VERSION ""

NS_ :

BS_:

BU_: AGSM ECM EVCU2 MCPA MCPB SGCP TCM

BO_ 1064 SGCP_DATA2: 64 SGCP
 SG_ SGCP_Temp : 7|8@0+ (1,-40) [-40|215] "°C"  EVCU2
 SG_ SGCP_Rotor_Temperature : 31|8@0+ (1,-40) [-40|215] "°C"  EVCU2
 SG_ SGCP_Inverter_Temp : 15|8@0+ (1,-40) [-40|215] "°C"  EVCU2
 SG_ SGCP_Control_Board_Temperature : 23|8@0+ (1,-40) [-40|215] "°C"  EVCU2
 SG_ MessageCounter_SGCP_DATA2 : 435|4@0+ (1,0) [0|15] ""  EVCU2
 SG_ CRC_SGCP_DATA2 : 447|8@0+ (1,0) [0|255] ""  EVCU2
 SG_ CLrDiagInfo_SGCP : 248|1@0+ (1,0) [0|1] ""  EVCU2
 SG_ SGCP_Service_Lamp_Request : 39|1@0+ (1,0) [0|1] ""  EVCU2
 SG_ Genrtr_PIM_DC_Side_Busbar_Temp : 55|8@0+ (1,-40) [-40|214] "°C"  EVCU2
 SG_ Genrtr_PIM_AC_Side_Busbar_Temp : 47|8@0+ (1,-40) [-40|214] "°C"  EVCU2

BO_ 263 PT_SYSTEM_FD_1: 64 EVCU2
 SG_ OptimdStrtReqdActr : 2|3@0+ (1,0) [0|7] ""  ECM
 SG_ OptimdEngStrtStpType : 7|5@0+ (1,0) [0|31] ""  ECM
 SG_ OptimdEngOnOffCmd : 15|1@0+ (1,0) [0|1] ""  ECM
 SG_ Hyb_ProducingTorque : 13|1@0+ (1,0) [0|1] ""  ECM
 SG_ HCPFuelDisable : 14|1@0+ (1,0) [0|1] ""  ECM
 SG_ PowertrainPrplsnActv_PT : 146|1@0+ (1,0) [0|1] "" Vector__XXX
 SG_ GearEngagedForDisplay_PT : 12|5@0+ (1,0) [0|31] ""  AGSM
 SG_ GearEngaged_PT : 132|4@0+ (1,0) [0|15] ""  MCPB
 SG_ ParkCmd_PT : 151|2@0+ (1,0) [0|3] ""  MCPB
 SG_ TransmissionFailSts_PT : 152|1@0+ (1,0) [0|1] ""  AGSM
 SG_ TerrainModeStat_PT : 119|5@0+ (1,0) [0|31] "" Vector__XXX
 SG_ ShiftLeverPosition_PT : 51|4@0+ (1,0) [0|15] ""  AGSM
 SG_ ShiftLeverLockReq_PT : 155|1@0+ (1,0) [0|1] ""  AGSM
 SG_ MessageCounter_PT_SYSTEM_FD_1 : 435|4@0+ (1,0) [0|15] "-"  MCPB,AGSM,ECM
 SG_ GearIndicationSts_PT : 153|1@0+ (1,0) [0|1] ""  AGSM
 SG_ GasPedalPositionFailSts_PT : 145|1@0+ (1,0) [0|1] ""  ECM
 SG_ GasPedalPosition_PT : 31|8@0+ (0.392,0) [0|99.96] "%"  ECM
 SG_ CRC_PT_SYSTEM_FD_1 : 447|8@0+ (1,0) [0|255] "-"  MCPB,AGSM,ECM
 SG_ APCM_Rq_PT : 137|2@0+ (1,0) [0|3] ""  AGSM

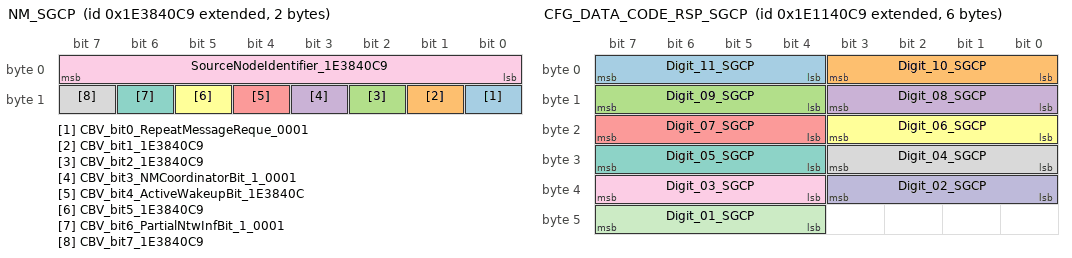
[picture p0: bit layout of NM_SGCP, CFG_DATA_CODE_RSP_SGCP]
BO_ 2654486729 NM_SGCP: 2 SGCP
 SG_ CBV_bit0_RepeatMessageReque_0001 : 8|1@0+ (1,0) [0|1] ""  EVCU2,MCPB,MCPA
 SG_ CBV_bit1_1E3840C9 : 9|1@0+ (1,0) [0|1] ""  EVCU2,MCPB,MCPA
 SG_ CBV_bit2_1E3840C9 : 10|1@0+ (1,0) [0|1] ""  EVCU2,MCPB,MCPA
 SG_ CBV_bit3_NMCoordinatorBit_1_0001 : 11|1@0+ (1,0) [0|1] ""  EVCU2,MCPB,MCPA
 SG_ CBV_bit4_ActiveWakeupBit_1E3840C : 12|1@0+ (1,0) [0|1] ""  EVCU2,MCPB,MCPA
 SG_ CBV_bit5_1E3840C9 : 13|1@0+ (1,0) [0|1] ""  EVCU2,MCPB,MCPA
 SG_ CBV_bit6_PartialNtwInfBit_1_0001 : 14|1@0+ (1,0) [0|1] ""  EVCU2,MCPB,MCPA
 SG_ CBV_bit7_1E3840C9 : 15|1@0+ (1,0) [0|1] ""  EVCU2,MCPB,MCPA
 SG_ SourceNodeIdentifier_1E3840C9 : 7|8@0+ (1,0) [0|255] "-"  EVCU2,MCPB,MCPA

BO_ 237 INVTARGET2: 32 EVCU2
 SG_ UDCMin_Unlim_SGCP : 7|16@0+ (0.01,0) [0|655.34] "V"  SGCP
 SG_ UDCMax_Unlim_SGCP : 23|16@0+ (0.01,0) [0|655.34] "V"  SGCP
 SG_ TqGrdtLim_SGCP : 55|16@0+ (0.1,0) [0|6553.4] "Nm/s"  SGCP
 SG_ TorqueCommand_SGCP : 100|13@0+ (0.125,-512) [-512|511.75] "Nm"  SGCP
 SG_ TargetMotorRPM_SGCP : 71|16@0+ (0.5,-16384) [-16384|16383.5] "rpm"  SGCP
 SG_ SpdGrdtLim_SGCP : 114|11@0+ (20,0) [0|40920] "rpm/s"  SGCP
 SG_ Mtr_6SO_Request_SGCP : 38|1@0+ (1,0) [0|1] ""  SGCP
 SG_ ModeCommand_SGCP : 119|4@0+ (1,0) [0|15] ""  SGCP
 SG_ MessageCounter_INVTARGET2 : 179|4@0+ (1,0) [0|15] ""  SGCP
 SG_ CRC_INVTARGET2 : 191|8@0+ (1,0) [0|255] ""  SGCP
 SG_ AEMD_Sclr_Gn_SGCP : 87|4@0+ (1.683,0) [0|25.245] ""  SGCP
 SG_ AEMD_MinOffset_SGCP : 83|12@0+ (0.125,-511.875) [-511.875|0] "Nm"  SGCP
 SG_ AEMD_MaxOffset_SGCP : 35|12@0+ (0.125,0) [0|511.875] "Nm"  SGCP
 SG_ Pwr_Electronic_Loop_FlwRate_SGCP : 135|8@0+ (0.1,0) [0|25.4] "LPM"  SGCP
 SG_ AEMD_Cutoff_FreqLow_SGCP : 151|8@0+ (0.1,4.5) [4.5|30] "Hz"  SGCP
 SG_ AEMD_Cutoff_FreqHigh_SGCP : 143|8@0+ (0.1,0) [0|25.5] "Hz"  SGCP

BO_ 2651930825 CFG_DATA_CODE_RSP_SGCP: 6 SGCP
 SG_ Digit_11_SGCP : 7|4@0+ (1,0) [0|15] "-"  EVCU2
 SG_ Digit_10_SGCP : 3|4@0+ (1,0) [0|15] "-"  EVCU2
 SG_ Digit_09_SGCP : 15|4@0+ (1,0) [0|15] "-"  EVCU2
 SG_ Digit_08_SGCP : 11|4@0+ (1,0) [0|15] "-"  EVCU2
 SG_ Digit_07_SGCP : 23|4@0+ (1,0) [0|15] "-"  EVCU2
 SG_ Digit_06_SGCP : 19|4@0+ (1,0) [0|15] "-"  EVCU2
 SG_ Digit_05_SGCP : 31|4@0+ (1,0) [0|15] "-"  EVCU2
 SG_ Digit_04_SGCP : 27|4@0+ (1,0) [0|15] "-"  EVCU2
 SG_ Digit_03_SGCP : 39|4@0+ (1,0) [0|15] "-"  EVCU2
 SG_ Digit_02_SGCP : 35|4@0+ (1,0) [0|15] "-"  EVCU2
 SG_ Digit_01_SGCP : 47|4@0+ (1,0) [0|15] "-"  EVCU2

BO_ 216 PT_ENERGY_FD_1: 64 EVCU2
 SG_ BatteryVoltage_Raw_PT : 97|10@0+ (0.2,0) [0|204.6] "V"  MCPB,MCPA

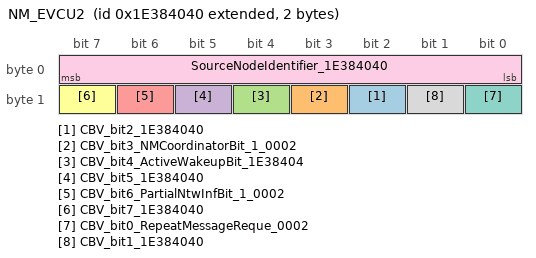
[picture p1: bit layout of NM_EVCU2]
BO_ 2654486592 NM_EVCU2: 2 EVCU2
 SG_ CBV_bit2_1E384040 : 10|1@0+ (1,0) [0|1] ""  SGCP,MCPB,MCPA,AGSM
 SG_ CBV_bit3_NMCoordinatorBit_1_0002 : 11|1@0+ (1,0) [0|1] ""  SGCP,MCPB,MCPA,AGSM
 SG_ CBV_bit4_ActiveWakeupBit_1E38404 : 12|1@0+ (1,0) [0|1] ""  SGCP,MCPB,MCPA,AGSM
 SG_ CBV_bit5_1E384040 : 13|1@0+ (1,0) [0|1] ""  SGCP,MCPB,MCPA,AGSM
 SG_ CBV_bit6_PartialNtwInfBit_1_0002 : 14|1@0+ (1,0) [0|1] ""  SGCP,MCPB,MCPA,AGSM
 SG_ CBV_bit7_1E384040 : 15|1@0+ (1,0) [0|1] ""  SGCP,MCPB,MCPA,AGSM
 SG_ CBV_bit0_RepeatMessageReque_0002 : 8|1@0+ (1,0) [0|1] ""  SGCP,MCPB,MCPA,AGSM
 SG_ CBV_bit1_1E384040 : 9|1@0+ (1,0) [0|1] ""  SGCP,MCPB,MCPA,AGSM
 SG_ SourceNodeIdentifier_1E384040 : 7|8@0+ (1,0) [0|255] "-"  SGCP,MCPB,MCPA,AGSM

BO_ 1811 REAL_TIME_CLOCK: 64 EVCU2
 SG_ Real_Time_Validity : 39|1@0+ (1,0) [0|1] ""  SGCP,MCPB,MCPA
 SG_ Real_Time_Clock : 7|32@0+ (1,0) [0|4294967295] ""  SGCP,MCPB,MCPA

BO_ 1070 SGCP_OBD_DTC: 32 SGCP
 SG_ SGCP_DTC_Stat2 : 26|3@0+ (1,0) [0|7] ""  EVCU2
 SG_ SGCP_DTC_Stat1 : 18|3@0+ (1,0) [0|7] ""  EVCU2
 SG_ SGCP_DTC_Idx2 : 31|5@0+ (1,0) [0|31] ""  EVCU2
 SG_ SGCP_DTC_Idx1 : 23|5@0+ (1,0) [0|31] ""  EVCU2
 SG_ SGCP_CalChar : 15|8@0+ (1,0) [0|255] ""  EVCU2
 SG_ SGCP_Cal_ID_Idx : 7|6@0+ (1,0) [0|63] ""  EVCU2
 SG_ MessageCounter_SGCP_OBD_DTC : 179|4@0+ (1,0) [0|15] "0"  EVCU2
 SG_ CRC_SGCP_OBD_DTC : 191|8@0+ (1,0) [0|255] "0"  EVCU2

BO_ 1065 MCPB_OBD_DTC: 32 MCPB
 SG_ MessageCounter_MCPB_OBD_DTC : 179|4@0+ (1,0) [0|15] "0"  EVCU2
 SG_ MCPB_DTC_Stat2 : 26|3@0+ (1,0) [0|7] ""  EVCU2
 SG_ MCPB_DTC_Stat1 : 18|3@0+ (1,0) [0|7] ""  EVCU2
 SG_ MCPB_DTC_Idx2 : 31|5@0+ (1,0) [0|31] ""  EVCU2
 SG_ MCPB_DTC_Idx1 : 23|5@0+ (1,0) [0|31] ""  EVCU2
 SG_ MCPB_CalChar : 15|8@0+ (1,0) [0|255] ""  EVCU2
 SG_ MCPB_Cal_ID_Idx : 7|6@0+ (1,0) [0|63] ""  EVCU2
 SG_ CRC_MCPB_OBD_DTC : 191|8@0+ (1,0) [0|255] "0"  EVCU2

BO_ 1057 MCPA_OBD_DTC: 32 MCPA
 SG_ MessageCounter_MCPA_OBD_DTC : 179|4@0+ (1,0) [0|15] "0"  EVCU2
 SG_ MCPA_DTC_Stat2 : 26|3@0+ (1,0) [0|7] ""  EVCU2
 SG_ MCPA_DTC_Stat1 : 18|3@0+ (1,0) [0|7] ""  EVCU2
 SG_ MCPA_DTC_Idx2 : 31|5@0+ (1,0) [0|31] ""  EVCU2
 SG_ MCPA_DTC_Idx1 : 23|5@0+ (1,0) [0|31] ""  EVCU2
 SG_ MCPA_CalChar : 15|8@0+ (1,0) [0|255] ""  EVCU2
 SG_ MCPA_Cal_ID_Idx : 7|6@0+ (1,0) [0|63] ""  EVCU2
 SG_ CRC_MCPA_OBD_DTC : 191|8@0+ (1,0) [0|255] "0"  EVCU2

BO_ 505 SGCP_STATUS: 32 SGCP
 SG_ SGCP_DerateReason_P : 7|4@0+ (1,0) [0|15] ""  EVCU2
 SG_ SGCP_DC_Voltage_P : 1|10@0+ (1,0) [0|1023] "V"  EVCU2
 SG_ SGCP_DC_Volt_V_P : 3|1@0+ (1,0) [0|1] ""  EVCU2
 SG_ SGCP_DC_Current_V_P : 2|1@0+ (1,0) [0|1] ""  EVCU2
 SG_ SGCP_DC_Current_P : 38|15@0+ (0.1,-1638.4) [-1638.4|1638.3] "A"  EVCU2
 SG_ SGCP_CoolantTemp_P : 18|11@0+ (0.1,-40) [-40|164.7] "°C"  EVCU2
 SG_ MC_SGCP_STATUS : 179|4@0+ (1,0) [0|15] "-"  EVCU2
 SG_ CRC_SGCP_STATUS : 191|8@0+ (1,0) [0|255] "-"  EVCU2

BO_ 295 SGCP_PROPULSION: 32 SGCP
 SG_ SGCP_Torque_Achieved_V_P : 54|1@0+ (1,0) [0|1] ""  EVCU2
 SG_ SGCP_Torque_Achieved_P : 21|14@0+ (0.125,-1023) [-1023|1024.875] "Nm"  EVCU2
 SG_ SGCP_TorqAchieved_AEMD_V_P : 71|1@0+ (1,0) [0|1] ""  EVCU2
 SG_ SGCP_TorqAchieved_AEMD_P : 85|14@0+ (0.125,-1023) [-1023|1024.875] "Nm"  EVCU2
 SG_ SGCP_SPT_Stat_P : 39|2@0+ (1,0) [0|3] ""  EVCU2
 SG_ SGCP_Spd_Lim_P : 135|16@0+ (1,-32767) [-32767|32768] "rpm"  EVCU2
 SG_ SGCP_RPM_V_P : 70|1@0+ (1,0) [0|1] ""  EVCU2
 SG_ SGCP_RPM_P : 7|16@0+ (1,-32768) [-32768|32767] "rpm"  EVCU2
 SG_ SGCP_MtrMinCpbltyTrq_P : 117|14@0+ (0.125,-1023) [-1023|1024.875] "Nm"  EVCU2
 SG_ SGCP_MtrMaxCpbltyTrq_P : 101|14@0+ (0.125,-1023) [-1023|1024.875] "Nm"  EVCU2
 SG_ SGCP_MtrIndex_P : 44|5@0+ (1,0) [0|31] "-"  EVCU2
 SG_ SGCP_MinTorq_P : 69|14@0+ (0.125,-1023) [-1023|1024.875] "Nm"  EVCU2
 SG_ SGCP_MaxTorq_P : 53|14@0+ (0.125,-1023) [-1023|1024.875] "Nm"  EVCU2
 SG_ SGCP_Invrtr_State_P : 183|4@0+ (1,0) [0|15] ""  EVCU2
 SG_ SGCP_InterlockSts_P : 103|2@0+ (1,0) [0|3] "-"  EVCU2
 SG_ SGCP_HV_CnctrOpn_Req_P : 119|1@0+ (1,0) [0|1] ""  EVCU2
 SG_ SGCP_Dschrge_Status_P : 87|2@0+ (1,0) [0|3] "-"  EVCU2
 SG_ SGCP_DeratingFactor_P : 37|6@0+ (0.02,0) [0|1.26] "-"  EVCU2
 SG_ SGCP_CpbltySpdDivVolt_P : 167|16@0+ (1,0) [0|65535] "rpm"  EVCU2
 SG_ SGCP_AccelRawV_P : 55|1@0+ (1,0) [0|1] ""  EVCU2
 SG_ SGCP_AccelRaw_P : 151|16@0+ (1,0) [0|65535] "rpm"  EVCU2
 SG_ SGCP_6SO_Status_P : 23|2@0+ (1,0) [0|3] ""  EVCU2
 SG_ SGCP_3PS_Pos_P : 118|1@0+ (1,0) [0|1] ""  EVCU2
 SG_ MC_SGCP_PROPULSION : 179|4@0+ (1,0) [0|15] "-"  EVCU2
 SG_ CRC_SGCP_PROPULSION : 191|8@0+ (1,0) [0|255] "-"  EVCU2

BO_ 504 MCPB_STATUS: 32 MCPB
 SG_ MCPB_DerateReason_P : 7|4@0+ (1,0) [0|15] "-"  EVCU2
 SG_ MCPB_DC_Voltage_P : 1|10@0+ (1,0) [0|1022] "V"  EVCU2
 SG_ MCPB_DC_Volt_V_P : 3|1@0+ (1,0) [0|1] ""  EVCU2
 SG_ MCPB_DC_Current_V_P : 2|1@0+ (1,0) [0|1] ""  EVCU2
 SG_ MCPB_DC_Current_P : 38|15@0+ (0.1,-1638.4) [-1638.4|1638.3] "A"  EVCU2
 SG_ MCPB_CoolantTemp_P : 18|11@0+ (0.1,-40) [-40|164.7] "°C"  EVCU2
 SG_ MC_MCPB_STATUS : 179|4@0+ (1,0) [0|15] "-"  EVCU2
 SG_ CRC_MCPB_STATUS : 191|8@0+ (1,0) [0|255] "-"  EVCU2

BO_ 294 MCPB_PROPULSION: 48 MCPB
 SG_ PlockFailSts_P : 179|3@0+ (1,0) [0|6] ""  EVCU2
 SG_ Plock_PosSensor_P : 196|3@0+ (1,0) [0|6] ""  EVCU2
 SG_ Plock_MotorPosSts_P : 188|3@0+ (1,0) [0|6] ""  EVCU2
 SG_ Plock_fdbk_sts_P : 191|3@0+ (1,0) [0|7] ""  EVCU2
 SG_ MPR_PosSensor_P : 199|3@0+ (1,0) [0|6] ""  EVCU2
 SG_ MCPB_Torque_Achieved_V_P : 54|1@0+ (1,0) [0|1] ""  EVCU2
 SG_ MCPB_Torque_Achieved_P : 21|14@0+ (0.125,-1023) [-1023|1024.875] "Nm"  EVCU2
 SG_ MCPB_TorqAchieved_AEMD_V_P : 71|1@0+ (1,0) [0|1] ""  EVCU2
 SG_ MCPB_TorqAchieved_AEMD_P : 85|14@0+ (0.125,-1023) [-1023|1024.875] "Nm"  EVCU2
 SG_ MCPB_SPT_Stat_P : 39|2@0+ (1,0) [0|3] ""  EVCU2
 SG_ MCPB_Spd_Lim_P : 135|16@0+ (1,-32767) [-32767|32678] "rpm"  EVCU2
 SG_ MCPB_RPM_V_P : 70|1@0+ (1,0) [0|1] ""  EVCU2
 SG_ MCPB_RPM_P : 7|16@0+ (1,-32768) [-32768|32767] "rpm"  EVCU2
 SG_ MCPB_MtrMinCpbltyTrq_P : 117|14@0+ (0.125,-1023) [-1023|1024.875] "Nm"  EVCU2
 SG_ MCPB_MtrMaxCpbltyTrq_P : 101|14@0+ (0.125,-1023) [-1023|1024.875] "Nm"  EVCU2
 SG_ MCPB_MtrIndex_P : 44|5@0+ (1,0) [0|31] ""  EVCU2
 SG_ MCPB_MinTorq_P : 69|14@0+ (0.125,-1023) [-1023|1024.875] "Nm"  EVCU2
 SG_ MCPB_MaxTorq_P : 53|14@0+ (0.125,-1023) [-1023|1024.875] "Nm"  EVCU2
 SG_ MCPB_Invrtr_State_P : 183|4@0+ (1,0) [0|15] ""  EVCU2
 SG_ MCPB_InterlockSts_P : 103|2@0+ (1,0) [0|3] ""  EVCU2
 SG_ MCPB_HV_CnctrOpn_Req_P : 119|1@0+ (1,0) [0|1] ""  EVCU2
 SG_ MCPB_Dschrge_Status_P : 87|2@0+ (1,0) [0|3] ""  EVCU2
 SG_ MCPB_DeratingFactor_P : 37|6@0+ (0.02,0) [0|1.26] ""  EVCU2
 SG_ MCPB_CpbltySpdDivVolt_P : 167|16@0+ (1,0) [0|65535] "V"  EVCU2
 SG_ MCPB_AccelRawV_P : 55|1@0+ (1,0) [0|1] ""  EVCU2
 SG_ MCPB_AccelRaw_P : 151|16@0+ (1,0) [0|65535] ""  EVCU2
 SG_ MCPB_6SO_Status_P : 23|2@0+ (1,0) [0|3] ""  EVCU2
 SG_ MCPB_3PS_Pos_P : 118|1@0+ (1,0) [0|1] ""  EVCU2
 SG_ MC_MCPB_PROPULSION : 307|4@0+ (1,0) [0|15] "-"  EVCU2
 SG_ CRC_MCPB_PROPULSION : 319|8@0+ (1,0) [0|255] "-"  EVCU2

BO_ 503 MCPA_STATUS: 32 MCPA
 SG_ MCPA_DerateReason_P : 7|4@0+ (1,0) [0|15] ""  EVCU2
 SG_ MCPA_DC_Voltage_P : 1|10@0+ (1,0) [0|1023] "V"  EVCU2
 SG_ MCPA_DC_Volt_V_P : 3|1@0+ (1,0) [0|1] ""  EVCU2
 SG_ MCPA_DC_Current_V_P : 2|1@0+ (1,0) [0|1] ""  EVCU2
 SG_ MCPA_DC_Current_P : 38|15@0+ (0.1,-1638.4) [-1638.4|1638.3] "A"  EVCU2
 SG_ MCPA_CoolantTemp_P : 18|11@0+ (0.1,-40) [-40|164.7] "C"  EVCU2
 SG_ MC_MCPA_STATUS : 179|4@0+ (1,0) [0|15] "-"  EVCU2
 SG_ CRC_MCPA_STATUS : 191|8@0+ (1,0) [0|255] "-"  EVCU2

BO_ 293 MCPA_PROPULSION: 32 MCPA
 SG_ MCPA_Torque_Achieved_V_P : 54|1@0+ (1,0) [0|1] ""  EVCU2
 SG_ MCPA_Torque_Achieved_P : 21|14@0+ (0.125,-1023) [-1023|1024.875] "Nm"  EVCU2
 SG_ MCPA_TorqAchieved_AEMD_V_P : 71|1@0+ (1,0) [0|1] ""  EVCU2
 SG_ MCPA_TorqAchieved_AEMD_P : 85|14@0+ (0.125,-1023) [-1023|1024.875] "Nm"  EVCU2
 SG_ MCPA_SPT_Stat_P : 39|2@0+ (1,0) [0|3] ""  EVCU2
 SG_ MCPA_Spd_Lim_P : 135|16@0+ (1,-32767) [-32767|32768] "rpm"  EVCU2
 SG_ MCPA_RPM_V_P : 70|1@0+ (1,0) [0|1] ""  EVCU2
 SG_ MCPA_RPM_P : 7|16@0+ (1,-32768) [-32768|32767] "rpm"  EVCU2
 SG_ MCPA_MtrMinCpbltyTrq_P : 117|14@0+ (0.125,-1023) [-1023|1024.875] "Nm"  EVCU2
 SG_ MCPA_MtrMaxCpbltyTrq_P : 101|14@0+ (0.125,-1023) [-1023|1024.875] "Nm"  EVCU2
 SG_ MCPA_MtrIndex_P : 44|5@0+ (1,0) [0|31] ""  EVCU2
 SG_ MCPA_MinTorq_P : 69|14@0+ (0.125,-1023) [-1023|1024.875] "Nm"  EVCU2
 SG_ MCPA_MaxTorq_P : 53|14@0+ (0.125,-1023) [-1023|1024.875] "Nm"  EVCU2
 SG_ MCPA_Invrtr_State_P : 183|4@0+ (1,0) [0|15] ""  EVCU2
 SG_ MCPA_InterlockSts_P : 103|2@0+ (1,0) [0|3] ""  EVCU2
 SG_ MCPA_HV_CnctrOpn_Req_P : 119|1@0+ (1,0) [0|1] ""  EVCU2
 SG_ MCPA_Dschrge_Status_P : 87|2@0+ (1,0) [0|3] ""  EVCU2
 SG_ MCPA_DeratingFactor_P : 37|6@0+ (0.02,0) [0|1.26] ""  EVCU2
 SG_ MCPA_CpbltySpdDivVolt_P : 167|16@0+ (1,0) [0|65535] "rpm"  EVCU2
 SG_ MCPA_AccelRawV_P : 55|1@0+ (1,0) [0|1] ""  EVCU2
 SG_ MCPA_AccelRaw_P : 151|16@0+ (1,0) [0|65535] ""  EVCU2
 SG_ MCPA_6SO_Status_P : 23|2@0+ (1,0) [0|3] ""  EVCU2
 SG_ MCPA_3PS_Pos_P : 118|1@0+ (1,0) [0|1] ""  EVCU2
 SG_ MC_MCPA_PROPULSION : 179|4@0+ (1,0) [0|15] "-"  EVCU2
 SG_ CRC_MCPA_PROPULSION : 191|8@0+ (1,0) [0|255] "-"  EVCU2

BO_ 297 INVTARGET_PROPULSION2: 48 EVCU2
 SG_ UDCMin_Unlim_SGCP_P : 127|16@0+ (0.01,0) [0|655.35] "V"  SGCP
 SG_ UDCMin_Unlim_MCPB_P : 111|16@0+ (0.01,0) [0|655.35] "V"  MCPB
 SG_ UDCMin_Unlim_MCPA_P : 23|16@0+ (0.01,0) [0|655.35] "V"  MCPA
 SG_ UDCMax_Unlim_SGCP_P : 159|16@0+ (0.01,0) [0|655.35] "V"  SGCP
 SG_ UDCMax_Unlim_MCPB_P : 143|16@0+ (0.01,0) [0|655.35] "V"  MCPB
 SG_ UDCMax_Unlim_MCPA_P : 39|16@0+ (0.01,0) [0|655.35] "V"  MCPA
 SG_ TqGrdtLim_SGCP_P : 95|16@0+ (0.1,0) [0|6553.5] "Nm/s"  SGCP
 SG_ TqGrdtLim_MCPB_P : 79|16@0+ (0.1,0) [0|6553.5] "Nm/s"  MCPB
 SG_ TqGrdtLim_MCPA_P : 7|16@0+ (0.1,0) [0|6553.5] "Nm/s"  MCPA
 SG_ SpdGrdtLim_SGCP_P : 258|11@0+ (20,0) [0|40940] "rpm/s"  SGCP
 SG_ SpdGrdtLim_MCPB_P : 277|11@0+ (20,0) [0|40940] "rpm/s"  MCPB
 SG_ SpdGrdtLim_MCPA_P : 282|11@0+ (20,0) [0|40940] "rpm/s"  MCPA
 SG_ Pwr_Electr_Loop_FlwRate_SGCP_P : 71|8@0+ (0.1,0) [0|25.5] "LPM"  SGCP
 SG_ Pwr_Electr_Loop_FlwRate_MCPB_P : 63|8@0+ (0.1,0) [0|25.5] "LPM"  MCPB
 SG_ Pwr_Electr_Loop_FlwRate_MCPA_P : 55|8@0+ (0.1,0) [0|25.5] "LPM"  MCPA
 SG_ MC_INVTARGET_PROPULSION2 : 307|4@0+ (1,0) [0|15] "-"  SGCP,MCPB,MCPA
 SG_ EVCU_MotorC_Speed : 207|16@0+ (1,-32768) [-32768|32767] "rpm"  SGCP
 SG_ EVCU_MotorB_Speed : 191|16@0+ (1,-32768) [-32768|32767] "rpm"  MCPB
 SG_ EVCU_MotorA_Speed : 175|16@0+ (1,-32768) [-32768|32767] "rpm"  MCPA
 SG_ CRC_INVTARGET_PROPULSION2 : 319|8@0+ (1,0) [0|255] "-"  SGCP,MCPB,MCPA

BO_ 296 INVTARGET_PROPULSION1: 48 EVCU2
 SG_ VehicleSpeedVSOSig_P : 55|13@0+ (0.0625,0) [0|511.875] "Km/h"  SGCP,MCPB,MCPA
 SG_ TorqueCommand_SGCP_P : 175|14@0+ (0.125,-1023) [-1023|1024.875] "Nm"  SGCP
 SG_ TorqueCommand_MCPB_P : 157|14@0+ (0.125,-1023) [-1023|1024.875] "Nm"  MCPB
 SG_ TorqueCommand_MCPA_P : 139|14@0+ (0.125,-1023) [-1023|1024.875] "Nm"  MCPA
 SG_ TargetMotorRPM_SGCP_P : 39|16@0+ (0.5,-16384) [-16384|16383.5] "rpm"  SGCP
 SG_ TargetMotorRPM_MCPB_P : 23|16@0+ (0.5,-16384) [-16384|16383.5] "rpm"  MCPB
 SG_ TargetMotorRPM_MCPA_P : 7|16@0+ (0.5,-16384) [-16384|16383.5] "rpm"  MCPA
 SG_ ShiftLeverPosition_P : 273|4@0+ (1,0) [0|15] ""  MCPB
 SG_ ParkCmd_PT_P : 259|2@0+ (1,0) [0|3] ""  MCPB
 SG_ Mtr_6SO_Request_SGCP_P : 257|1@0+ (1,0) [0|1] ""  SGCP
 SG_ Mtr_6SO_Request_MCPB_P : 248|1@0+ (1,0) [0|1] ""  MCPB
 SG_ Mtr_6SO_Request_MCPA_P : 249|1@0+ (1,0) [0|1] ""  MCPA
 SG_ ModeCommand_SGCP_P : 239|4@0+ (1,0) [0|15] ""  SGCP
 SG_ ModeCommand_MCPB_P : 227|4@0+ (1,0) [0|15] ""  MCPB
 SG_ ModeCommand_MCPA_P : 231|4@0+ (1,0) [0|15] ""  MCPA
 SG_ MC_INVTARGET_PROPULSION1 : 307|4@0+ (1,0) [0|15] ""  SGCP,MCPB,MCPA
 SG_ CRC_INVTARGET_PROPULSION1 : 319|8@0+ (1,0) [0|255] "-"  SGCP,MCPB,MCPA
 SG_ CmdIgnSts_P : 58|3@0+ (1,0) [0|7] ""  SGCP,MCPB,MCPA
 SG_ BPCM_HV_TractionBusVoltage_P : 271|11@0+ (1,0) [0|2047] "V"  SGCP,MCPB,MCPA
 SG_ BPCM_HV_Trac_Main_Contac_Sts_P : 276|3@0+ (1,0) [0|7] ""  SGCP,MCPB,MCPA
 SG_ AEMD_Sclr_Gn_SGCP_P : 263|4@0+ (1.683,0) [0|25.245] ""  SGCP
 SG_ AEMD_Sclr_Gn_MCPB_P : 242|9@0+ (0.01,0) [0|5.11] "rad/s"  MCPB
 SG_ AEMD_Sclr_Gn_MCPA_P : 235|9@0+ (0.01,0) [0|5.11] "rad/s"  MCPA
 SG_ AEMD_MinOffset_SGCP_P : 285|14@0+ (0.125,-1023) [-1023|1024.875] "Nm"  SGCP
 SG_ AEMD_MinOffset_MCPB_P : 195|14@0+ (0.125,-1023) [-1023|1024.875] "Nm"  MCPB
 SG_ AEMD_MinOffset_MCPA_P : 119|14@0+ (0.125,-1023) [-1023|1024.875] "Nm"  MCPA
 SG_ AEMD_MaxOffset_SGCP_P : 177|14@0+ (0.125,-1023) [-1023|1024.875] "Nm"  SGCP
 SG_ AEMD_MaxOffset_MCPB_P : 213|14@0+ (0.125,-1023) [-1023|1024.875] "Nm"  MCPB
 SG_ AEMD_MaxOffset_MCPA_P : 121|14@0+ (0.125,-1023) [-1023|1024.875] "Nm"  MCPA
 SG_ AEMD_Cutoff_FreqLow_SGCP_P : 103|8@0+ (0.1,4.5) [4.5|30] "Hz"  SGCP
 SG_ AEMD_Cutoff_FreqLow_MCPB_P : 87|8@0+ (0.1,4.5) [4.5|30] "Hz"  MCPB
 SG_ AEMD_Cutoff_FreqLow_MCPA_P : 71|8@0+ (0.1,4.5) [4.5|30] "Hz"  MCPA
 SG_ AEMD_Cutoff_FreqHigh_SGCP_P : 111|8@0+ (0.1,0) [0|25.5] "Hz"  SGCP
 SG_ AEMD_Cutoff_FreqHigh_MCPB_P : 95|8@0+ (0.1,0) [0|25.5] "Hz"  MCPB
 SG_ AEMD_Cutoff_FreqHigh_MCPA_P : 79|8@0+ (0.1,0) [0|25.5] "Hz"  MCPA

CM_ SG_ 1064 SGCP_Temp "SGCP temperature";
CM_ SG_ 1064 SGCP_Rotor_Temperature "Rotor Temperature from Motor";
CM_ SG_ 1064 SGCP_Inverter_Temp "SGCP Inverter Temperature";
CM_ SG_ 1064 SGCP_Control_Board_Temperature "Control Board temperature from Motor";
CM_ SG_ 1064 MessageCounter_SGCP_DATA2 "This signal is a counter used for safety checks strategies. This counter is incremented of 1 (one) unit at each frame transmission.";
CM_ SG_ 1064 CRC_SGCP_DATA2 "CRC according to SAE J1850 standard at each frame transmission.";
CM_ SG_ 1064 CLrDiagInfo_SGCP "Legislative Diagnostic Clear information for SGCP";
CM_ SG_ 1064 SGCP_Service_Lamp_Request "The Service Light Request from the SGCP";
CM_ SG_ 1064 Genrtr_PIM_DC_Side_Busbar_Temp "Generator busbar temperature in DC Side";
CM_ SG_ 1064 Genrtr_PIM_AC_Side_Busbar_Temp "Generator busbar temperature in AC Side";
CM_ SG_ 263 OptimdStrtReqdActr "Signal to determine which actuator will be used to spin/crank the engine";
CM_ SG_ 263 OptimdEngStrtStpType "This signal indicates the type of engine start";
CM_ SG_ 263 OptimdEngOnOffCmd "Signal to give the final command on if the engine should be On or Off";
CM_ SG_ 263 Hyb_ProducingTorque "This signal indicates that hybrid control unit is declaring enging producing torque";
CM_ SG_ 263 HCPFuelDisable "Signal to disable fueling for engine ramp or ramp down purposes";
CM_ SG_ 263 PowertrainPrplsnActv_PT "Powertrain Propulsion System Status";
CM_ SG_ 263 GearEngagedForDisplay_PT "Transmission Gear Engaged signal for the instrument cluster display";
CM_ SG_ 263 GearEngaged_PT "Current engaged gear";
CM_ SG_ 263 ParkCmd_PT "Park Command for MCP.";
CM_ SG_ 263 TransmissionFailSts_PT "Transmission Failure Status";
CM_ SG_ 263 TerrainModeStat_PT "Terrain Mode";
CM_ SG_ 263 ShiftLeverPosition_PT "Shift Lever Position";
CM_ SG_ 263 ShiftLeverLockReq_PT "Shift Lever Lock Request";
CM_ SG_ 263 MessageCounter_PT_SYSTEM_FD_1 "This signal is a counter used for safety checks strategies. This counter is incremented of 1 (one) unit at each frame transmission.";
CM_ SG_ 263 GearIndicationSts_PT "Gear Indication Status";
CM_ SG_ 263 GasPedalPositionFailSts_PT "Gas Pedal Position Failure Status";
CM_ SG_ 263 GasPedalPosition_PT "Gas Pedal Position in percentage";
CM_ SG_ 263 CRC_PT_SYSTEM_FD_1 "CRC according to SAE J1850 standard at each frame transmission.";
CM_ SG_ 263 APCM_Rq_PT "Auto position correction mode request";
CM_ SG_ 2654486729 CBV_bit0_RepeatMessageReque_0001 "Repeat Message Request Bit";
CM_ SG_ 2654486729 CBV_bit3_NMCoordinatorBit_1_0001 "NM Coordinator Sleep Bit";
CM_ SG_ 2654486729 CBV_bit4_ActiveWakeupBit_1E3840C "Active Wakeup Bit";
CM_ SG_ 2654486729 CBV_bit6_PartialNtwInfBit_1_0001 "Partial Network Information Bit (PNI)";
CM_ SG_ 2654486729 SourceNodeIdentifier_1E3840C9 "Source Node Identifier";
CM_ SG_ 237 UDCMin_Unlim_SGCP "Minimum DC voltage limit before linear generator derating Consider Max or Min torque. Default 36V";
CM_ SG_ 237 UDCMax_Unlim_SGCP "Maximum DC voltage limit before linear generator derating Consider Max or Min torque. Default 52V";
CM_ SG_ 237 TqGrdtLim_SGCP "Positive or Negative Torque Gradient applied for Torque Control Mode and Speed Control Mode. Default 1000Nm/s";
CM_ SG_ 237 TorqueCommand_SGCP "Torque command for SGCP";
CM_ SG_ 237 TargetMotorRPM_SGCP "Target Motor RPM for SGCP";
CM_ SG_ 237 SpdGrdtLim_SGCP "Positive or negative (symetric) Speed Request Gradient applicable on both sign only for Speed Control Mode. Default 25,000 rpm/s";
CM_ SG_ 237 Mtr_6SO_Request_SGCP "Six Switch Open Request  for SGCP (1=RequestActive; 0=RequestNotActive)";
CM_ SG_ 237 ModeCommand_SGCP "Mode command for SGCP";
CM_ SG_ 237 MessageCounter_INVTARGET2 "This signal is a counter used for safety checks strategies. This counter is incremented of 1 (one) unit at each frame transmission.";
CM_ SG_ 237 CRC_INVTARGET2 "CRC according to SAE J1850 standard at each frame transmission.";
CM_ SG_ 237 AEMD_Sclr_Gn_SGCP "SGCP AEMD Scalar Gain";
CM_ SG_ 237 AEMD_MinOffset_SGCP "MCPC AEMD Min Offset";
CM_ SG_ 237 AEMD_MaxOffset_SGCP "SGCP AEMD Max Offset";
CM_ SG_ 237 Pwr_Electronic_Loop_FlwRate_SGCP "Power electronics coolant flow rate";
CM_ SG_ 237 AEMD_Cutoff_FreqLow_SGCP "AEMD cut-off Frequency Low for SGCP";
CM_ SG_ 237 AEMD_Cutoff_FreqHigh_SGCP "AEMD cut-off Frequency High for SGCP";
CM_ SG_ 216 BatteryVoltage_Raw_PT "Battery Voltage value measured from the electrified powertrain control module pin";
CM_ SG_ 1811 Real_Time_Validity "EVCU Real Time Clock Validity";
CM_ SG_ 1811 Real_Time_Clock "EVCU Real Time Clock";
CM_ SG_ 1070 SGCP_DTC_Stat2 "SGCP diagnostic trouble code status 1";
CM_ SG_ 1070 SGCP_DTC_Stat1 "SGCP diagnostic trouble code status 1";
CM_ SG_ 1070 SGCP_DTC_Idx2 "SGCP diagnostic trouble code index 2";
CM_ SG_ 1070 SGCP_DTC_Idx1 "SGCP diagnostic trouble code index 1";
CM_ SG_ 1070 SGCP_CalChar "SGCP Calibration CVN";
CM_ SG_ 1070 SGCP_Cal_ID_Idx "SGCP Calibration ID Index";
CM_ SG_ 1070 MessageCounter_SGCP_OBD_DTC "This signal is a counter used for safety checks strategies. This counter is incremented of 1 (one) unit at each frame transmission.";
CM_ SG_ 1070 CRC_SGCP_OBD_DTC "CRC according to SAE J1850 standard at each frame transmission.";
CM_ SG_ 1065 MessageCounter_MCPB_OBD_DTC "This signal is a counter used for safety checks strategies. This counter is incremented of 1 (one) unit at each frame transmission.";
CM_ SG_ 1065 MCPB_DTC_Stat2 "MCPB diagnostic trouble code status 1";
CM_ SG_ 1065 MCPB_DTC_Stat1 "MCPB diagnostic trouble code status 1";
CM_ SG_ 1065 MCPB_DTC_Idx2 "MCPB diagnostic trouble code index 2";
CM_ SG_ 1065 MCPB_DTC_Idx1 "MCPB diagnostic trouble code index 1";
CM_ SG_ 1065 MCPB_CalChar "MCPB Calibration CVN";
CM_ SG_ 1065 MCPB_Cal_ID_Idx "MCPB Calibration ID Index";
CM_ SG_ 1065 CRC_MCPB_OBD_DTC "CRC according to SAE J1850 standard at each frame transmission.";
CM_ SG_ 1057 MessageCounter_MCPA_OBD_DTC "This signal is a counter used for safety checks strategies. This counter is incremented of 1 (one) unit at each frame transmission.";
CM_ SG_ 1057 MCPA_DTC_Stat2 "MCPA diagnostic trouble code status 1";
CM_ SG_ 1057 MCPA_DTC_Stat1 "MCPA diagnostic trouble code status 1";
CM_ SG_ 1057 MCPA_DTC_Idx2 "MCPA diagnostic trouble code index 2";
CM_ SG_ 1057 MCPA_DTC_Idx1 "MCPA diagnostic trouble code index 1";
CM_ SG_ 1057 MCPA_CalChar "MCPA Calibration CVN";
CM_ SG_ 1057 MCPA_Cal_ID_Idx "MCPA Calibration ID Index";
CM_ SG_ 1057 CRC_MCPA_OBD_DTC "CRC according to SAE J1850 standard at each frame transmission.";
CM_ SG_ 505 SGCP_DerateReason_P "Inverter Derating Reason";
CM_ SG_ 505 SGCP_DC_Voltage_P "Inverter Generator DC Voltage.";
CM_ SG_ 505 SGCP_DC_Volt_V_P "SGCP DC current  validity, [1] = True";
CM_ SG_ 505 SGCP_DC_Current_V_P "SGCP DC current  validity, [1] = True";
CM_ SG_ 505 SGCP_DC_Current_P "SGCP DC Current";
CM_ SG_ 505 SGCP_CoolantTemp_P "PIM Coolant Temperature";
CM_ SG_ 505 MC_SGCP_STATUS "Message counter according to SAE J1850 standard that has to be calculated from bit 63 to bit 8 at each frame transmission.";
CM_ SG_ 505 CRC_SGCP_STATUS "CRC according to SAE J1850 standard that has to be calculated from bit 63 to bit 8 at each frame transmission.";
CM_ SG_ 295 SGCP_Torque_Achieved_V_P "Achieved Torque value Validity, [1] = True";
CM_ SG_ 295 SGCP_Torque_Achieved_P "SGCP Torque Achieved";
CM_ SG_ 295 SGCP_TorqAchieved_AEMD_V_P "Motor Torque Achieved Validity";
CM_ SG_ 295 SGCP_TorqAchieved_AEMD_P "Motor Torque Achieved without AEMD";
CM_ SG_ 295 SGCP_SPT_Stat_P "Inverter Isolation Status";
CM_ SG_ 295 SGCP_Spd_Lim_P "Limited motor speed during reduced performance from SGCP";
CM_ SG_ 295 SGCP_RPM_V_P "SGCP Speed Validity, [1] = True";
CM_ SG_ 295 SGCP_RPM_P "Motor A Speed Raw";
CM_ SG_ 295 SGCP_MtrMinCpbltyTrq_P "Generator Min Capability Torque";
CM_ SG_ 295 SGCP_MtrMaxCpbltyTrq_P "Generator Max Capability Torque";
CM_ SG_ 295 SGCP_MtrIndex_P "Generator Capability Curve Array Index";
CM_ SG_ 295 SGCP_MinTorq_P "Generator Minimum Torque";
CM_ SG_ 295 SGCP_MaxTorq_P "Generator Maximum Torque";
CM_ SG_ 295 SGCP_Invrtr_State_P "Inverter State of Operation of SGCP";
CM_ SG_ 295 SGCP_InterlockSts_P "SGCP interlock state";
CM_ SG_ 295 SGCP_HV_CnctrOpn_Req_P "HV Battery pack contactor request";
CM_ SG_ 295 SGCP_Dschrge_Status_P "The active discharge status of SGCP";
CM_ SG_ 295 SGCP_DeratingFactor_P "Generator Derating Factor";
CM_ SG_ 295 SGCP_CpbltySpdDivVolt_P "Generator Speed at Capability Curve";
CM_ SG_ 295 SGCP_AccelRawV_P "Generator Acceleration Validity";
CM_ SG_ 295 SGCP_AccelRaw_P "Generator Acceleration";
CM_ SG_ 295 SGCP_6SO_Status_P "SGCP 6SO Status";
CM_ SG_ 295 SGCP_3PS_Pos_P "3 phase motor short possible from SGCP; True = [1]";
CM_ SG_ 295 MC_SGCP_PROPULSION "Message counter according to SAE J1850 standard that has to be calculated from bit 63 to bit 8 at each frame transmission.";
CM_ SG_ 295 CRC_SGCP_PROPULSION "CRC according to SAE J1850 standard that has to be calculated from bit 63 to bit 8 at each frame transmission.";
CM_ SG_ 504 MCPB_DerateReason_P "Inverter Derating Reason.";
CM_ SG_ 504 MCPB_DC_Voltage_P "This signal indicates the Inverter Rear Right DC Voltage.";
CM_ SG_ 504 MCPB_DC_Volt_V_P "Achieved Torque value Validity, [1] = True";
CM_ SG_ 504 MCPB_DC_Current_V_P "Achieved Torque value Validity, [1] = True";
CM_ SG_ 504 MCPB_DC_Current_P "Motor B DC Current";
CM_ SG_ 504 MCPB_CoolantTemp_P "PIM Coolant Temperature";
CM_ SG_ 504 MC_MCPB_STATUS "Message counter according to SAE J1850 standard that has to be calculated from bit 63 to bit 8 at each frame transmission.";
CM_ SG_ 504 CRC_MCPB_STATUS "CRC according to SAE J1850 standard that has to be calculated from bit 63 to bit 8 at each frame transmission.";
CM_ SG_ 294 PlockFailSts_P "Park Lock Fail Sts";
CM_ SG_ 294 Plock_PosSensor_P "Par lock physical position sensor feedback";
CM_ SG_ 294 Plock_MotorPosSts_P "Park lock motor position status";
CM_ SG_ 294 Plock_fdbk_sts_P "Park lock status";
CM_ SG_ 294 MPR_PosSensor_P "Manual Park Release sensor feedback";
CM_ SG_ 294 MCPB_Torque_Achieved_V_P "Achieved Torque value Validity, [1] = True";
CM_ SG_ 294 MCPB_Torque_Achieved_P "Motr B Torque Achieved";
CM_ SG_ 294 MCPB_TorqAchieved_AEMD_V_P "Motor Torque Achieved Validity";
CM_ SG_ 294 MCPB_TorqAchieved_AEMD_P "Motor Torque Achieved";
CM_ SG_ 294 MCPB_SPT_Stat_P "Inverter Isolation Status";
CM_ SG_ 294 MCPB_Spd_Lim_P "Limited motor speed during reduced performance from MCP B";
CM_ SG_ 294 MCPB_RPM_V_P "Motor B Speed Validity, [1] = True";
CM_ SG_ 294 MCPB_RPM_P "Motor B Speed Raw";
CM_ SG_ 294 MCPB_MtrMinCpbltyTrq_P "Motor B Min Capability Torque";
CM_ SG_ 294 MCPB_MtrMaxCpbltyTrq_P "Motor B Max Capability Torque";
CM_ SG_ 294 MCPB_MtrIndex_P "Motor B Capability Curve Array Index";
CM_ SG_ 294 MCPB_MinTorq_P "Motor B Minimum Torque";
CM_ SG_ 294 MCPB_MaxTorq_P "Motor B Maximum Torque";
CM_ SG_ 294 MCPB_Invrtr_State_P "Inverter State of Operation of Motor B";
CM_ SG_ 294 MCPB_InterlockSts_P "Rear right inverter interlock state";
CM_ SG_ 294 MCPB_HV_CnctrOpn_Req_P "HV Battery pack contactor request";
CM_ SG_ 294 MCPB_Dschrge_Status_P "The active discharge status of MCPB";
CM_ SG_ 294 MCPB_DeratingFactor_P "Motor B Derating Factor";
CM_ SG_ 294 MCPB_CpbltySpdDivVolt_P "Motor B Speed at Capability Curve";
CM_ SG_ 294 MCPB_AccelRawV_P "Motor B Acceleration Validity";
CM_ SG_ 294 MCPB_AccelRaw_P "Motor B Acceleration";
CM_ SG_ 294 MCPB_6SO_Status_P "Motor B 6SO Status";
CM_ SG_ 294 MCPB_3PS_Pos_P "3 phase motor short possible from MCP B; True = [1]";
CM_ SG_ 294 MC_MCPB_PROPULSION "Message counter according to SAE J1850 standard that has to be calculated from bit 63 to bit 8 at each frame transmission.";
CM_ SG_ 294 CRC_MCPB_PROPULSION "CRC according to SAE J1850 standard that has to be calculated from bit 63 to bit 8 at each frame transmission.";
CM_ SG_ 503 MCPA_DerateReason_P "Inverter Derating Reason";
CM_ SG_ 503 MCPA_DC_Voltage_P "Inverter Front DC Voltage.";
CM_ SG_ 503 MCPA_DC_Volt_V_P "Motor A DC current validity, [1] = True";
CM_ SG_ 503 MCPA_DC_Current_V_P "Motor A DC current validity, [1] = True";
CM_ SG_ 503 MCPA_DC_Current_P "Motor A DC Current";
CM_ SG_ 503 MCPA_CoolantTemp_P "PIM Coolant Temperature";
CM_ SG_ 503 MC_MCPA_STATUS "Message counter according to SAE J1850 standard that has to be calculated from bit 63 to bit 8 at each frame transmission.";
CM_ SG_ 503 CRC_MCPA_STATUS "CRC according to SAE J1850 standard that has to be calculated from bit 63 to bit 8 at each frame transmission.";
CM_ SG_ 293 MCPA_Torque_Achieved_V_P "Achieved Torque value Validity, [1] = True";
CM_ SG_ 293 MCPA_Torque_Achieved_P "Motor A Torque Achieved";
CM_ SG_ 293 MCPA_TorqAchieved_AEMD_V_P "Motor Torque Achieved Validity";
CM_ SG_ 293 MCPA_TorqAchieved_AEMD_P "Motor Torque Achieved without AEMD";
CM_ SG_ 293 MCPA_SPT_Stat_P "Inverter Isolation Status";
CM_ SG_ 293 MCPA_Spd_Lim_P "Limited motor speed during reduced performance from MCPA";
CM_ SG_ 293 MCPA_RPM_V_P "Motor A Speed Validity, [1] = True";
CM_ SG_ 293 MCPA_RPM_P "Motor A Speed Raw";
CM_ SG_ 293 MCPA_MtrMinCpbltyTrq_P "Motor A Min Capability Torque";
CM_ SG_ 293 MCPA_MtrMaxCpbltyTrq_P "Motor A Max Capability Torque";
CM_ SG_ 293 MCPA_MtrIndex_P "Motor A Capability Curve Array Index";
CM_ SG_ 293 MCPA_MinTorq_P "Motor A Minimum Torque";
CM_ SG_ 293 MCPA_MaxTorq_P "Motor A Maximum Torque";
CM_ SG_ 293 MCPA_Invrtr_State_P "Inverter State of Operation of Motor A";
CM_ SG_ 293 MCPA_InterlockSts_P "Front inverter interlock state";
CM_ SG_ 293 MCPA_HV_CnctrOpn_Req_P "HV Battery pack contactor request";
CM_ SG_ 293 MCPA_Dschrge_Status_P "The active discharge status of MCPA";
CM_ SG_ 293 MCPA_DeratingFactor_P "Motor A Derating Factor";
CM_ SG_ 293 MCPA_CpbltySpdDivVolt_P "Motor A Speed at Capability Curve";
CM_ SG_ 293 MCPA_AccelRawV_P "Motor A Acceleration Validity";
CM_ SG_ 293 MCPA_AccelRaw_P "Motor A Acceleration";
CM_ SG_ 293 MCPA_6SO_Status_P "Motor A 6SO Status";
CM_ SG_ 293 MCPA_3PS_Pos_P "3 phase motor short possible from MCP B; True = [1]";
CM_ SG_ 293 MC_MCPA_PROPULSION "Message counter according to SAE J1850 standard that has to be calculated from bit 63 to bit 8 at each frame transmission.";
CM_ SG_ 293 CRC_MCPA_PROPULSION "CRC according to SAE J1850 standard that has to be calculated from bit 63 to bit 8 at each frame transmission.";
CM_ SG_ 297 UDCMin_Unlim_SGCP_P "Minimum DC voltage limit before linear generator derating Consider Max or Min torque. Default 36V";
CM_ SG_ 297 UDCMin_Unlim_MCPB_P "Minimum DC voltage limit before linear generator derating Consider Max or Min torque. Default 36V";
CM_ SG_ 297 UDCMin_Unlim_MCPA_P "Minimum DC voltage limit before linear generator derating Consider Max or Min torque. Default 36V";
CM_ SG_ 297 UDCMax_Unlim_SGCP_P "Maximum DC voltage limit before linear generator derating Consider Max or Min torque. Default 52V";
CM_ SG_ 297 UDCMax_Unlim_MCPB_P "Maximum DC voltage limit before linear generator derating Consider Max or Min torque. Default 52V";
CM_ SG_ 297 UDCMax_Unlim_MCPA_P "Maximum DC voltage limit before linear generator derating Consider Max or Min torque. Default 52V";
CM_ SG_ 297 TqGrdtLim_SGCP_P "Positive or Negative Torque Gradient applied for Torque Control Mode and Speed Control Mode. Default 1000Nm/s";
CM_ SG_ 297 TqGrdtLim_MCPB_P "Positive or Negative Torque Gradient applied for Torque Control Mode and Speed Control Mode. Default 1000Nm/s";
CM_ SG_ 297 TqGrdtLim_MCPA_P "Positive or Negative Torque Gradient applied for Torque Control Mode and Speed Control Mode. Default 1000Nm/s";
CM_ SG_ 297 SpdGrdtLim_SGCP_P "Positive or negative (symetric) Speed Request Gradient applicable on both sign only for Speed Control Mode. Default 25,000 rpm/s";
CM_ SG_ 297 SpdGrdtLim_MCPB_P "Positive or negative (symetric) Speed Request Gradient applicable on both sign only for Speed Control Mode. Default 25,000 rpm/s";
CM_ SG_ 297 SpdGrdtLim_MCPA_P "Positive or negative (symetric) Speed Request Gradient applicable on both sign only for Speed Control Mode. Default 25,000 rpm/s";
CM_ SG_ 297 Pwr_Electr_Loop_FlwRate_SGCP_P "Inverter cooling liquid flow rate information";
CM_ SG_ 297 Pwr_Electr_Loop_FlwRate_MCPB_P "Inverter cooling liquid flow rate information";
CM_ SG_ 297 Pwr_Electr_Loop_FlwRate_MCPA_P "Inverter cooling liquid flow rate information";
CM_ SG_ 297 MC_INVTARGET_PROPULSION2 "Message counter according to SAE J1850 standard that has to be calculated from bit 63 to bit 8 at each frame transmission.";
CM_ SG_ 297 EVCU_MotorC_Speed "Motor C Speed Calculted by Supervisory Controller";
CM_ SG_ 297 EVCU_MotorB_Speed "Motor B Speed Calculted by Supervisory Controller";
CM_ SG_ 297 EVCU_MotorA_Speed "Motor A Speed Calculted by Supervisory Controller";
CM_ SG_ 297 CRC_INVTARGET_PROPULSION2 "CRC according to SAE J1850 standard that has to be calculated from bit 63 to bit 8 at each frame transmission.";
CM_ SG_ 296 VehicleSpeedVSOSig_P "It is the average vehicle speed calculated.";
CM_ SG_ 296 TorqueCommand_SGCP_P "Torque command for SGCP";
CM_ SG_ 296 TorqueCommand_MCPB_P "Torque command for MCPB";
CM_ SG_ 296 TorqueCommand_MCPA_P "Torque command for MCPA";
CM_ SG_ 296 TargetMotorRPM_SGCP_P "Target Motor RPM for SGCP";
CM_ SG_ 296 TargetMotorRPM_MCPB_P "Target Motor RPM for MCPB";
CM_ SG_ 296 TargetMotorRPM_MCPA_P "Target Motor RPM for MCPA";
CM_ SG_ 296 ShiftLeverPosition_P "Shift Lever Position";
CM_ SG_ 296 ParkCmd_PT_P "Park Command for MCP.";
CM_ SG_ 296 Mtr_6SO_Request_SGCP_P "Six Switch Open Request  for SGCP (1=RequestActive; 0=RequestNotActive)";
CM_ SG_ 296 Mtr_6SO_Request_MCPB_P "Six Switch Open Request  for MCPB (1=RequestActive; 0=RequestNotActive)";
CM_ SG_ 296 Mtr_6SO_Request_MCPA_P "Six Switch Open Request  for MCPA (1=RequestActive; 0=RequestNotActive)";
CM_ SG_ 296 ModeCommand_SGCP_P "Mode command for SGCP";
CM_ SG_ 296 ModeCommand_MCPB_P "Mode command for MCPB";
CM_ SG_ 296 ModeCommand_MCPA_P "Mode command for MCPA";
CM_ SG_ 296 CRC_INVTARGET_PROPULSION1 "CRC according to SAE J1850 standard that has to be calculated from bit 63 to bit 8 at each frame transmission.";
CM_ SG_ 296 CmdIgnSts_P "Used to give information about the key selector position";
CM_ SG_ 296 BPCM_HV_TractionBusVoltage_P "Battery link traction bus voltage.";
CM_ SG_ 296 BPCM_HV_Trac_Main_Contac_Sts_P "Traction main contactor physical relay status";
CM_ SG_ 296 AEMD_Sclr_Gn_SGCP_P "SGCP AEMD Scalar Gain";
CM_ SG_ 296 AEMD_Sclr_Gn_MCPB_P "MCPB AEMD Scalar Gain";
CM_ SG_ 296 AEMD_Sclr_Gn_MCPA_P "MCPA AEMD Scalar Gain";
CM_ SG_ 296 AEMD_MinOffset_SGCP_P "MCPC AEMD Min Offset";
CM_ SG_ 296 AEMD_MinOffset_MCPB_P "MCPB AEMD Min Offset";
CM_ SG_ 296 AEMD_MinOffset_MCPA_P "MCPA AEMD Min Offset";
CM_ SG_ 296 AEMD_MaxOffset_SGCP_P "SGCP AEMD Max Offset";
CM_ SG_ 296 AEMD_MaxOffset_MCPB_P "MCPB AEMD Max Offset";
CM_ SG_ 296 AEMD_MaxOffset_MCPA_P "MCPA AEMD Max Offset";
CM_ SG_ 296 AEMD_Cutoff_FreqLow_SGCP_P "AEMD cut-off Frequency Low for SGCP";
CM_ SG_ 296 AEMD_Cutoff_FreqLow_MCPB_P "AEMD cut-off Frequency Low for MCPB";
CM_ SG_ 296 AEMD_Cutoff_FreqLow_MCPA_P "AEMD cut-off Frequency Low for MCPA";
CM_ SG_ 296 AEMD_Cutoff_FreqHigh_SGCP_P "AEMD cut-off Frequency High for SGCP";
CM_ SG_ 296 AEMD_Cutoff_FreqHigh_MCPB_P "AEMD cut-off Frequency High for MCPB";
CM_ SG_ 296 AEMD_Cutoff_FreqHigh_MCPA_P "AEMD cut-off Frequency High for MCPA";
BA_DEF_ BO_  "CANFD_BRS" ENUM  "0","1";
BA_DEF_ BO_  "VFrameFormat" ENUM  "StandardCAN","ExtendedCAN","reserved","reserved","reserved","reserved","reserved","reserved","reserved","reserved","reserved","reserved","reserved","reserved","StandardCAN_FD","ExtendedCAN_FD";
BA_DEF_ BO_  "DiagConnection" HEX 0 65535;
BA_DEF_ BO_  "DiagState" ENUM  "No","Yes";
BA_DEF_ BO_  "NmAsrMessage" ENUM  "No","Yes";
BA_DEF_ BO_  "GenMsgDelayTime" INT 0 65535;
BA_DEF_ BO_  "GenMsgCycleTime" INT 0 65535;
BA_DEF_ BO_  "GenMsgCycleTimeFast" INT 0 65535;
BA_DEF_ BO_  "GenMsgStartDelayTime" INT 0 65535;
BA_DEF_ BO_  "GenMsgILSupport" ENUM  "No","Yes";
BA_DEF_ BO_  "GenMsgNrOfRepetition" INT 0 255;
BA_DEF_ BO_  "GenMsgSendType" ENUM  "Cyclic","NotUsed","NotUsed","NotUsed","NotUsed","NotUsed","NotUsed","NotUsed","NoMsgSendType";
BA_DEF_ BO_  "NmMessage" ENUM  "No","Yes";
BA_DEF_ BO_  "DiagResponse" ENUM  "No","Yes";
BA_DEF_ BO_  "Type" ENUM  "P","C","PE","COC","PE_Cntrl","E","E_Cntrl","OC","S","BAF","DC","EM","MM","ISO-TP","-";
BA_DEF_ BO_  "DiagRequest" ENUM  "No","Yes";
BA_DEF_ SG_  "GenSigTimeoutTime_TCM" INT 0 65535;
BA_DEF_ SG_  "GenSigTimeoutTime_SGCP" INT 0 65535;
BA_DEF_ SG_  "GenSigTimeoutTime_MCPB" INT 0 65535;
BA_DEF_ SG_  "GenSigTimeoutTime_MCPA" INT 0 65535;
BA_DEF_ SG_  "GenSigTimeoutTime_EVCU2" INT 0 65535;
BA_DEF_ SG_  "GenSigTimeoutTime_ECM" INT 0 65535;
BA_DEF_ SG_  "GenSigTimeoutTime_AGSM" INT 0 65535;
BA_DEF_ SG_  "GenSigSendType" ENUM  "NotUsed","OnWrite","OnWriteWithRepetition","OnChange","OnChangeWithRepetition","IfActive","IfActiveWithRepetition","NoSigSendType";
BA_DEF_ SG_  "GenSigInactiveValue" INT 0 2147483647;
BA_DEF_ SG_  "GenSigStartValue" INT 0 2147483647;
BA_DEF_ SG_  "SystemSignalLongSymbol" STRING ;
BA_DEF_DEF_  "CANFD_BRS" "0";
BA_DEF_DEF_  "VFrameFormat" "StandardCAN_FD";
BA_DEF_DEF_  "DiagConnection" 0;
BA_DEF_DEF_  "DiagState" "No";
BA_DEF_DEF_  "NmAsrMessage" "No";
BA_DEF_DEF_  "GenMsgDelayTime" 0;
BA_DEF_DEF_  "GenMsgCycleTime" 0;
BA_DEF_DEF_  "GenMsgCycleTimeFast" 0;
BA_DEF_DEF_  "GenMsgStartDelayTime" 0;
BA_DEF_DEF_  "GenMsgILSupport" "No";
BA_DEF_DEF_  "GenMsgNrOfRepetition" 0;
BA_DEF_DEF_  "GenMsgSendType" "NoMsgSendType";
BA_DEF_DEF_  "NmMessage" "No";
BA_DEF_DEF_  "DiagResponse" "No";
BA_DEF_DEF_  "Type" "-";
BA_DEF_DEF_  "DiagRequest" "No";
BA_DEF_DEF_  "GenSigTimeoutTime_TCM" 2500;
BA_DEF_DEF_  "GenSigTimeoutTime_SGCP" 2500;
BA_DEF_DEF_  "GenSigTimeoutTime_MCPB" 2500;
BA_DEF_DEF_  "GenSigTimeoutTime_MCPA" 2500;
BA_DEF_DEF_  "GenSigTimeoutTime_EVCU2" 2500;
BA_DEF_DEF_  "GenSigTimeoutTime_ECM" 2500;
BA_DEF_DEF_  "GenSigTimeoutTime_AGSM" 2500;
BA_DEF_DEF_  "GenSigSendType" "NoSigSendType";
BA_DEF_DEF_  "GenSigInactiveValue" 0;
BA_DEF_DEF_  "GenSigStartValue" 0;
BA_DEF_DEF_  "SystemSignalLongSymbol" "";
BA_ "Type" BO_ 1064 1;
BA_ "GenMsgSendType" BO_ 1064 0;
BA_ "GenMsgILSupport" BO_ 1064 1;
BA_ "GenMsgCycleTime" BO_ 1064 100;
BA_ "CANFD_BRS" BO_ 1064 1;
BA_ "Type" BO_ 263 1;
BA_ "GenMsgSendType" BO_ 263 0;
BA_ "GenMsgILSupport" BO_ 263 1;
BA_ "GenMsgCycleTime" BO_ 263 10;
BA_ "CANFD_BRS" BO_ 263 1;
BA_ "Type" BO_ 2654486729 8;
BA_ "NmMessage" BO_ 2654486729 1;
BA_ "NmAsrMessage" BO_ 2654486729 1;
BA_ "CANFD_BRS" BO_ 2654486729 1;
BA_ "VFrameFormat" BO_ 2654486729 15;
BA_ "Type" BO_ 237 1;
BA_ "GenMsgSendType" BO_ 237 0;
BA_ "GenMsgILSupport" BO_ 237 1;
BA_ "GenMsgCycleTime" BO_ 237 10;
BA_ "CANFD_BRS" BO_ 237 1;
BA_ "Type" BO_ 2651930825 11;
BA_ "GenMsgILSupport" BO_ 2651930825 1;
BA_ "CANFD_BRS" BO_ 2651930825 1;
BA_ "VFrameFormat" BO_ 2651930825 15;
BA_ "Type" BO_ 216 1;
BA_ "GenMsgSendType" BO_ 216 0;
BA_ "GenMsgILSupport" BO_ 216 1;
BA_ "GenMsgCycleTime" BO_ 216 10;
BA_ "CANFD_BRS" BO_ 216 1;
BA_ "Type" BO_ 2654486592 8;
BA_ "NmMessage" BO_ 2654486592 1;
BA_ "NmAsrMessage" BO_ 2654486592 1;
BA_ "CANFD_BRS" BO_ 2654486592 1;
BA_ "VFrameFormat" BO_ 2654486592 15;
BA_ "GenMsgILSupport" BO_ 1811 1;
BA_ "GenMsgCycleTime" BO_ 1811 1000;
BA_ "GenMsgDelayTime" BO_ 1811 20;
BA_ "CANFD_BRS" BO_ 1811 1;
BA_ "Type" BO_ 1811 1;
BA_ "GenMsgSendType" BO_ 1811 0;
BA_ "Type" BO_ 1070 1;
BA_ "GenMsgSendType" BO_ 1070 0;
BA_ "GenMsgILSupport" BO_ 1070 1;
BA_ "GenMsgCycleTime" BO_ 1070 100;
BA_ "CANFD_BRS" BO_ 1070 1;
BA_ "Type" BO_ 1065 1;
BA_ "GenMsgSendType" BO_ 1065 0;
BA_ "GenMsgILSupport" BO_ 1065 1;
BA_ "GenMsgCycleTime" BO_ 1065 100;
BA_ "CANFD_BRS" BO_ 1065 1;
BA_ "Type" BO_ 1057 1;
BA_ "GenMsgSendType" BO_ 1057 0;
BA_ "GenMsgILSupport" BO_ 1057 1;
BA_ "GenMsgCycleTime" BO_ 1057 100;
BA_ "CANFD_BRS" BO_ 1057 1;
BA_ "Type" BO_ 505 1;
BA_ "GenMsgSendType" BO_ 505 0;
BA_ "GenMsgILSupport" BO_ 505 1;
BA_ "GenMsgCycleTime" BO_ 505 20;
BA_ "CANFD_BRS" BO_ 505 1;
BA_ "Type" BO_ 295 1;
BA_ "GenMsgSendType" BO_ 295 0;
BA_ "GenMsgILSupport" BO_ 295 1;
BA_ "GenMsgCycleTime" BO_ 295 10;
BA_ "CANFD_BRS" BO_ 295 1;
BA_ "Type" BO_ 504 1;
BA_ "GenMsgSendType" BO_ 504 0;
BA_ "GenMsgILSupport" BO_ 504 1;
BA_ "GenMsgCycleTime" BO_ 504 20;
BA_ "CANFD_BRS" BO_ 504 1;
BA_ "Type" BO_ 294 1;
BA_ "GenMsgSendType" BO_ 294 0;
BA_ "GenMsgILSupport" BO_ 294 1;
BA_ "GenMsgCycleTime" BO_ 294 10;
BA_ "CANFD_BRS" BO_ 294 1;
BA_ "Type" BO_ 503 1;
BA_ "GenMsgSendType" BO_ 503 0;
BA_ "GenMsgILSupport" BO_ 503 1;
BA_ "GenMsgCycleTime" BO_ 503 20;
BA_ "CANFD_BRS" BO_ 503 1;
BA_ "Type" BO_ 293 1;
BA_ "GenMsgSendType" BO_ 293 0;
BA_ "GenMsgILSupport" BO_ 293 1;
BA_ "GenMsgCycleTime" BO_ 293 10;
BA_ "CANFD_BRS" BO_ 293 1;
BA_ "Type" BO_ 297 1;
BA_ "GenMsgSendType" BO_ 297 0;
BA_ "GenMsgILSupport" BO_ 297 1;
BA_ "GenMsgCycleTime" BO_ 297 10;
BA_ "CANFD_BRS" BO_ 297 1;
BA_ "Type" BO_ 296 1;
BA_ "GenMsgSendType" BO_ 296 0;
BA_ "GenMsgILSupport" BO_ 296 1;
BA_ "GenMsgCycleTime" BO_ 296 10;
BA_ "CANFD_BRS" BO_ 296 1;
BA_ "GenSigTimeoutTime_AGSM" SG_ 1064 SGCP_Temp 0;
BA_ "GenSigTimeoutTime_ECM" SG_ 1064 SGCP_Temp 0;
BA_ "GenSigTimeoutTime_MCPA" SG_ 1064 SGCP_Temp 0;
BA_ "GenSigTimeoutTime_MCPB" SG_ 1064 SGCP_Temp 0;
BA_ "GenSigTimeoutTime_SGCP" SG_ 1064 SGCP_Temp 0;
BA_ "GenSigTimeoutTime_TCM" SG_ 1064 SGCP_Temp 0;
BA_ "GenSigTimeoutTime_AGSM" SG_ 1064 SGCP_Rotor_Temperature 0;
BA_ "GenSigTimeoutTime_ECM" SG_ 1064 SGCP_Rotor_Temperature 0;
BA_ "GenSigTimeoutTime_MCPA" SG_ 1064 SGCP_Rotor_Temperature 0;
BA_ "GenSigTimeoutTime_MCPB" SG_ 1064 SGCP_Rotor_Temperature 0;
BA_ "GenSigTimeoutTime_SGCP" SG_ 1064 SGCP_Rotor_Temperature 0;
BA_ "GenSigTimeoutTime_TCM" SG_ 1064 SGCP_Rotor_Temperature 0;
BA_ "GenSigTimeoutTime_AGSM" SG_ 1064 SGCP_Inverter_Temp 0;
BA_ "GenSigTimeoutTime_ECM" SG_ 1064 SGCP_Inverter_Temp 0;
BA_ "GenSigTimeoutTime_MCPA" SG_ 1064 SGCP_Inverter_Temp 0;
BA_ "GenSigTimeoutTime_MCPB" SG_ 1064 SGCP_Inverter_Temp 0;
BA_ "GenSigTimeoutTime_SGCP" SG_ 1064 SGCP_Inverter_Temp 0;
BA_ "GenSigTimeoutTime_TCM" SG_ 1064 SGCP_Inverter_Temp 0;
BA_ "GenSigTimeoutTime_AGSM" SG_ 1064 SGCP_Control_Board_Temperature 0;
BA_ "GenSigTimeoutTime_ECM" SG_ 1064 SGCP_Control_Board_Temperature 0;
BA_ "GenSigTimeoutTime_MCPA" SG_ 1064 SGCP_Control_Board_Temperature 0;
BA_ "GenSigTimeoutTime_MCPB" SG_ 1064 SGCP_Control_Board_Temperature 0;
BA_ "GenSigTimeoutTime_SGCP" SG_ 1064 SGCP_Control_Board_Temperature 0;
BA_ "GenSigTimeoutTime_TCM" SG_ 1064 SGCP_Control_Board_Temperature 0;
BA_ "GenSigTimeoutTime_AGSM" SG_ 1064 MessageCounter_SGCP_DATA2 0;
BA_ "GenSigTimeoutTime_ECM" SG_ 1064 MessageCounter_SGCP_DATA2 0;
BA_ "GenSigTimeoutTime_MCPA" SG_ 1064 MessageCounter_SGCP_DATA2 0;
BA_ "GenSigTimeoutTime_MCPB" SG_ 1064 MessageCounter_SGCP_DATA2 0;
BA_ "GenSigTimeoutTime_SGCP" SG_ 1064 MessageCounter_SGCP_DATA2 0;
BA_ "GenSigTimeoutTime_TCM" SG_ 1064 MessageCounter_SGCP_DATA2 0;
BA_ "GenSigTimeoutTime_AGSM" SG_ 1064 CRC_SGCP_DATA2 0;
BA_ "GenSigTimeoutTime_ECM" SG_ 1064 CRC_SGCP_DATA2 0;
BA_ "GenSigTimeoutTime_MCPA" SG_ 1064 CRC_SGCP_DATA2 0;
BA_ "GenSigTimeoutTime_MCPB" SG_ 1064 CRC_SGCP_DATA2 0;
BA_ "GenSigTimeoutTime_SGCP" SG_ 1064 CRC_SGCP_DATA2 0;
BA_ "GenSigTimeoutTime_TCM" SG_ 1064 CRC_SGCP_DATA2 0;
BA_ "GenSigTimeoutTime_AGSM" SG_ 1064 CLrDiagInfo_SGCP 0;
BA_ "GenSigTimeoutTime_ECM" SG_ 1064 CLrDiagInfo_SGCP 0;
BA_ "GenSigTimeoutTime_MCPA" SG_ 1064 CLrDiagInfo_SGCP 0;
BA_ "GenSigTimeoutTime_MCPB" SG_ 1064 CLrDiagInfo_SGCP 0;
BA_ "GenSigTimeoutTime_SGCP" SG_ 1064 CLrDiagInfo_SGCP 0;
BA_ "GenSigTimeoutTime_TCM" SG_ 1064 CLrDiagInfo_SGCP 0;
BA_ "GenSigTimeoutTime_AGSM" SG_ 1064 SGCP_Service_Lamp_Request 0;
BA_ "GenSigTimeoutTime_ECM" SG_ 1064 SGCP_Service_Lamp_Request 0;
BA_ "GenSigTimeoutTime_MCPA" SG_ 1064 SGCP_Service_Lamp_Request 0;
BA_ "GenSigTimeoutTime_MCPB" SG_ 1064 SGCP_Service_Lamp_Request 0;
BA_ "GenSigTimeoutTime_SGCP" SG_ 1064 SGCP_Service_Lamp_Request 0;
BA_ "GenSigTimeoutTime_TCM" SG_ 1064 SGCP_Service_Lamp_Request 0;
BA_ "GenSigStartValue" SG_ 1064 Genrtr_PIM_DC_Side_Busbar_Temp 255;
BA_ "GenSigTimeoutTime_AGSM" SG_ 1064 Genrtr_PIM_DC_Side_Busbar_Temp 0;
BA_ "GenSigTimeoutTime_ECM" SG_ 1064 Genrtr_PIM_DC_Side_Busbar_Temp 0;
BA_ "GenSigTimeoutTime_MCPA" SG_ 1064 Genrtr_PIM_DC_Side_Busbar_Temp 0;
BA_ "GenSigTimeoutTime_MCPB" SG_ 1064 Genrtr_PIM_DC_Side_Busbar_Temp 0;
BA_ "GenSigTimeoutTime_SGCP" SG_ 1064 Genrtr_PIM_DC_Side_Busbar_Temp 0;
BA_ "GenSigTimeoutTime_TCM" SG_ 1064 Genrtr_PIM_DC_Side_Busbar_Temp 0;
BA_ "GenSigStartValue" SG_ 1064 Genrtr_PIM_AC_Side_Busbar_Temp 255;
BA_ "GenSigTimeoutTime_AGSM" SG_ 1064 Genrtr_PIM_AC_Side_Busbar_Temp 0;
BA_ "GenSigTimeoutTime_ECM" SG_ 1064 Genrtr_PIM_AC_Side_Busbar_Temp 0;
BA_ "GenSigTimeoutTime_MCPA" SG_ 1064 Genrtr_PIM_AC_Side_Busbar_Temp 0;
BA_ "GenSigTimeoutTime_MCPB" SG_ 1064 Genrtr_PIM_AC_Side_Busbar_Temp 0;
BA_ "GenSigTimeoutTime_SGCP" SG_ 1064 Genrtr_PIM_AC_Side_Busbar_Temp 0;
BA_ "GenSigTimeoutTime_TCM" SG_ 1064 Genrtr_PIM_AC_Side_Busbar_Temp 0;
BA_ "GenSigTimeoutTime_AGSM" SG_ 263 OptimdStrtReqdActr 0;
BA_ "GenSigTimeoutTime_EVCU2" SG_ 263 OptimdStrtReqdActr 0;
BA_ "GenSigTimeoutTime_MCPA" SG_ 263 OptimdStrtReqdActr 0;
BA_ "GenSigTimeoutTime_MCPB" SG_ 263 OptimdStrtReqdActr 0;
BA_ "GenSigTimeoutTime_SGCP" SG_ 263 OptimdStrtReqdActr 0;
BA_ "GenSigTimeoutTime_TCM" SG_ 263 OptimdStrtReqdActr 0;
BA_ "GenSigTimeoutTime_AGSM" SG_ 263 OptimdEngStrtStpType 0;
BA_ "GenSigTimeoutTime_EVCU2" SG_ 263 OptimdEngStrtStpType 0;
BA_ "GenSigTimeoutTime_MCPA" SG_ 263 OptimdEngStrtStpType 0;
BA_ "GenSigTimeoutTime_MCPB" SG_ 263 OptimdEngStrtStpType 0;
BA_ "GenSigTimeoutTime_SGCP" SG_ 263 OptimdEngStrtStpType 0;
BA_ "GenSigTimeoutTime_TCM" SG_ 263 OptimdEngStrtStpType 0;
BA_ "GenSigTimeoutTime_AGSM" SG_ 263 OptimdEngOnOffCmd 0;
BA_ "GenSigTimeoutTime_EVCU2" SG_ 263 OptimdEngOnOffCmd 0;
BA_ "GenSigTimeoutTime_MCPA" SG_ 263 OptimdEngOnOffCmd 0;
BA_ "GenSigTimeoutTime_MCPB" SG_ 263 OptimdEngOnOffCmd 0;
BA_ "GenSigTimeoutTime_SGCP" SG_ 263 OptimdEngOnOffCmd 0;
BA_ "GenSigTimeoutTime_TCM" SG_ 263 OptimdEngOnOffCmd 0;
BA_ "GenSigTimeoutTime_AGSM" SG_ 263 Hyb_ProducingTorque 0;
BA_ "GenSigTimeoutTime_EVCU2" SG_ 263 Hyb_ProducingTorque 0;
BA_ "GenSigTimeoutTime_MCPA" SG_ 263 Hyb_ProducingTorque 0;
BA_ "GenSigTimeoutTime_MCPB" SG_ 263 Hyb_ProducingTorque 0;
BA_ "GenSigTimeoutTime_SGCP" SG_ 263 Hyb_ProducingTorque 0;
BA_ "GenSigTimeoutTime_TCM" SG_ 263 Hyb_ProducingTorque 0;
BA_ "GenSigStartValue" SG_ 263 HCPFuelDisable 1;
BA_ "GenSigTimeoutTime_AGSM" SG_ 263 HCPFuelDisable 0;
BA_ "GenSigTimeoutTime_EVCU2" SG_ 263 HCPFuelDisable 0;
BA_ "GenSigTimeoutTime_MCPA" SG_ 263 HCPFuelDisable 0;
BA_ "GenSigTimeoutTime_MCPB" SG_ 263 HCPFuelDisable 0;
BA_ "GenSigTimeoutTime_SGCP" SG_ 263 HCPFuelDisable 0;
BA_ "GenSigTimeoutTime_TCM" SG_ 263 HCPFuelDisable 0;
BA_ "GenSigTimeoutTime_AGSM" SG_ 263 PowertrainPrplsnActv_PT 0;
BA_ "GenSigTimeoutTime_ECM" SG_ 263 PowertrainPrplsnActv_PT 0;
BA_ "GenSigTimeoutTime_EVCU2" SG_ 263 PowertrainPrplsnActv_PT 0;
BA_ "GenSigTimeoutTime_MCPA" SG_ 263 PowertrainPrplsnActv_PT 0;
BA_ "GenSigTimeoutTime_MCPB" SG_ 263 PowertrainPrplsnActv_PT 0;
BA_ "GenSigTimeoutTime_SGCP" SG_ 263 PowertrainPrplsnActv_PT 0;
BA_ "GenSigTimeoutTime_TCM" SG_ 263 PowertrainPrplsnActv_PT 0;
BA_ "GenSigTimeoutTime_ECM" SG_ 263 GearEngagedForDisplay_PT 0;
BA_ "GenSigTimeoutTime_EVCU2" SG_ 263 GearEngagedForDisplay_PT 0;
BA_ "GenSigTimeoutTime_MCPA" SG_ 263 GearEngagedForDisplay_PT 0;
BA_ "GenSigTimeoutTime_MCPB" SG_ 263 GearEngagedForDisplay_PT 0;
BA_ "GenSigTimeoutTime_SGCP" SG_ 263 GearEngagedForDisplay_PT 0;
BA_ "GenSigTimeoutTime_TCM" SG_ 263 GearEngagedForDisplay_PT 0;
BA_ "GenSigTimeoutTime_AGSM" SG_ 263 GearEngaged_PT 0;
BA_ "GenSigTimeoutTime_ECM" SG_ 263 GearEngaged_PT 0;
BA_ "GenSigTimeoutTime_EVCU2" SG_ 263 GearEngaged_PT 0;
BA_ "GenSigTimeoutTime_MCPA" SG_ 263 GearEngaged_PT 0;
BA_ "GenSigTimeoutTime_SGCP" SG_ 263 GearEngaged_PT 0;
BA_ "GenSigTimeoutTime_TCM" SG_ 263 GearEngaged_PT 0;
BA_ "GenSigTimeoutTime_AGSM" SG_ 263 ParkCmd_PT 0;
BA_ "GenSigTimeoutTime_ECM" SG_ 263 ParkCmd_PT 0;
BA_ "GenSigTimeoutTime_EVCU2" SG_ 263 ParkCmd_PT 0;
BA_ "GenSigTimeoutTime_MCPA" SG_ 263 ParkCmd_PT 0;
BA_ "GenSigTimeoutTime_SGCP" SG_ 263 ParkCmd_PT 0;
BA_ "GenSigTimeoutTime_TCM" SG_ 263 ParkCmd_PT 0;
BA_ "GenSigTimeoutTime_ECM" SG_ 263 TransmissionFailSts_PT 0;
BA_ "GenSigTimeoutTime_EVCU2" SG_ 263 TransmissionFailSts_PT 0;
BA_ "GenSigTimeoutTime_MCPA" SG_ 263 TransmissionFailSts_PT 0;
BA_ "GenSigTimeoutTime_MCPB" SG_ 263 TransmissionFailSts_PT 0;
BA_ "GenSigTimeoutTime_SGCP" SG_ 263 TransmissionFailSts_PT 0;
BA_ "GenSigTimeoutTime_TCM" SG_ 263 TransmissionFailSts_PT 0;
BA_ "GenSigTimeoutTime_AGSM" SG_ 263 TerrainModeStat_PT 0;
BA_ "GenSigTimeoutTime_ECM" SG_ 263 TerrainModeStat_PT 0;
BA_ "GenSigTimeoutTime_EVCU2" SG_ 263 TerrainModeStat_PT 0;
BA_ "GenSigTimeoutTime_MCPA" SG_ 263 TerrainModeStat_PT 0;
BA_ "GenSigTimeoutTime_MCPB" SG_ 263 TerrainModeStat_PT 0;
BA_ "GenSigTimeoutTime_TCM" SG_ 263 TerrainModeStat_PT 0;
BA_ "GenSigTimeoutTime_ECM" SG_ 263 ShiftLeverPosition_PT 0;
BA_ "GenSigTimeoutTime_EVCU2" SG_ 263 ShiftLeverPosition_PT 0;
BA_ "GenSigTimeoutTime_MCPA" SG_ 263 ShiftLeverPosition_PT 0;
BA_ "GenSigTimeoutTime_MCPB" SG_ 263 ShiftLeverPosition_PT 0;
BA_ "GenSigTimeoutTime_SGCP" SG_ 263 ShiftLeverPosition_PT 0;
BA_ "GenSigTimeoutTime_TCM" SG_ 263 ShiftLeverPosition_PT 0;
BA_ "GenSigTimeoutTime_ECM" SG_ 263 ShiftLeverLockReq_PT 0;
BA_ "GenSigTimeoutTime_EVCU2" SG_ 263 ShiftLeverLockReq_PT 0;
BA_ "GenSigTimeoutTime_MCPA" SG_ 263 ShiftLeverLockReq_PT 0;
BA_ "GenSigTimeoutTime_MCPB" SG_ 263 ShiftLeverLockReq_PT 0;
BA_ "GenSigTimeoutTime_TCM" SG_ 263 ShiftLeverLockReq_PT 0;
BA_ "GenSigTimeoutTime_AGSM" SG_ 263 MessageCounter_PT_SYSTEM_FD_1 0;
BA_ "GenSigTimeoutTime_EVCU2" SG_ 263 MessageCounter_PT_SYSTEM_FD_1 0;
BA_ "GenSigTimeoutTime_MCPA" SG_ 263 MessageCounter_PT_SYSTEM_FD_1 0;
BA_ "GenSigTimeoutTime_MCPB" SG_ 263 MessageCounter_PT_SYSTEM_FD_1 0;
BA_ "GenSigTimeoutTime_SGCP" SG_ 263 MessageCounter_PT_SYSTEM_FD_1 0;
BA_ "GenSigTimeoutTime_TCM" SG_ 263 MessageCounter_PT_SYSTEM_FD_1 0;
BA_ "GenSigTimeoutTime_ECM" SG_ 263 GearIndicationSts_PT 0;
BA_ "GenSigTimeoutTime_EVCU2" SG_ 263 GearIndicationSts_PT 0;
BA_ "GenSigTimeoutTime_MCPA" SG_ 263 GearIndicationSts_PT 0;
BA_ "GenSigTimeoutTime_MCPB" SG_ 263 GearIndicationSts_PT 0;
BA_ "GenSigTimeoutTime_SGCP" SG_ 263 GearIndicationSts_PT 0;
BA_ "GenSigTimeoutTime_TCM" SG_ 263 GearIndicationSts_PT 0;
BA_ "GenSigTimeoutTime_AGSM" SG_ 263 GasPedalPositionFailSts_PT 0;
BA_ "GenSigTimeoutTime_EVCU2" SG_ 263 GasPedalPositionFailSts_PT 0;
BA_ "GenSigTimeoutTime_MCPA" SG_ 263 GasPedalPositionFailSts_PT 0;
BA_ "GenSigTimeoutTime_MCPB" SG_ 263 GasPedalPositionFailSts_PT 0;
BA_ "GenSigTimeoutTime_SGCP" SG_ 263 GasPedalPositionFailSts_PT 0;
BA_ "GenSigTimeoutTime_TCM" SG_ 263 GasPedalPositionFailSts_PT 0;
BA_ "GenSigTimeoutTime_AGSM" SG_ 263 GasPedalPosition_PT 0;
BA_ "GenSigTimeoutTime_EVCU2" SG_ 263 GasPedalPosition_PT 0;
BA_ "GenSigTimeoutTime_MCPA" SG_ 263 GasPedalPosition_PT 0;
BA_ "GenSigTimeoutTime_MCPB" SG_ 263 GasPedalPosition_PT 0;
BA_ "GenSigTimeoutTime_SGCP" SG_ 263 GasPedalPosition_PT 0;
BA_ "GenSigTimeoutTime_TCM" SG_ 263 GasPedalPosition_PT 0;
BA_ "GenSigTimeoutTime_AGSM" SG_ 263 CRC_PT_SYSTEM_FD_1 0;
BA_ "GenSigTimeoutTime_EVCU2" SG_ 263 CRC_PT_SYSTEM_FD_1 0;
BA_ "GenSigTimeoutTime_MCPA" SG_ 263 CRC_PT_SYSTEM_FD_1 0;
BA_ "GenSigTimeoutTime_MCPB" SG_ 263 CRC_PT_SYSTEM_FD_1 0;
BA_ "GenSigTimeoutTime_SGCP" SG_ 263 CRC_PT_SYSTEM_FD_1 0;
BA_ "GenSigTimeoutTime_TCM" SG_ 263 CRC_PT_SYSTEM_FD_1 0;
BA_ "GenSigTimeoutTime_ECM" SG_ 263 APCM_Rq_PT 0;
BA_ "GenSigTimeoutTime_EVCU2" SG_ 263 APCM_Rq_PT 0;
BA_ "GenSigTimeoutTime_MCPA" SG_ 263 APCM_Rq_PT 0;
BA_ "GenSigTimeoutTime_MCPB" SG_ 263 APCM_Rq_PT 0;
BA_ "GenSigTimeoutTime_SGCP" SG_ 263 APCM_Rq_PT 0;
BA_ "GenSigTimeoutTime_TCM" SG_ 263 APCM_Rq_PT 0;
BA_ "GenSigTimeoutTime_AGSM" SG_ 2654486729 CBV_bit0_RepeatMessageReque_0001 0;
BA_ "GenSigTimeoutTime_ECM" SG_ 2654486729 CBV_bit0_RepeatMessageReque_0001 0;
BA_ "GenSigTimeoutTime_EVCU2" SG_ 2654486729 CBV_bit0_RepeatMessageReque_0001 0;
BA_ "GenSigTimeoutTime_MCPA" SG_ 2654486729 CBV_bit0_RepeatMessageReque_0001 0;
BA_ "GenSigTimeoutTime_MCPB" SG_ 2654486729 CBV_bit0_RepeatMessageReque_0001 0;
BA_ "GenSigTimeoutTime_SGCP" SG_ 2654486729 CBV_bit0_RepeatMessageReque_0001 0;
BA_ "GenSigTimeoutTime_TCM" SG_ 2654486729 CBV_bit0_RepeatMessageReque_0001 0;
BA_ "SystemSignalLongSymbol" SG_ 2654486729 CBV_bit0_RepeatMessageReque_0001 "CBV_bit0_RepeatMessageRequestBit_1E3840C9";
BA_ "GenSigTimeoutTime_AGSM" SG_ 2654486729 CBV_bit1_1E3840C9 0;
BA_ "GenSigTimeoutTime_ECM" SG_ 2654486729 CBV_bit1_1E3840C9 0;
BA_ "GenSigTimeoutTime_EVCU2" SG_ 2654486729 CBV_bit1_1E3840C9 0;
BA_ "GenSigTimeoutTime_MCPA" SG_ 2654486729 CBV_bit1_1E3840C9 0;
BA_ "GenSigTimeoutTime_MCPB" SG_ 2654486729 CBV_bit1_1E3840C9 0;
BA_ "GenSigTimeoutTime_SGCP" SG_ 2654486729 CBV_bit1_1E3840C9 0;
BA_ "GenSigTimeoutTime_TCM" SG_ 2654486729 CBV_bit1_1E3840C9 0;
BA_ "GenSigTimeoutTime_AGSM" SG_ 2654486729 CBV_bit2_1E3840C9 0;
BA_ "GenSigTimeoutTime_ECM" SG_ 2654486729 CBV_bit2_1E3840C9 0;
BA_ "GenSigTimeoutTime_EVCU2" SG_ 2654486729 CBV_bit2_1E3840C9 0;
BA_ "GenSigTimeoutTime_MCPA" SG_ 2654486729 CBV_bit2_1E3840C9 0;
BA_ "GenSigTimeoutTime_MCPB" SG_ 2654486729 CBV_bit2_1E3840C9 0;
BA_ "GenSigTimeoutTime_SGCP" SG_ 2654486729 CBV_bit2_1E3840C9 0;
BA_ "GenSigTimeoutTime_TCM" SG_ 2654486729 CBV_bit2_1E3840C9 0;
BA_ "GenSigTimeoutTime_AGSM" SG_ 2654486729 CBV_bit3_NMCoordinatorBit_1_0001 0;
BA_ "GenSigTimeoutTime_ECM" SG_ 2654486729 CBV_bit3_NMCoordinatorBit_1_0001 0;
BA_ "GenSigTimeoutTime_EVCU2" SG_ 2654486729 CBV_bit3_NMCoordinatorBit_1_0001 0;
BA_ "GenSigTimeoutTime_MCPA" SG_ 2654486729 CBV_bit3_NMCoordinatorBit_1_0001 0;
BA_ "GenSigTimeoutTime_MCPB" SG_ 2654486729 CBV_bit3_NMCoordinatorBit_1_0001 0;
BA_ "GenSigTimeoutTime_SGCP" SG_ 2654486729 CBV_bit3_NMCoordinatorBit_1_0001 0;
BA_ "GenSigTimeoutTime_TCM" SG_ 2654486729 CBV_bit3_NMCoordinatorBit_1_0001 0;
BA_ "SystemSignalLongSymbol" SG_ 2654486729 CBV_bit3_NMCoordinatorBit_1_0001 "CBV_bit3_NMCoordinatorBit_1E3840C9";
BA_ "GenSigTimeoutTime_AGSM" SG_ 2654486729 CBV_bit4_ActiveWakeupBit_1E3840C 0;
BA_ "GenSigTimeoutTime_ECM" SG_ 2654486729 CBV_bit4_ActiveWakeupBit_1E3840C 0;
BA_ "GenSigTimeoutTime_EVCU2" SG_ 2654486729 CBV_bit4_ActiveWakeupBit_1E3840C 0;
BA_ "GenSigTimeoutTime_MCPA" SG_ 2654486729 CBV_bit4_ActiveWakeupBit_1E3840C 0;
BA_ "GenSigTimeoutTime_MCPB" SG_ 2654486729 CBV_bit4_ActiveWakeupBit_1E3840C 0;
BA_ "GenSigTimeoutTime_SGCP" SG_ 2654486729 CBV_bit4_ActiveWakeupBit_1E3840C 0;
BA_ "GenSigTimeoutTime_TCM" SG_ 2654486729 CBV_bit4_ActiveWakeupBit_1E3840C 0;
BA_ "SystemSignalLongSymbol" SG_ 2654486729 CBV_bit4_ActiveWakeupBit_1E3840C "CBV_bit4_ActiveWakeupBit_1E3840C9";
BA_ "GenSigTimeoutTime_AGSM" SG_ 2654486729 CBV_bit5_1E3840C9 0;
BA_ "GenSigTimeoutTime_ECM" SG_ 2654486729 CBV_bit5_1E3840C9 0;
BA_ "GenSigTimeoutTime_EVCU2" SG_ 2654486729 CBV_bit5_1E3840C9 0;
BA_ "GenSigTimeoutTime_MCPA" SG_ 2654486729 CBV_bit5_1E3840C9 0;
BA_ "GenSigTimeoutTime_MCPB" SG_ 2654486729 CBV_bit5_1E3840C9 0;
BA_ "GenSigTimeoutTime_SGCP" SG_ 2654486729 CBV_bit5_1E3840C9 0;
BA_ "GenSigTimeoutTime_TCM" SG_ 2654486729 CBV_bit5_1E3840C9 0;
BA_ "GenSigTimeoutTime_MCPB" SG_ 2654486729 CBV_bit6_PartialNtwInfBit_1_0001 0;
BA_ "GenSigTimeoutTime_SGCP" SG_ 2654486729 CBV_bit6_PartialNtwInfBit_1_0001 0;
BA_ "GenSigTimeoutTime_TCM" SG_ 2654486729 CBV_bit6_PartialNtwInfBit_1_0001 0;
BA_ "GenSigTimeoutTime_AGSM" SG_ 2654486729 CBV_bit6_PartialNtwInfBit_1_0001 0;
BA_ "GenSigTimeoutTime_ECM" SG_ 2654486729 CBV_bit6_PartialNtwInfBit_1_0001 0;
BA_ "GenSigTimeoutTime_EVCU2" SG_ 2654486729 CBV_bit6_PartialNtwInfBit_1_0001 0;
BA_ "GenSigTimeoutTime_MCPA" SG_ 2654486729 CBV_bit6_PartialNtwInfBit_1_0001 0;
BA_ "SystemSignalLongSymbol" SG_ 2654486729 CBV_bit6_PartialNtwInfBit_1_0001 "CBV_bit6_PartialNtwInfBit_1E3840C9";
BA_ "GenSigTimeoutTime_AGSM" SG_ 2654486729 CBV_bit7_1E3840C9 0;
BA_ "GenSigTimeoutTime_ECM" SG_ 2654486729 CBV_bit7_1E3840C9 0;
BA_ "GenSigTimeoutTime_EVCU2" SG_ 2654486729 CBV_bit7_1E3840C9 0;
BA_ "GenSigTimeoutTime_MCPA" SG_ 2654486729 CBV_bit7_1E3840C9 0;
BA_ "GenSigTimeoutTime_MCPB" SG_ 2654486729 CBV_bit7_1E3840C9 0;
BA_ "GenSigTimeoutTime_SGCP" SG_ 2654486729 CBV_bit7_1E3840C9 0;
BA_ "GenSigTimeoutTime_TCM" SG_ 2654486729 CBV_bit7_1E3840C9 0;
BA_ "GenSigTimeoutTime_AGSM" SG_ 2654486729 SourceNodeIdentifier_1E3840C9 0;
BA_ "GenSigTimeoutTime_ECM" SG_ 2654486729 SourceNodeIdentifier_1E3840C9 0;
BA_ "GenSigTimeoutTime_EVCU2" SG_ 2654486729 SourceNodeIdentifier_1E3840C9 0;
BA_ "GenSigTimeoutTime_MCPA" SG_ 2654486729 SourceNodeIdentifier_1E3840C9 0;
BA_ "GenSigTimeoutTime_MCPB" SG_ 2654486729 SourceNodeIdentifier_1E3840C9 0;
BA_ "GenSigTimeoutTime_SGCP" SG_ 2654486729 SourceNodeIdentifier_1E3840C9 0;
BA_ "GenSigTimeoutTime_TCM" SG_ 2654486729 SourceNodeIdentifier_1E3840C9 0;
BA_ "GenSigTimeoutTime_AGSM" SG_ 237 UDCMin_Unlim_SGCP 0;
BA_ "GenSigTimeoutTime_ECM" SG_ 237 UDCMin_Unlim_SGCP 0;
BA_ "GenSigTimeoutTime_EVCU2" SG_ 237 UDCMin_Unlim_SGCP 0;
BA_ "GenSigTimeoutTime_MCPA" SG_ 237 UDCMin_Unlim_SGCP 0;
BA_ "GenSigTimeoutTime_MCPB" SG_ 237 UDCMin_Unlim_SGCP 0;
BA_ "GenSigTimeoutTime_TCM" SG_ 237 UDCMin_Unlim_SGCP 0;
BA_ "GenSigStartValue" SG_ 237 UDCMin_Unlim_SGCP 32767;
BA_ "GenSigStartValue" SG_ 237 UDCMax_Unlim_SGCP 32767;
BA_ "GenSigTimeoutTime_AGSM" SG_ 237 UDCMax_Unlim_SGCP 0;
BA_ "GenSigTimeoutTime_ECM" SG_ 237 UDCMax_Unlim_SGCP 0;
BA_ "GenSigTimeoutTime_EVCU2" SG_ 237 UDCMax_Unlim_SGCP 0;
BA_ "GenSigTimeoutTime_MCPA" SG_ 237 UDCMax_Unlim_SGCP 0;
BA_ "GenSigTimeoutTime_MCPB" SG_ 237 UDCMax_Unlim_SGCP 0;
BA_ "GenSigTimeoutTime_TCM" SG_ 237 UDCMax_Unlim_SGCP 0;
BA_ "GenSigStartValue" SG_ 237 TqGrdtLim_SGCP 32767;
BA_ "GenSigTimeoutTime_AGSM" SG_ 237 TqGrdtLim_SGCP 0;
BA_ "GenSigTimeoutTime_ECM" SG_ 237 TqGrdtLim_SGCP 0;
BA_ "GenSigTimeoutTime_EVCU2" SG_ 237 TqGrdtLim_SGCP 0;
BA_ "GenSigTimeoutTime_MCPA" SG_ 237 TqGrdtLim_SGCP 0;
BA_ "GenSigTimeoutTime_MCPB" SG_ 237 TqGrdtLim_SGCP 0;
BA_ "GenSigTimeoutTime_TCM" SG_ 237 TqGrdtLim_SGCP 0;
BA_ "GenSigStartValue" SG_ 237 TorqueCommand_SGCP 4095;
BA_ "GenSigTimeoutTime_AGSM" SG_ 237 TorqueCommand_SGCP 0;
BA_ "GenSigTimeoutTime_ECM" SG_ 237 TorqueCommand_SGCP 0;
BA_ "GenSigTimeoutTime_EVCU2" SG_ 237 TorqueCommand_SGCP 0;
BA_ "GenSigTimeoutTime_MCPA" SG_ 237 TorqueCommand_SGCP 0;
BA_ "GenSigTimeoutTime_MCPB" SG_ 237 TorqueCommand_SGCP 0;
BA_ "GenSigTimeoutTime_TCM" SG_ 237 TorqueCommand_SGCP 0;
BA_ "GenSigStartValue" SG_ 237 TargetMotorRPM_SGCP 32768;
BA_ "GenSigTimeoutTime_AGSM" SG_ 237 TargetMotorRPM_SGCP 0;
BA_ "GenSigTimeoutTime_ECM" SG_ 237 TargetMotorRPM_SGCP 0;
BA_ "GenSigTimeoutTime_EVCU2" SG_ 237 TargetMotorRPM_SGCP 0;
BA_ "GenSigTimeoutTime_MCPA" SG_ 237 TargetMotorRPM_SGCP 0;
BA_ "GenSigTimeoutTime_MCPB" SG_ 237 TargetMotorRPM_SGCP 0;
BA_ "GenSigTimeoutTime_TCM" SG_ 237 TargetMotorRPM_SGCP 0;
BA_ "GenSigStartValue" SG_ 237 SpdGrdtLim_SGCP 1023;
BA_ "GenSigTimeoutTime_AGSM" SG_ 237 SpdGrdtLim_SGCP 0;
BA_ "GenSigTimeoutTime_ECM" SG_ 237 SpdGrdtLim_SGCP 0;
BA_ "GenSigTimeoutTime_EVCU2" SG_ 237 SpdGrdtLim_SGCP 0;
BA_ "GenSigTimeoutTime_MCPA" SG_ 237 SpdGrdtLim_SGCP 0;
BA_ "GenSigTimeoutTime_MCPB" SG_ 237 SpdGrdtLim_SGCP 0;
BA_ "GenSigTimeoutTime_TCM" SG_ 237 SpdGrdtLim_SGCP 0;
BA_ "GenSigTimeoutTime_AGSM" SG_ 237 Mtr_6SO_Request_SGCP 0;
BA_ "GenSigTimeoutTime_ECM" SG_ 237 Mtr_6SO_Request_SGCP 0;
BA_ "GenSigTimeoutTime_EVCU2" SG_ 237 Mtr_6SO_Request_SGCP 0;
BA_ "GenSigTimeoutTime_MCPA" SG_ 237 Mtr_6SO_Request_SGCP 0;
BA_ "GenSigTimeoutTime_MCPB" SG_ 237 Mtr_6SO_Request_SGCP 0;
BA_ "GenSigTimeoutTime_TCM" SG_ 237 Mtr_6SO_Request_SGCP 0;
BA_ "GenSigTimeoutTime_AGSM" SG_ 237 ModeCommand_SGCP 0;
BA_ "GenSigTimeoutTime_ECM" SG_ 237 ModeCommand_SGCP 0;
BA_ "GenSigTimeoutTime_EVCU2" SG_ 237 ModeCommand_SGCP 0;
BA_ "GenSigTimeoutTime_MCPA" SG_ 237 ModeCommand_SGCP 0;
BA_ "GenSigTimeoutTime_MCPB" SG_ 237 ModeCommand_SGCP 0;
BA_ "GenSigTimeoutTime_TCM" SG_ 237 ModeCommand_SGCP 0;
BA_ "GenSigTimeoutTime_AGSM" SG_ 237 MessageCounter_INVTARGET2 0;
BA_ "GenSigTimeoutTime_ECM" SG_ 237 MessageCounter_INVTARGET2 0;
BA_ "GenSigTimeoutTime_EVCU2" SG_ 237 MessageCounter_INVTARGET2 0;
BA_ "GenSigTimeoutTime_MCPA" SG_ 237 MessageCounter_INVTARGET2 0;
BA_ "GenSigTimeoutTime_MCPB" SG_ 237 MessageCounter_INVTARGET2 0;
BA_ "GenSigTimeoutTime_TCM" SG_ 237 MessageCounter_INVTARGET2 0;
BA_ "GenSigTimeoutTime_AGSM" SG_ 237 CRC_INVTARGET2 0;
BA_ "GenSigTimeoutTime_ECM" SG_ 237 CRC_INVTARGET2 0;
BA_ "GenSigTimeoutTime_EVCU2" SG_ 237 CRC_INVTARGET2 0;
BA_ "GenSigTimeoutTime_MCPA" SG_ 237 CRC_INVTARGET2 0;
BA_ "GenSigTimeoutTime_MCPB" SG_ 237 CRC_INVTARGET2 0;
BA_ "GenSigTimeoutTime_TCM" SG_ 237 CRC_INVTARGET2 0;
BA_ "GenSigTimeoutTime_AGSM" SG_ 237 AEMD_Sclr_Gn_SGCP 0;
BA_ "GenSigTimeoutTime_ECM" SG_ 237 AEMD_Sclr_Gn_SGCP 0;
BA_ "GenSigTimeoutTime_EVCU2" SG_ 237 AEMD_Sclr_Gn_SGCP 0;
BA_ "GenSigTimeoutTime_MCPA" SG_ 237 AEMD_Sclr_Gn_SGCP 0;
BA_ "GenSigTimeoutTime_MCPB" SG_ 237 AEMD_Sclr_Gn_SGCP 0;
BA_ "GenSigTimeoutTime_TCM" SG_ 237 AEMD_Sclr_Gn_SGCP 0;
BA_ "GenSigStartValue" SG_ 237 AEMD_MinOffset_SGCP 4095;
BA_ "GenSigTimeoutTime_AGSM" SG_ 237 AEMD_MinOffset_SGCP 0;
BA_ "GenSigTimeoutTime_ECM" SG_ 237 AEMD_MinOffset_SGCP 0;
BA_ "GenSigTimeoutTime_EVCU2" SG_ 237 AEMD_MinOffset_SGCP 0;
BA_ "GenSigTimeoutTime_MCPA" SG_ 237 AEMD_MinOffset_SGCP 0;
BA_ "GenSigTimeoutTime_MCPB" SG_ 237 AEMD_MinOffset_SGCP 0;
BA_ "GenSigTimeoutTime_TCM" SG_ 237 AEMD_MinOffset_SGCP 0;
BA_ "GenSigTimeoutTime_AGSM" SG_ 237 AEMD_MaxOffset_SGCP 0;
BA_ "GenSigTimeoutTime_ECM" SG_ 237 AEMD_MaxOffset_SGCP 0;
BA_ "GenSigTimeoutTime_EVCU2" SG_ 237 AEMD_MaxOffset_SGCP 0;
BA_ "GenSigTimeoutTime_MCPA" SG_ 237 AEMD_MaxOffset_SGCP 0;
BA_ "GenSigTimeoutTime_MCPB" SG_ 237 AEMD_MaxOffset_SGCP 0;
BA_ "GenSigTimeoutTime_TCM" SG_ 237 AEMD_MaxOffset_SGCP 0;
BA_ "GenSigTimeoutTime_AGSM" SG_ 237 Pwr_Electronic_Loop_FlwRate_SGCP 0;
BA_ "GenSigTimeoutTime_ECM" SG_ 237 Pwr_Electronic_Loop_FlwRate_SGCP 0;
BA_ "GenSigTimeoutTime_EVCU2" SG_ 237 Pwr_Electronic_Loop_FlwRate_SGCP 0;
BA_ "GenSigTimeoutTime_MCPA" SG_ 237 Pwr_Electronic_Loop_FlwRate_SGCP 0;
BA_ "GenSigTimeoutTime_MCPB" SG_ 237 Pwr_Electronic_Loop_FlwRate_SGCP 0;
BA_ "GenSigTimeoutTime_TCM" SG_ 237 Pwr_Electronic_Loop_FlwRate_SGCP 0;
BA_ "GenSigTimeoutTime_AGSM" SG_ 237 AEMD_Cutoff_FreqLow_SGCP 0;
BA_ "GenSigTimeoutTime_ECM" SG_ 237 AEMD_Cutoff_FreqLow_SGCP 0;
BA_ "GenSigTimeoutTime_EVCU2" SG_ 237 AEMD_Cutoff_FreqLow_SGCP 0;
BA_ "GenSigTimeoutTime_MCPA" SG_ 237 AEMD_Cutoff_FreqLow_SGCP 0;
BA_ "GenSigTimeoutTime_MCPB" SG_ 237 AEMD_Cutoff_FreqLow_SGCP 0;
BA_ "GenSigTimeoutTime_TCM" SG_ 237 AEMD_Cutoff_FreqLow_SGCP 0;
BA_ "GenSigTimeoutTime_AGSM" SG_ 237 AEMD_Cutoff_FreqHigh_SGCP 0;
BA_ "GenSigTimeoutTime_ECM" SG_ 237 AEMD_Cutoff_FreqHigh_SGCP 0;
BA_ "GenSigTimeoutTime_EVCU2" SG_ 237 AEMD_Cutoff_FreqHigh_SGCP 0;
BA_ "GenSigTimeoutTime_MCPA" SG_ 237 AEMD_Cutoff_FreqHigh_SGCP 0;
BA_ "GenSigTimeoutTime_MCPB" SG_ 237 AEMD_Cutoff_FreqHigh_SGCP 0;
BA_ "GenSigTimeoutTime_TCM" SG_ 237 AEMD_Cutoff_FreqHigh_SGCP 0;
BA_ "GenSigTimeoutTime_AGSM" SG_ 2651930825 Digit_11_SGCP 0;
BA_ "GenSigTimeoutTime_ECM" SG_ 2651930825 Digit_11_SGCP 0;
BA_ "GenSigTimeoutTime_MCPA" SG_ 2651930825 Digit_11_SGCP 0;
BA_ "GenSigTimeoutTime_MCPB" SG_ 2651930825 Digit_11_SGCP 0;
BA_ "GenSigTimeoutTime_SGCP" SG_ 2651930825 Digit_11_SGCP 0;
BA_ "GenSigTimeoutTime_TCM" SG_ 2651930825 Digit_11_SGCP 0;
BA_ "GenSigTimeoutTime_AGSM" SG_ 2651930825 Digit_10_SGCP 0;
BA_ "GenSigTimeoutTime_ECM" SG_ 2651930825 Digit_10_SGCP 0;
BA_ "GenSigTimeoutTime_MCPA" SG_ 2651930825 Digit_10_SGCP 0;
BA_ "GenSigTimeoutTime_MCPB" SG_ 2651930825 Digit_10_SGCP 0;
BA_ "GenSigTimeoutTime_SGCP" SG_ 2651930825 Digit_10_SGCP 0;
BA_ "GenSigTimeoutTime_TCM" SG_ 2651930825 Digit_10_SGCP 0;
BA_ "GenSigTimeoutTime_AGSM" SG_ 2651930825 Digit_09_SGCP 0;
BA_ "GenSigTimeoutTime_ECM" SG_ 2651930825 Digit_09_SGCP 0;
BA_ "GenSigTimeoutTime_MCPA" SG_ 2651930825 Digit_09_SGCP 0;
BA_ "GenSigTimeoutTime_MCPB" SG_ 2651930825 Digit_09_SGCP 0;
BA_ "GenSigTimeoutTime_SGCP" SG_ 2651930825 Digit_09_SGCP 0;
BA_ "GenSigTimeoutTime_TCM" SG_ 2651930825 Digit_09_SGCP 0;
BA_ "GenSigTimeoutTime_AGSM" SG_ 2651930825 Digit_08_SGCP 0;
BA_ "GenSigTimeoutTime_ECM" SG_ 2651930825 Digit_08_SGCP 0;
BA_ "GenSigTimeoutTime_MCPA" SG_ 2651930825 Digit_08_SGCP 0;
BA_ "GenSigTimeoutTime_MCPB" SG_ 2651930825 Digit_08_SGCP 0;
BA_ "GenSigTimeoutTime_SGCP" SG_ 2651930825 Digit_08_SGCP 0;
BA_ "GenSigTimeoutTime_TCM" SG_ 2651930825 Digit_08_SGCP 0;
BA_ "GenSigTimeoutTime_AGSM" SG_ 2651930825 Digit_07_SGCP 0;
BA_ "GenSigTimeoutTime_ECM" SG_ 2651930825 Digit_07_SGCP 0;
BA_ "GenSigTimeoutTime_MCPA" SG_ 2651930825 Digit_07_SGCP 0;
BA_ "GenSigTimeoutTime_MCPB" SG_ 2651930825 Digit_07_SGCP 0;
BA_ "GenSigTimeoutTime_SGCP" SG_ 2651930825 Digit_07_SGCP 0;
BA_ "GenSigTimeoutTime_TCM" SG_ 2651930825 Digit_07_SGCP 0;
BA_ "GenSigTimeoutTime_AGSM" SG_ 2651930825 Digit_06_SGCP 0;
BA_ "GenSigTimeoutTime_ECM" SG_ 2651930825 Digit_06_SGCP 0;
BA_ "GenSigTimeoutTime_MCPA" SG_ 2651930825 Digit_06_SGCP 0;
BA_ "GenSigTimeoutTime_MCPB" SG_ 2651930825 Digit_06_SGCP 0;
BA_ "GenSigTimeoutTime_SGCP" SG_ 2651930825 Digit_06_SGCP 0;
BA_ "GenSigTimeoutTime_TCM" SG_ 2651930825 Digit_06_SGCP 0;
BA_ "GenSigTimeoutTime_AGSM" SG_ 2651930825 Digit_05_SGCP 0;
BA_ "GenSigTimeoutTime_ECM" SG_ 2651930825 Digit_05_SGCP 0;
BA_ "GenSigTimeoutTime_MCPA" SG_ 2651930825 Digit_05_SGCP 0;
BA_ "GenSigTimeoutTime_MCPB" SG_ 2651930825 Digit_05_SGCP 0;
BA_ "GenSigTimeoutTime_SGCP" SG_ 2651930825 Digit_05_SGCP 0;
BA_ "GenSigTimeoutTime_TCM" SG_ 2651930825 Digit_05_SGCP 0;
BA_ "GenSigTimeoutTime_AGSM" SG_ 2651930825 Digit_04_SGCP 0;
BA_ "GenSigTimeoutTime_ECM" SG_ 2651930825 Digit_04_SGCP 0;
BA_ "GenSigTimeoutTime_MCPA" SG_ 2651930825 Digit_04_SGCP 0;
BA_ "GenSigTimeoutTime_MCPB" SG_ 2651930825 Digit_04_SGCP 0;
BA_ "GenSigTimeoutTime_SGCP" SG_ 2651930825 Digit_04_SGCP 0;
BA_ "GenSigTimeoutTime_TCM" SG_ 2651930825 Digit_04_SGCP 0;
BA_ "GenSigTimeoutTime_AGSM" SG_ 2651930825 Digit_03_SGCP 0;
BA_ "GenSigTimeoutTime_ECM" SG_ 2651930825 Digit_03_SGCP 0;
BA_ "GenSigTimeoutTime_MCPA" SG_ 2651930825 Digit_03_SGCP 0;
BA_ "GenSigTimeoutTime_MCPB" SG_ 2651930825 Digit_03_SGCP 0;
BA_ "GenSigTimeoutTime_SGCP" SG_ 2651930825 Digit_03_SGCP 0;
BA_ "GenSigTimeoutTime_TCM" SG_ 2651930825 Digit_03_SGCP 0;
BA_ "GenSigTimeoutTime_AGSM" SG_ 2651930825 Digit_02_SGCP 0;
BA_ "GenSigTimeoutTime_ECM" SG_ 2651930825 Digit_02_SGCP 0;
BA_ "GenSigTimeoutTime_MCPA" SG_ 2651930825 Digit_02_SGCP 0;
BA_ "GenSigTimeoutTime_MCPB" SG_ 2651930825 Digit_02_SGCP 0;
BA_ "GenSigTimeoutTime_SGCP" SG_ 2651930825 Digit_02_SGCP 0;
BA_ "GenSigTimeoutTime_TCM" SG_ 2651930825 Digit_02_SGCP 0;
BA_ "GenSigSendType" SG_ 2651930825 Digit_01_SGCP 1;
BA_ "GenSigTimeoutTime_AGSM" SG_ 2651930825 Digit_01_SGCP 0;
BA_ "GenSigTimeoutTime_ECM" SG_ 2651930825 Digit_01_SGCP 0;
BA_ "GenSigTimeoutTime_MCPA" SG_ 2651930825 Digit_01_SGCP 0;
BA_ "GenSigTimeoutTime_MCPB" SG_ 2651930825 Digit_01_SGCP 0;
BA_ "GenSigTimeoutTime_SGCP" SG_ 2651930825 Digit_01_SGCP 0;
BA_ "GenSigTimeoutTime_TCM" SG_ 2651930825 Digit_01_SGCP 0;
BA_ "GenSigTimeoutTime_AGSM" SG_ 216 BatteryVoltage_Raw_PT 0;
BA_ "GenSigTimeoutTime_ECM" SG_ 216 BatteryVoltage_Raw_PT 0;
BA_ "GenSigTimeoutTime_EVCU2" SG_ 216 BatteryVoltage_Raw_PT 0;
BA_ "GenSigTimeoutTime_SGCP" SG_ 216 BatteryVoltage_Raw_PT 0;
BA_ "GenSigTimeoutTime_TCM" SG_ 216 BatteryVoltage_Raw_PT 0;
BA_ "GenSigTimeoutTime_AGSM" SG_ 2654486592 CBV_bit2_1E384040 0;
BA_ "GenSigTimeoutTime_ECM" SG_ 2654486592 CBV_bit2_1E384040 0;
BA_ "GenSigTimeoutTime_EVCU2" SG_ 2654486592 CBV_bit2_1E384040 0;
BA_ "GenSigTimeoutTime_MCPA" SG_ 2654486592 CBV_bit2_1E384040 0;
BA_ "GenSigTimeoutTime_MCPB" SG_ 2654486592 CBV_bit2_1E384040 0;
BA_ "GenSigTimeoutTime_SGCP" SG_ 2654486592 CBV_bit2_1E384040 0;
BA_ "GenSigTimeoutTime_TCM" SG_ 2654486592 CBV_bit2_1E384040 0;
BA_ "GenSigTimeoutTime_AGSM" SG_ 2654486592 CBV_bit3_NMCoordinatorBit_1_0002 0;
BA_ "GenSigTimeoutTime_ECM" SG_ 2654486592 CBV_bit3_NMCoordinatorBit_1_0002 0;
BA_ "GenSigTimeoutTime_EVCU2" SG_ 2654486592 CBV_bit3_NMCoordinatorBit_1_0002 0;
BA_ "GenSigTimeoutTime_MCPA" SG_ 2654486592 CBV_bit3_NMCoordinatorBit_1_0002 0;
BA_ "GenSigTimeoutTime_MCPB" SG_ 2654486592 CBV_bit3_NMCoordinatorBit_1_0002 0;
BA_ "GenSigTimeoutTime_SGCP" SG_ 2654486592 CBV_bit3_NMCoordinatorBit_1_0002 0;
BA_ "GenSigTimeoutTime_TCM" SG_ 2654486592 CBV_bit3_NMCoordinatorBit_1_0002 0;
BA_ "SystemSignalLongSymbol" SG_ 2654486592 CBV_bit3_NMCoordinatorBit_1_0002 "CBV_bit3_NMCoordinatorBit_1E384040";
BA_ "GenSigTimeoutTime_AGSM" SG_ 2654486592 CBV_bit4_ActiveWakeupBit_1E38404 0;
BA_ "GenSigTimeoutTime_ECM" SG_ 2654486592 CBV_bit4_ActiveWakeupBit_1E38404 0;
BA_ "GenSigTimeoutTime_EVCU2" SG_ 2654486592 CBV_bit4_ActiveWakeupBit_1E38404 0;
BA_ "GenSigTimeoutTime_MCPA" SG_ 2654486592 CBV_bit4_ActiveWakeupBit_1E38404 0;
BA_ "GenSigTimeoutTime_MCPB" SG_ 2654486592 CBV_bit4_ActiveWakeupBit_1E38404 0;
BA_ "GenSigTimeoutTime_SGCP" SG_ 2654486592 CBV_bit4_ActiveWakeupBit_1E38404 0;
BA_ "GenSigTimeoutTime_TCM" SG_ 2654486592 CBV_bit4_ActiveWakeupBit_1E38404 0;
BA_ "SystemSignalLongSymbol" SG_ 2654486592 CBV_bit4_ActiveWakeupBit_1E38404 "CBV_bit4_ActiveWakeupBit_1E384040";
BA_ "GenSigTimeoutTime_AGSM" SG_ 2654486592 CBV_bit5_1E384040 0;
BA_ "GenSigTimeoutTime_ECM" SG_ 2654486592 CBV_bit5_1E384040 0;
BA_ "GenSigTimeoutTime_EVCU2" SG_ 2654486592 CBV_bit5_1E384040 0;
BA_ "GenSigTimeoutTime_MCPA" SG_ 2654486592 CBV_bit5_1E384040 0;
BA_ "GenSigTimeoutTime_MCPB" SG_ 2654486592 CBV_bit5_1E384040 0;
BA_ "GenSigTimeoutTime_SGCP" SG_ 2654486592 CBV_bit5_1E384040 0;
BA_ "GenSigTimeoutTime_TCM" SG_ 2654486592 CBV_bit5_1E384040 0;
BA_ "GenSigTimeoutTime_AGSM" SG_ 2654486592 CBV_bit6_PartialNtwInfBit_1_0002 0;
BA_ "GenSigTimeoutTime_ECM" SG_ 2654486592 CBV_bit6_PartialNtwInfBit_1_0002 0;
BA_ "GenSigTimeoutTime_EVCU2" SG_ 2654486592 CBV_bit6_PartialNtwInfBit_1_0002 0;
BA_ "GenSigTimeoutTime_MCPA" SG_ 2654486592 CBV_bit6_PartialNtwInfBit_1_0002 0;
BA_ "GenSigTimeoutTime_MCPB" SG_ 2654486592 CBV_bit6_PartialNtwInfBit_1_0002 0;
BA_ "GenSigTimeoutTime_SGCP" SG_ 2654486592 CBV_bit6_PartialNtwInfBit_1_0002 0;
BA_ "GenSigTimeoutTime_TCM" SG_ 2654486592 CBV_bit6_PartialNtwInfBit_1_0002 0;
BA_ "SystemSignalLongSymbol" SG_ 2654486592 CBV_bit6_PartialNtwInfBit_1_0002 "CBV_bit6_PartialNtwInfBit_1E384040";
BA_ "GenSigTimeoutTime_AGSM" SG_ 2654486592 CBV_bit7_1E384040 0;
BA_ "GenSigTimeoutTime_ECM" SG_ 2654486592 CBV_bit7_1E384040 0;
BA_ "GenSigTimeoutTime_EVCU2" SG_ 2654486592 CBV_bit7_1E384040 0;
BA_ "GenSigTimeoutTime_MCPA" SG_ 2654486592 CBV_bit7_1E384040 0;
BA_ "GenSigTimeoutTime_MCPB" SG_ 2654486592 CBV_bit7_1E384040 0;
BA_ "GenSigTimeoutTime_SGCP" SG_ 2654486592 CBV_bit7_1E384040 0;
BA_ "GenSigTimeoutTime_TCM" SG_ 2654486592 CBV_bit7_1E384040 0;
BA_ "GenSigTimeoutTime_AGSM" SG_ 2654486592 CBV_bit0_RepeatMessageReque_0002 0;
BA_ "GenSigTimeoutTime_ECM" SG_ 2654486592 CBV_bit0_RepeatMessageReque_0002 0;
BA_ "GenSigTimeoutTime_EVCU2" SG_ 2654486592 CBV_bit0_RepeatMessageReque_0002 0;
BA_ "GenSigTimeoutTime_MCPA" SG_ 2654486592 CBV_bit0_RepeatMessageReque_0002 0;
BA_ "GenSigTimeoutTime_MCPB" SG_ 2654486592 CBV_bit0_RepeatMessageReque_0002 0;
BA_ "GenSigTimeoutTime_SGCP" SG_ 2654486592 CBV_bit0_RepeatMessageReque_0002 0;
BA_ "GenSigTimeoutTime_TCM" SG_ 2654486592 CBV_bit0_RepeatMessageReque_0002 0;
BA_ "SystemSignalLongSymbol" SG_ 2654486592 CBV_bit0_RepeatMessageReque_0002 "CBV_bit0_RepeatMessageRequestBit_1E384040";
BA_ "GenSigTimeoutTime_AGSM" SG_ 2654486592 CBV_bit1_1E384040 0;
BA_ "GenSigTimeoutTime_ECM" SG_ 2654486592 CBV_bit1_1E384040 0;
BA_ "GenSigTimeoutTime_EVCU2" SG_ 2654486592 CBV_bit1_1E384040 0;
BA_ "GenSigTimeoutTime_MCPA" SG_ 2654486592 CBV_bit1_1E384040 0;
BA_ "GenSigTimeoutTime_MCPB" SG_ 2654486592 CBV_bit1_1E384040 0;
BA_ "GenSigTimeoutTime_SGCP" SG_ 2654486592 CBV_bit1_1E384040 0;
BA_ "GenSigTimeoutTime_TCM" SG_ 2654486592 CBV_bit1_1E384040 0;
BA_ "GenSigTimeoutTime_AGSM" SG_ 2654486592 SourceNodeIdentifier_1E384040 0;
BA_ "GenSigTimeoutTime_ECM" SG_ 2654486592 SourceNodeIdentifier_1E384040 0;
BA_ "GenSigTimeoutTime_EVCU2" SG_ 2654486592 SourceNodeIdentifier_1E384040 0;
BA_ "GenSigTimeoutTime_MCPA" SG_ 2654486592 SourceNodeIdentifier_1E384040 0;
BA_ "GenSigTimeoutTime_MCPB" SG_ 2654486592 SourceNodeIdentifier_1E384040 0;
BA_ "GenSigTimeoutTime_SGCP" SG_ 2654486592 SourceNodeIdentifier_1E384040 0;
BA_ "GenSigTimeoutTime_TCM" SG_ 2654486592 SourceNodeIdentifier_1E384040 0;
BA_ "GenSigTimeoutTime_TCM" SG_ 1811 Real_Time_Validity 0;
BA_ "GenSigTimeoutTime_AGSM" SG_ 1811 Real_Time_Validity 0;
BA_ "GenSigTimeoutTime_ECM" SG_ 1811 Real_Time_Validity 0;
BA_ "GenSigTimeoutTime_EVCU2" SG_ 1811 Real_Time_Validity 0;
BA_ "GenSigTimeoutTime_TCM" SG_ 1811 Real_Time_Clock 0;
BA_ "GenSigTimeoutTime_AGSM" SG_ 1811 Real_Time_Clock 0;
BA_ "GenSigTimeoutTime_ECM" SG_ 1811 Real_Time_Clock 0;
BA_ "GenSigTimeoutTime_EVCU2" SG_ 1811 Real_Time_Clock 0;
BA_ "GenSigTimeoutTime_AGSM" SG_ 1070 SGCP_DTC_Stat2 0;
BA_ "GenSigTimeoutTime_ECM" SG_ 1070 SGCP_DTC_Stat2 0;
BA_ "GenSigTimeoutTime_MCPA" SG_ 1070 SGCP_DTC_Stat2 0;
BA_ "GenSigTimeoutTime_MCPB" SG_ 1070 SGCP_DTC_Stat2 0;
BA_ "GenSigTimeoutTime_SGCP" SG_ 1070 SGCP_DTC_Stat2 0;
BA_ "GenSigTimeoutTime_TCM" SG_ 1070 SGCP_DTC_Stat2 0;
BA_ "GenSigTimeoutTime_AGSM" SG_ 1070 SGCP_DTC_Stat1 0;
BA_ "GenSigTimeoutTime_ECM" SG_ 1070 SGCP_DTC_Stat1 0;
BA_ "GenSigTimeoutTime_MCPA" SG_ 1070 SGCP_DTC_Stat1 0;
BA_ "GenSigTimeoutTime_MCPB" SG_ 1070 SGCP_DTC_Stat1 0;
BA_ "GenSigTimeoutTime_SGCP" SG_ 1070 SGCP_DTC_Stat1 0;
BA_ "GenSigTimeoutTime_TCM" SG_ 1070 SGCP_DTC_Stat1 0;
BA_ "GenSigTimeoutTime_AGSM" SG_ 1070 SGCP_DTC_Idx2 0;
BA_ "GenSigTimeoutTime_ECM" SG_ 1070 SGCP_DTC_Idx2 0;
BA_ "GenSigTimeoutTime_MCPA" SG_ 1070 SGCP_DTC_Idx2 0;
BA_ "GenSigTimeoutTime_MCPB" SG_ 1070 SGCP_DTC_Idx2 0;
BA_ "GenSigTimeoutTime_SGCP" SG_ 1070 SGCP_DTC_Idx2 0;
BA_ "GenSigTimeoutTime_TCM" SG_ 1070 SGCP_DTC_Idx2 0;
BA_ "GenSigTimeoutTime_AGSM" SG_ 1070 SGCP_DTC_Idx1 0;
BA_ "GenSigTimeoutTime_ECM" SG_ 1070 SGCP_DTC_Idx1 0;
BA_ "GenSigTimeoutTime_MCPA" SG_ 1070 SGCP_DTC_Idx1 0;
BA_ "GenSigTimeoutTime_MCPB" SG_ 1070 SGCP_DTC_Idx1 0;
BA_ "GenSigTimeoutTime_SGCP" SG_ 1070 SGCP_DTC_Idx1 0;
BA_ "GenSigTimeoutTime_TCM" SG_ 1070 SGCP_DTC_Idx1 0;
BA_ "GenSigTimeoutTime_AGSM" SG_ 1070 SGCP_CalChar 0;
BA_ "GenSigTimeoutTime_ECM" SG_ 1070 SGCP_CalChar 0;
BA_ "GenSigTimeoutTime_MCPA" SG_ 1070 SGCP_CalChar 0;
BA_ "GenSigTimeoutTime_MCPB" SG_ 1070 SGCP_CalChar 0;
BA_ "GenSigTimeoutTime_SGCP" SG_ 1070 SGCP_CalChar 0;
BA_ "GenSigTimeoutTime_TCM" SG_ 1070 SGCP_CalChar 0;
BA_ "GenSigTimeoutTime_AGSM" SG_ 1070 SGCP_Cal_ID_Idx 0;
BA_ "GenSigTimeoutTime_ECM" SG_ 1070 SGCP_Cal_ID_Idx 0;
BA_ "GenSigTimeoutTime_MCPA" SG_ 1070 SGCP_Cal_ID_Idx 0;
BA_ "GenSigTimeoutTime_MCPB" SG_ 1070 SGCP_Cal_ID_Idx 0;
BA_ "GenSigTimeoutTime_SGCP" SG_ 1070 SGCP_Cal_ID_Idx 0;
BA_ "GenSigTimeoutTime_TCM" SG_ 1070 SGCP_Cal_ID_Idx 0;
BA_ "GenSigTimeoutTime_AGSM" SG_ 1070 MessageCounter_SGCP_OBD_DTC 0;
BA_ "GenSigTimeoutTime_ECM" SG_ 1070 MessageCounter_SGCP_OBD_DTC 0;
BA_ "GenSigTimeoutTime_MCPA" SG_ 1070 MessageCounter_SGCP_OBD_DTC 0;
BA_ "GenSigTimeoutTime_MCPB" SG_ 1070 MessageCounter_SGCP_OBD_DTC 0;
BA_ "GenSigTimeoutTime_SGCP" SG_ 1070 MessageCounter_SGCP_OBD_DTC 0;
BA_ "GenSigTimeoutTime_TCM" SG_ 1070 MessageCounter_SGCP_OBD_DTC 0;
BA_ "GenSigTimeoutTime_AGSM" SG_ 1070 CRC_SGCP_OBD_DTC 0;
BA_ "GenSigTimeoutTime_ECM" SG_ 1070 CRC_SGCP_OBD_DTC 0;
BA_ "GenSigTimeoutTime_MCPA" SG_ 1070 CRC_SGCP_OBD_DTC 0;
BA_ "GenSigTimeoutTime_MCPB" SG_ 1070 CRC_SGCP_OBD_DTC 0;
BA_ "GenSigTimeoutTime_SGCP" SG_ 1070 CRC_SGCP_OBD_DTC 0;
BA_ "GenSigTimeoutTime_TCM" SG_ 1070 CRC_SGCP_OBD_DTC 0;
BA_ "GenSigTimeoutTime_AGSM" SG_ 1065 MessageCounter_MCPB_OBD_DTC 0;
BA_ "GenSigTimeoutTime_ECM" SG_ 1065 MessageCounter_MCPB_OBD_DTC 0;
BA_ "GenSigTimeoutTime_MCPA" SG_ 1065 MessageCounter_MCPB_OBD_DTC 0;
BA_ "GenSigTimeoutTime_MCPB" SG_ 1065 MessageCounter_MCPB_OBD_DTC 0;
BA_ "GenSigTimeoutTime_SGCP" SG_ 1065 MessageCounter_MCPB_OBD_DTC 0;
BA_ "GenSigTimeoutTime_TCM" SG_ 1065 MessageCounter_MCPB_OBD_DTC 0;
BA_ "GenSigTimeoutTime_AGSM" SG_ 1065 MCPB_DTC_Stat2 0;
BA_ "GenSigTimeoutTime_ECM" SG_ 1065 MCPB_DTC_Stat2 0;
BA_ "GenSigTimeoutTime_MCPA" SG_ 1065 MCPB_DTC_Stat2 0;
BA_ "GenSigTimeoutTime_MCPB" SG_ 1065 MCPB_DTC_Stat2 0;
BA_ "GenSigTimeoutTime_SGCP" SG_ 1065 MCPB_DTC_Stat2 0;
BA_ "GenSigTimeoutTime_TCM" SG_ 1065 MCPB_DTC_Stat2 0;
BA_ "GenSigTimeoutTime_AGSM" SG_ 1065 MCPB_DTC_Stat1 0;
BA_ "GenSigTimeoutTime_ECM" SG_ 1065 MCPB_DTC_Stat1 0;
BA_ "GenSigTimeoutTime_MCPA" SG_ 1065 MCPB_DTC_Stat1 0;
BA_ "GenSigTimeoutTime_MCPB" SG_ 1065 MCPB_DTC_Stat1 0;
BA_ "GenSigTimeoutTime_SGCP" SG_ 1065 MCPB_DTC_Stat1 0;
BA_ "GenSigTimeoutTime_TCM" SG_ 1065 MCPB_DTC_Stat1 0;
BA_ "GenSigTimeoutTime_AGSM" SG_ 1065 MCPB_DTC_Idx2 0;
BA_ "GenSigTimeoutTime_ECM" SG_ 1065 MCPB_DTC_Idx2 0;
BA_ "GenSigTimeoutTime_MCPA" SG_ 1065 MCPB_DTC_Idx2 0;
BA_ "GenSigTimeoutTime_MCPB" SG_ 1065 MCPB_DTC_Idx2 0;
BA_ "GenSigTimeoutTime_SGCP" SG_ 1065 MCPB_DTC_Idx2 0;
BA_ "GenSigTimeoutTime_TCM" SG_ 1065 MCPB_DTC_Idx2 0;
BA_ "GenSigTimeoutTime_AGSM" SG_ 1065 MCPB_DTC_Idx1 0;
BA_ "GenSigTimeoutTime_ECM" SG_ 1065 MCPB_DTC_Idx1 0;
BA_ "GenSigTimeoutTime_MCPA" SG_ 1065 MCPB_DTC_Idx1 0;
BA_ "GenSigTimeoutTime_MCPB" SG_ 1065 MCPB_DTC_Idx1 0;
BA_ "GenSigTimeoutTime_SGCP" SG_ 1065 MCPB_DTC_Idx1 0;
BA_ "GenSigTimeoutTime_TCM" SG_ 1065 MCPB_DTC_Idx1 0;
BA_ "GenSigTimeoutTime_AGSM" SG_ 1065 MCPB_CalChar 0;
BA_ "GenSigTimeoutTime_ECM" SG_ 1065 MCPB_CalChar 0;
BA_ "GenSigTimeoutTime_MCPA" SG_ 1065 MCPB_CalChar 0;
BA_ "GenSigTimeoutTime_MCPB" SG_ 1065 MCPB_CalChar 0;
BA_ "GenSigTimeoutTime_SGCP" SG_ 1065 MCPB_CalChar 0;
BA_ "GenSigTimeoutTime_TCM" SG_ 1065 MCPB_CalChar 0;
BA_ "GenSigTimeoutTime_AGSM" SG_ 1065 MCPB_Cal_ID_Idx 0;
BA_ "GenSigTimeoutTime_ECM" SG_ 1065 MCPB_Cal_ID_Idx 0;
BA_ "GenSigTimeoutTime_MCPA" SG_ 1065 MCPB_Cal_ID_Idx 0;
BA_ "GenSigTimeoutTime_MCPB" SG_ 1065 MCPB_Cal_ID_Idx 0;
BA_ "GenSigTimeoutTime_SGCP" SG_ 1065 MCPB_Cal_ID_Idx 0;
BA_ "GenSigTimeoutTime_TCM" SG_ 1065 MCPB_Cal_ID_Idx 0;
BA_ "GenSigTimeoutTime_AGSM" SG_ 1065 CRC_MCPB_OBD_DTC 0;
BA_ "GenSigTimeoutTime_ECM" SG_ 1065 CRC_MCPB_OBD_DTC 0;
BA_ "GenSigTimeoutTime_MCPA" SG_ 1065 CRC_MCPB_OBD_DTC 0;
BA_ "GenSigTimeoutTime_MCPB" SG_ 1065 CRC_MCPB_OBD_DTC 0;
BA_ "GenSigTimeoutTime_SGCP" SG_ 1065 CRC_MCPB_OBD_DTC 0;
BA_ "GenSigTimeoutTime_TCM" SG_ 1065 CRC_MCPB_OBD_DTC 0;
BA_ "GenSigTimeoutTime_AGSM" SG_ 1057 MessageCounter_MCPA_OBD_DTC 0;
BA_ "GenSigTimeoutTime_ECM" SG_ 1057 MessageCounter_MCPA_OBD_DTC 0;
BA_ "GenSigTimeoutTime_MCPA" SG_ 1057 MessageCounter_MCPA_OBD_DTC 0;
BA_ "GenSigTimeoutTime_MCPB" SG_ 1057 MessageCounter_MCPA_OBD_DTC 0;
BA_ "GenSigTimeoutTime_SGCP" SG_ 1057 MessageCounter_MCPA_OBD_DTC 0;
BA_ "GenSigTimeoutTime_TCM" SG_ 1057 MessageCounter_MCPA_OBD_DTC 0;
BA_ "GenSigTimeoutTime_AGSM" SG_ 1057 MCPA_DTC_Stat2 0;
BA_ "GenSigTimeoutTime_ECM" SG_ 1057 MCPA_DTC_Stat2 0;
BA_ "GenSigTimeoutTime_MCPA" SG_ 1057 MCPA_DTC_Stat2 0;
BA_ "GenSigTimeoutTime_MCPB" SG_ 1057 MCPA_DTC_Stat2 0;
BA_ "GenSigTimeoutTime_SGCP" SG_ 1057 MCPA_DTC_Stat2 0;
BA_ "GenSigTimeoutTime_TCM" SG_ 1057 MCPA_DTC_Stat2 0;
BA_ "GenSigTimeoutTime_AGSM" SG_ 1057 MCPA_DTC_Stat1 0;
BA_ "GenSigTimeoutTime_ECM" SG_ 1057 MCPA_DTC_Stat1 0;
BA_ "GenSigTimeoutTime_MCPA" SG_ 1057 MCPA_DTC_Stat1 0;
BA_ "GenSigTimeoutTime_MCPB" SG_ 1057 MCPA_DTC_Stat1 0;
BA_ "GenSigTimeoutTime_SGCP" SG_ 1057 MCPA_DTC_Stat1 0;
BA_ "GenSigTimeoutTime_TCM" SG_ 1057 MCPA_DTC_Stat1 0;
BA_ "GenSigTimeoutTime_AGSM" SG_ 1057 MCPA_DTC_Idx2 0;
BA_ "GenSigTimeoutTime_ECM" SG_ 1057 MCPA_DTC_Idx2 0;
BA_ "GenSigTimeoutTime_MCPA" SG_ 1057 MCPA_DTC_Idx2 0;
BA_ "GenSigTimeoutTime_MCPB" SG_ 1057 MCPA_DTC_Idx2 0;
BA_ "GenSigTimeoutTime_SGCP" SG_ 1057 MCPA_DTC_Idx2 0;
BA_ "GenSigTimeoutTime_TCM" SG_ 1057 MCPA_DTC_Idx2 0;
BA_ "GenSigTimeoutTime_AGSM" SG_ 1057 MCPA_DTC_Idx1 0;
BA_ "GenSigTimeoutTime_ECM" SG_ 1057 MCPA_DTC_Idx1 0;
BA_ "GenSigTimeoutTime_MCPA" SG_ 1057 MCPA_DTC_Idx1 0;
BA_ "GenSigTimeoutTime_MCPB" SG_ 1057 MCPA_DTC_Idx1 0;
BA_ "GenSigTimeoutTime_SGCP" SG_ 1057 MCPA_DTC_Idx1 0;
BA_ "GenSigTimeoutTime_TCM" SG_ 1057 MCPA_DTC_Idx1 0;
BA_ "GenSigTimeoutTime_AGSM" SG_ 1057 MCPA_CalChar 0;
BA_ "GenSigTimeoutTime_ECM" SG_ 1057 MCPA_CalChar 0;
BA_ "GenSigTimeoutTime_MCPA" SG_ 1057 MCPA_CalChar 0;
BA_ "GenSigTimeoutTime_MCPB" SG_ 1057 MCPA_CalChar 0;
BA_ "GenSigTimeoutTime_SGCP" SG_ 1057 MCPA_CalChar 0;
BA_ "GenSigTimeoutTime_TCM" SG_ 1057 MCPA_CalChar 0;
BA_ "GenSigTimeoutTime_AGSM" SG_ 1057 MCPA_Cal_ID_Idx 0;
BA_ "GenSigTimeoutTime_ECM" SG_ 1057 MCPA_Cal_ID_Idx 0;
BA_ "GenSigTimeoutTime_MCPA" SG_ 1057 MCPA_Cal_ID_Idx 0;
BA_ "GenSigTimeoutTime_MCPB" SG_ 1057 MCPA_Cal_ID_Idx 0;
BA_ "GenSigTimeoutTime_SGCP" SG_ 1057 MCPA_Cal_ID_Idx 0;
BA_ "GenSigTimeoutTime_TCM" SG_ 1057 MCPA_Cal_ID_Idx 0;
BA_ "GenSigTimeoutTime_AGSM" SG_ 1057 CRC_MCPA_OBD_DTC 0;
BA_ "GenSigTimeoutTime_ECM" SG_ 1057 CRC_MCPA_OBD_DTC 0;
BA_ "GenSigTimeoutTime_MCPA" SG_ 1057 CRC_MCPA_OBD_DTC 0;
BA_ "GenSigTimeoutTime_MCPB" SG_ 1057 CRC_MCPA_OBD_DTC 0;
BA_ "GenSigTimeoutTime_SGCP" SG_ 1057 CRC_MCPA_OBD_DTC 0;
BA_ "GenSigTimeoutTime_TCM" SG_ 1057 CRC_MCPA_OBD_DTC 0;
BA_ "GenSigTimeoutTime_AGSM" SG_ 505 SGCP_DerateReason_P 0;
BA_ "GenSigTimeoutTime_ECM" SG_ 505 SGCP_DerateReason_P 0;
BA_ "GenSigTimeoutTime_MCPA" SG_ 505 SGCP_DerateReason_P 0;
BA_ "GenSigTimeoutTime_MCPB" SG_ 505 SGCP_DerateReason_P 0;
BA_ "GenSigTimeoutTime_SGCP" SG_ 505 SGCP_DerateReason_P 0;
BA_ "GenSigTimeoutTime_AGSM" SG_ 505 SGCP_DC_Voltage_P 0;
BA_ "GenSigTimeoutTime_ECM" SG_ 505 SGCP_DC_Voltage_P 0;
BA_ "GenSigTimeoutTime_MCPA" SG_ 505 SGCP_DC_Voltage_P 0;
BA_ "GenSigTimeoutTime_MCPB" SG_ 505 SGCP_DC_Voltage_P 0;
BA_ "GenSigTimeoutTime_SGCP" SG_ 505 SGCP_DC_Voltage_P 0;
BA_ "GenSigTimeoutTime_AGSM" SG_ 505 SGCP_DC_Volt_V_P 0;
BA_ "GenSigTimeoutTime_ECM" SG_ 505 SGCP_DC_Volt_V_P 0;
BA_ "GenSigTimeoutTime_MCPA" SG_ 505 SGCP_DC_Volt_V_P 0;
BA_ "GenSigTimeoutTime_MCPB" SG_ 505 SGCP_DC_Volt_V_P 0;
BA_ "GenSigTimeoutTime_SGCP" SG_ 505 SGCP_DC_Volt_V_P 0;
BA_ "GenSigTimeoutTime_AGSM" SG_ 505 SGCP_DC_Current_V_P 0;
BA_ "GenSigTimeoutTime_ECM" SG_ 505 SGCP_DC_Current_V_P 0;
BA_ "GenSigTimeoutTime_MCPA" SG_ 505 SGCP_DC_Current_V_P 0;
BA_ "GenSigTimeoutTime_MCPB" SG_ 505 SGCP_DC_Current_V_P 0;
BA_ "GenSigTimeoutTime_SGCP" SG_ 505 SGCP_DC_Current_V_P 0;
BA_ "GenSigStartValue" SG_ 505 SGCP_DC_Current_P 16384;
BA_ "GenSigTimeoutTime_AGSM" SG_ 505 SGCP_DC_Current_P 0;
BA_ "GenSigTimeoutTime_ECM" SG_ 505 SGCP_DC_Current_P 0;
BA_ "GenSigTimeoutTime_MCPA" SG_ 505 SGCP_DC_Current_P 0;
BA_ "GenSigTimeoutTime_MCPB" SG_ 505 SGCP_DC_Current_P 0;
BA_ "GenSigTimeoutTime_SGCP" SG_ 505 SGCP_DC_Current_P 0;
BA_ "GenSigTimeoutTime_AGSM" SG_ 505 SGCP_CoolantTemp_P 0;
BA_ "GenSigTimeoutTime_ECM" SG_ 505 SGCP_CoolantTemp_P 0;
BA_ "GenSigTimeoutTime_MCPA" SG_ 505 SGCP_CoolantTemp_P 0;
BA_ "GenSigTimeoutTime_MCPB" SG_ 505 SGCP_CoolantTemp_P 0;
BA_ "GenSigTimeoutTime_SGCP" SG_ 505 SGCP_CoolantTemp_P 0;
BA_ "GenSigTimeoutTime_AGSM" SG_ 505 MC_SGCP_STATUS 0;
BA_ "GenSigTimeoutTime_ECM" SG_ 505 MC_SGCP_STATUS 0;
BA_ "GenSigTimeoutTime_MCPA" SG_ 505 MC_SGCP_STATUS 0;
BA_ "GenSigTimeoutTime_MCPB" SG_ 505 MC_SGCP_STATUS 0;
BA_ "GenSigTimeoutTime_SGCP" SG_ 505 MC_SGCP_STATUS 0;
BA_ "GenSigTimeoutTime_AGSM" SG_ 505 CRC_SGCP_STATUS 0;
BA_ "GenSigTimeoutTime_ECM" SG_ 505 CRC_SGCP_STATUS 0;
BA_ "GenSigTimeoutTime_MCPA" SG_ 505 CRC_SGCP_STATUS 0;
BA_ "GenSigTimeoutTime_MCPB" SG_ 505 CRC_SGCP_STATUS 0;
BA_ "GenSigTimeoutTime_SGCP" SG_ 505 CRC_SGCP_STATUS 0;
BA_ "GenSigTimeoutTime_AGSM" SG_ 295 SGCP_Torque_Achieved_V_P 0;
BA_ "GenSigTimeoutTime_ECM" SG_ 295 SGCP_Torque_Achieved_V_P 0;
BA_ "GenSigTimeoutTime_MCPA" SG_ 295 SGCP_Torque_Achieved_V_P 0;
BA_ "GenSigTimeoutTime_MCPB" SG_ 295 SGCP_Torque_Achieved_V_P 0;
BA_ "GenSigTimeoutTime_SGCP" SG_ 295 SGCP_Torque_Achieved_V_P 0;
BA_ "GenSigStartValue" SG_ 295 SGCP_Torque_Achieved_P 8184;
BA_ "GenSigTimeoutTime_AGSM" SG_ 295 SGCP_Torque_Achieved_P 0;
BA_ "GenSigTimeoutTime_ECM" SG_ 295 SGCP_Torque_Achieved_P 0;
BA_ "GenSigTimeoutTime_MCPA" SG_ 295 SGCP_Torque_Achieved_P 0;
BA_ "GenSigTimeoutTime_MCPB" SG_ 295 SGCP_Torque_Achieved_P 0;
BA_ "GenSigTimeoutTime_SGCP" SG_ 295 SGCP_Torque_Achieved_P 0;
BA_ "GenSigTimeoutTime_AGSM" SG_ 295 SGCP_TorqAchieved_AEMD_V_P 0;
BA_ "GenSigTimeoutTime_ECM" SG_ 295 SGCP_TorqAchieved_AEMD_V_P 0;
BA_ "GenSigTimeoutTime_MCPA" SG_ 295 SGCP_TorqAchieved_AEMD_V_P 0;
BA_ "GenSigTimeoutTime_MCPB" SG_ 295 SGCP_TorqAchieved_AEMD_V_P 0;
BA_ "GenSigTimeoutTime_SGCP" SG_ 295 SGCP_TorqAchieved_AEMD_V_P 0;
BA_ "GenSigStartValue" SG_ 295 SGCP_TorqAchieved_AEMD_P 8184;
BA_ "GenSigTimeoutTime_AGSM" SG_ 295 SGCP_TorqAchieved_AEMD_P 0;
BA_ "GenSigTimeoutTime_ECM" SG_ 295 SGCP_TorqAchieved_AEMD_P 0;
BA_ "GenSigTimeoutTime_MCPA" SG_ 295 SGCP_TorqAchieved_AEMD_P 0;
BA_ "GenSigTimeoutTime_MCPB" SG_ 295 SGCP_TorqAchieved_AEMD_P 0;
BA_ "GenSigTimeoutTime_SGCP" SG_ 295 SGCP_TorqAchieved_AEMD_P 0;
BA_ "GenSigTimeoutTime_AGSM" SG_ 295 SGCP_SPT_Stat_P 0;
BA_ "GenSigTimeoutTime_ECM" SG_ 295 SGCP_SPT_Stat_P 0;
BA_ "GenSigTimeoutTime_MCPA" SG_ 295 SGCP_SPT_Stat_P 0;
BA_ "GenSigTimeoutTime_MCPB" SG_ 295 SGCP_SPT_Stat_P 0;
BA_ "GenSigTimeoutTime_SGCP" SG_ 295 SGCP_SPT_Stat_P 0;
BA_ "GenSigStartValue" SG_ 295 SGCP_Spd_Lim_P 32767;
BA_ "GenSigTimeoutTime_AGSM" SG_ 295 SGCP_Spd_Lim_P 0;
BA_ "GenSigTimeoutTime_ECM" SG_ 295 SGCP_Spd_Lim_P 0;
BA_ "GenSigTimeoutTime_MCPA" SG_ 295 SGCP_Spd_Lim_P 0;
BA_ "GenSigTimeoutTime_MCPB" SG_ 295 SGCP_Spd_Lim_P 0;
BA_ "GenSigTimeoutTime_SGCP" SG_ 295 SGCP_Spd_Lim_P 0;
BA_ "GenSigTimeoutTime_AGSM" SG_ 295 SGCP_RPM_V_P 0;
BA_ "GenSigTimeoutTime_ECM" SG_ 295 SGCP_RPM_V_P 0;
BA_ "GenSigTimeoutTime_MCPA" SG_ 295 SGCP_RPM_V_P 0;
BA_ "GenSigTimeoutTime_MCPB" SG_ 295 SGCP_RPM_V_P 0;
BA_ "GenSigTimeoutTime_SGCP" SG_ 295 SGCP_RPM_V_P 0;
BA_ "GenSigStartValue" SG_ 295 SGCP_RPM_P 32768;
BA_ "GenSigTimeoutTime_AGSM" SG_ 295 SGCP_RPM_P 0;
BA_ "GenSigTimeoutTime_ECM" SG_ 295 SGCP_RPM_P 0;
BA_ "GenSigTimeoutTime_MCPA" SG_ 295 SGCP_RPM_P 0;
BA_ "GenSigTimeoutTime_MCPB" SG_ 295 SGCP_RPM_P 0;
BA_ "GenSigTimeoutTime_SGCP" SG_ 295 SGCP_RPM_P 0;
BA_ "GenSigStartValue" SG_ 295 SGCP_MtrMinCpbltyTrq_P 8184;
BA_ "GenSigTimeoutTime_AGSM" SG_ 295 SGCP_MtrMinCpbltyTrq_P 0;
BA_ "GenSigTimeoutTime_ECM" SG_ 295 SGCP_MtrMinCpbltyTrq_P 0;
BA_ "GenSigTimeoutTime_MCPA" SG_ 295 SGCP_MtrMinCpbltyTrq_P 0;
BA_ "GenSigTimeoutTime_MCPB" SG_ 295 SGCP_MtrMinCpbltyTrq_P 0;
BA_ "GenSigTimeoutTime_SGCP" SG_ 295 SGCP_MtrMinCpbltyTrq_P 0;
BA_ "GenSigStartValue" SG_ 295 SGCP_MtrMaxCpbltyTrq_P 8184;
BA_ "GenSigTimeoutTime_AGSM" SG_ 295 SGCP_MtrMaxCpbltyTrq_P 0;
BA_ "GenSigTimeoutTime_ECM" SG_ 295 SGCP_MtrMaxCpbltyTrq_P 0;
BA_ "GenSigTimeoutTime_MCPA" SG_ 295 SGCP_MtrMaxCpbltyTrq_P 0;
BA_ "GenSigTimeoutTime_MCPB" SG_ 295 SGCP_MtrMaxCpbltyTrq_P 0;
BA_ "GenSigTimeoutTime_SGCP" SG_ 295 SGCP_MtrMaxCpbltyTrq_P 0;
BA_ "GenSigTimeoutTime_AGSM" SG_ 295 SGCP_MtrIndex_P 0;
BA_ "GenSigTimeoutTime_ECM" SG_ 295 SGCP_MtrIndex_P 0;
BA_ "GenSigTimeoutTime_MCPA" SG_ 295 SGCP_MtrIndex_P 0;
BA_ "GenSigTimeoutTime_MCPB" SG_ 295 SGCP_MtrIndex_P 0;
BA_ "GenSigTimeoutTime_SGCP" SG_ 295 SGCP_MtrIndex_P 0;
BA_ "GenSigStartValue" SG_ 295 SGCP_MinTorq_P 8184;
BA_ "GenSigTimeoutTime_AGSM" SG_ 295 SGCP_MinTorq_P 0;
BA_ "GenSigTimeoutTime_ECM" SG_ 295 SGCP_MinTorq_P 0;
BA_ "GenSigTimeoutTime_MCPA" SG_ 295 SGCP_MinTorq_P 0;
BA_ "GenSigTimeoutTime_MCPB" SG_ 295 SGCP_MinTorq_P 0;
BA_ "GenSigTimeoutTime_SGCP" SG_ 295 SGCP_MinTorq_P 0;
BA_ "GenSigStartValue" SG_ 295 SGCP_MaxTorq_P 8184;
BA_ "GenSigTimeoutTime_AGSM" SG_ 295 SGCP_MaxTorq_P 0;
BA_ "GenSigTimeoutTime_ECM" SG_ 295 SGCP_MaxTorq_P 0;
BA_ "GenSigTimeoutTime_MCPA" SG_ 295 SGCP_MaxTorq_P 0;
BA_ "GenSigTimeoutTime_MCPB" SG_ 295 SGCP_MaxTorq_P 0;
BA_ "GenSigTimeoutTime_SGCP" SG_ 295 SGCP_MaxTorq_P 0;
BA_ "GenSigTimeoutTime_AGSM" SG_ 295 SGCP_Invrtr_State_P 0;
BA_ "GenSigTimeoutTime_ECM" SG_ 295 SGCP_Invrtr_State_P 0;
BA_ "GenSigTimeoutTime_MCPA" SG_ 295 SGCP_Invrtr_State_P 0;
BA_ "GenSigTimeoutTime_MCPB" SG_ 295 SGCP_Invrtr_State_P 0;
BA_ "GenSigTimeoutTime_SGCP" SG_ 295 SGCP_Invrtr_State_P 0;
BA_ "GenSigTimeoutTime_AGSM" SG_ 295 SGCP_InterlockSts_P 0;
BA_ "GenSigTimeoutTime_ECM" SG_ 295 SGCP_InterlockSts_P 0;
BA_ "GenSigTimeoutTime_MCPA" SG_ 295 SGCP_InterlockSts_P 0;
BA_ "GenSigTimeoutTime_MCPB" SG_ 295 SGCP_InterlockSts_P 0;
BA_ "GenSigTimeoutTime_SGCP" SG_ 295 SGCP_InterlockSts_P 0;
BA_ "GenSigTimeoutTime_AGSM" SG_ 295 SGCP_HV_CnctrOpn_Req_P 0;
BA_ "GenSigTimeoutTime_ECM" SG_ 295 SGCP_HV_CnctrOpn_Req_P 0;
BA_ "GenSigTimeoutTime_MCPA" SG_ 295 SGCP_HV_CnctrOpn_Req_P 0;
BA_ "GenSigTimeoutTime_MCPB" SG_ 295 SGCP_HV_CnctrOpn_Req_P 0;
BA_ "GenSigTimeoutTime_SGCP" SG_ 295 SGCP_HV_CnctrOpn_Req_P 0;
BA_ "GenSigTimeoutTime_AGSM" SG_ 295 SGCP_Dschrge_Status_P 0;
BA_ "GenSigTimeoutTime_ECM" SG_ 295 SGCP_Dschrge_Status_P 0;
BA_ "GenSigTimeoutTime_MCPA" SG_ 295 SGCP_Dschrge_Status_P 0;
BA_ "GenSigTimeoutTime_MCPB" SG_ 295 SGCP_Dschrge_Status_P 0;
BA_ "GenSigTimeoutTime_SGCP" SG_ 295 SGCP_Dschrge_Status_P 0;
BA_ "GenSigTimeoutTime_AGSM" SG_ 295 SGCP_DeratingFactor_P 0;
BA_ "GenSigTimeoutTime_ECM" SG_ 295 SGCP_DeratingFactor_P 0;
BA_ "GenSigTimeoutTime_MCPA" SG_ 295 SGCP_DeratingFactor_P 0;
BA_ "GenSigTimeoutTime_MCPB" SG_ 295 SGCP_DeratingFactor_P 0;
BA_ "GenSigTimeoutTime_SGCP" SG_ 295 SGCP_DeratingFactor_P 0;
BA_ "GenSigTimeoutTime_AGSM" SG_ 295 SGCP_CpbltySpdDivVolt_P 0;
BA_ "GenSigTimeoutTime_ECM" SG_ 295 SGCP_CpbltySpdDivVolt_P 0;
BA_ "GenSigTimeoutTime_MCPA" SG_ 295 SGCP_CpbltySpdDivVolt_P 0;
BA_ "GenSigTimeoutTime_MCPB" SG_ 295 SGCP_CpbltySpdDivVolt_P 0;
BA_ "GenSigTimeoutTime_SGCP" SG_ 295 SGCP_CpbltySpdDivVolt_P 0;
BA_ "GenSigTimeoutTime_AGSM" SG_ 295 SGCP_AccelRawV_P 0;
BA_ "GenSigTimeoutTime_ECM" SG_ 295 SGCP_AccelRawV_P 0;
BA_ "GenSigTimeoutTime_MCPA" SG_ 295 SGCP_AccelRawV_P 0;
BA_ "GenSigTimeoutTime_MCPB" SG_ 295 SGCP_AccelRawV_P 0;
BA_ "GenSigTimeoutTime_SGCP" SG_ 295 SGCP_AccelRawV_P 0;
BA_ "GenSigTimeoutTime_AGSM" SG_ 295 SGCP_AccelRaw_P 0;
BA_ "GenSigTimeoutTime_ECM" SG_ 295 SGCP_AccelRaw_P 0;
BA_ "GenSigTimeoutTime_MCPA" SG_ 295 SGCP_AccelRaw_P 0;
BA_ "GenSigTimeoutTime_MCPB" SG_ 295 SGCP_AccelRaw_P 0;
BA_ "GenSigTimeoutTime_SGCP" SG_ 295 SGCP_AccelRaw_P 0;
BA_ "GenSigTimeoutTime_AGSM" SG_ 295 SGCP_6SO_Status_P 0;
BA_ "GenSigTimeoutTime_ECM" SG_ 295 SGCP_6SO_Status_P 0;
BA_ "GenSigTimeoutTime_MCPA" SG_ 295 SGCP_6SO_Status_P 0;
BA_ "GenSigTimeoutTime_MCPB" SG_ 295 SGCP_6SO_Status_P 0;
BA_ "GenSigTimeoutTime_SGCP" SG_ 295 SGCP_6SO_Status_P 0;
BA_ "GenSigTimeoutTime_AGSM" SG_ 295 SGCP_3PS_Pos_P 0;
BA_ "GenSigTimeoutTime_ECM" SG_ 295 SGCP_3PS_Pos_P 0;
BA_ "GenSigTimeoutTime_MCPA" SG_ 295 SGCP_3PS_Pos_P 0;
BA_ "GenSigTimeoutTime_MCPB" SG_ 295 SGCP_3PS_Pos_P 0;
BA_ "GenSigTimeoutTime_SGCP" SG_ 295 SGCP_3PS_Pos_P 0;
BA_ "GenSigTimeoutTime_AGSM" SG_ 295 MC_SGCP_PROPULSION 0;
BA_ "GenSigTimeoutTime_ECM" SG_ 295 MC_SGCP_PROPULSION 0;
BA_ "GenSigTimeoutTime_MCPA" SG_ 295 MC_SGCP_PROPULSION 0;
BA_ "GenSigTimeoutTime_MCPB" SG_ 295 MC_SGCP_PROPULSION 0;
BA_ "GenSigTimeoutTime_SGCP" SG_ 295 MC_SGCP_PROPULSION 0;
BA_ "GenSigTimeoutTime_AGSM" SG_ 295 CRC_SGCP_PROPULSION 0;
BA_ "GenSigTimeoutTime_ECM" SG_ 295 CRC_SGCP_PROPULSION 0;
BA_ "GenSigTimeoutTime_MCPA" SG_ 295 CRC_SGCP_PROPULSION 0;
BA_ "GenSigTimeoutTime_MCPB" SG_ 295 CRC_SGCP_PROPULSION 0;
BA_ "GenSigTimeoutTime_SGCP" SG_ 295 CRC_SGCP_PROPULSION 0;
BA_ "GenSigTimeoutTime_TCM" SG_ 504 MCPB_DerateReason_P 0;
BA_ "GenSigTimeoutTime_AGSM" SG_ 504 MCPB_DerateReason_P 0;
BA_ "GenSigTimeoutTime_ECM" SG_ 504 MCPB_DerateReason_P 0;
BA_ "GenSigTimeoutTime_MCPA" SG_ 504 MCPB_DerateReason_P 0;
BA_ "GenSigTimeoutTime_MCPB" SG_ 504 MCPB_DerateReason_P 0;
BA_ "GenSigTimeoutTime_SGCP" SG_ 504 MCPB_DerateReason_P 0;
BA_ "GenSigTimeoutTime_TCM" SG_ 504 MCPB_DC_Voltage_P 0;
BA_ "GenSigTimeoutTime_AGSM" SG_ 504 MCPB_DC_Voltage_P 0;
BA_ "GenSigTimeoutTime_ECM" SG_ 504 MCPB_DC_Voltage_P 0;
BA_ "GenSigTimeoutTime_MCPA" SG_ 504 MCPB_DC_Voltage_P 0;
BA_ "GenSigTimeoutTime_MCPB" SG_ 504 MCPB_DC_Voltage_P 0;
BA_ "GenSigTimeoutTime_SGCP" SG_ 504 MCPB_DC_Voltage_P 0;
BA_ "GenSigTimeoutTime_TCM" SG_ 504 MCPB_DC_Volt_V_P 0;
BA_ "GenSigTimeoutTime_AGSM" SG_ 504 MCPB_DC_Volt_V_P 0;
BA_ "GenSigTimeoutTime_ECM" SG_ 504 MCPB_DC_Volt_V_P 0;
BA_ "GenSigTimeoutTime_MCPA" SG_ 504 MCPB_DC_Volt_V_P 0;
BA_ "GenSigTimeoutTime_MCPB" SG_ 504 MCPB_DC_Volt_V_P 0;
BA_ "GenSigTimeoutTime_SGCP" SG_ 504 MCPB_DC_Volt_V_P 0;
BA_ "GenSigTimeoutTime_TCM" SG_ 504 MCPB_DC_Current_V_P 0;
BA_ "GenSigTimeoutTime_AGSM" SG_ 504 MCPB_DC_Current_V_P 0;
BA_ "GenSigTimeoutTime_ECM" SG_ 504 MCPB_DC_Current_V_P 0;
BA_ "GenSigTimeoutTime_MCPA" SG_ 504 MCPB_DC_Current_V_P 0;
BA_ "GenSigTimeoutTime_MCPB" SG_ 504 MCPB_DC_Current_V_P 0;
BA_ "GenSigTimeoutTime_SGCP" SG_ 504 MCPB_DC_Current_V_P 0;
BA_ "GenSigTimeoutTime_TCM" SG_ 504 MCPB_DC_Current_P 0;
BA_ "GenSigStartValue" SG_ 504 MCPB_DC_Current_P 16384;
BA_ "GenSigTimeoutTime_AGSM" SG_ 504 MCPB_DC_Current_P 0;
BA_ "GenSigTimeoutTime_ECM" SG_ 504 MCPB_DC_Current_P 0;
BA_ "GenSigTimeoutTime_MCPA" SG_ 504 MCPB_DC_Current_P 0;
BA_ "GenSigTimeoutTime_MCPB" SG_ 504 MCPB_DC_Current_P 0;
BA_ "GenSigTimeoutTime_SGCP" SG_ 504 MCPB_DC_Current_P 0;
BA_ "GenSigTimeoutTime_TCM" SG_ 504 MCPB_CoolantTemp_P 0;
BA_ "GenSigTimeoutTime_AGSM" SG_ 504 MCPB_CoolantTemp_P 0;
BA_ "GenSigTimeoutTime_ECM" SG_ 504 MCPB_CoolantTemp_P 0;
BA_ "GenSigTimeoutTime_MCPA" SG_ 504 MCPB_CoolantTemp_P 0;
BA_ "GenSigTimeoutTime_MCPB" SG_ 504 MCPB_CoolantTemp_P 0;
BA_ "GenSigTimeoutTime_SGCP" SG_ 504 MCPB_CoolantTemp_P 0;
BA_ "GenSigTimeoutTime_TCM" SG_ 504 MC_MCPB_STATUS 0;
BA_ "GenSigTimeoutTime_AGSM" SG_ 504 MC_MCPB_STATUS 0;
BA_ "GenSigTimeoutTime_ECM" SG_ 504 MC_MCPB_STATUS 0;
BA_ "GenSigTimeoutTime_MCPA" SG_ 504 MC_MCPB_STATUS 0;
BA_ "GenSigTimeoutTime_MCPB" SG_ 504 MC_MCPB_STATUS 0;
BA_ "GenSigTimeoutTime_SGCP" SG_ 504 MC_MCPB_STATUS 0;
BA_ "GenSigTimeoutTime_TCM" SG_ 504 CRC_MCPB_STATUS 0;
BA_ "GenSigTimeoutTime_AGSM" SG_ 504 CRC_MCPB_STATUS 0;
BA_ "GenSigTimeoutTime_ECM" SG_ 504 CRC_MCPB_STATUS 0;
BA_ "GenSigTimeoutTime_MCPA" SG_ 504 CRC_MCPB_STATUS 0;
BA_ "GenSigTimeoutTime_MCPB" SG_ 504 CRC_MCPB_STATUS 0;
BA_ "GenSigTimeoutTime_SGCP" SG_ 504 CRC_MCPB_STATUS 0;
BA_ "GenSigTimeoutTime_AGSM" SG_ 294 PlockFailSts_P 0;
BA_ "GenSigTimeoutTime_ECM" SG_ 294 PlockFailSts_P 0;
BA_ "GenSigTimeoutTime_MCPA" SG_ 294 PlockFailSts_P 0;
BA_ "GenSigTimeoutTime_MCPB" SG_ 294 PlockFailSts_P 0;
BA_ "GenSigTimeoutTime_SGCP" SG_ 294 PlockFailSts_P 0;
BA_ "GenSigTimeoutTime_TCM" SG_ 294 PlockFailSts_P 0;
BA_ "GenSigTimeoutTime_AGSM" SG_ 294 Plock_PosSensor_P 0;
BA_ "GenSigTimeoutTime_ECM" SG_ 294 Plock_PosSensor_P 0;
BA_ "GenSigTimeoutTime_MCPA" SG_ 294 Plock_PosSensor_P 0;
BA_ "GenSigTimeoutTime_MCPB" SG_ 294 Plock_PosSensor_P 0;
BA_ "GenSigTimeoutTime_SGCP" SG_ 294 Plock_PosSensor_P 0;
BA_ "GenSigTimeoutTime_TCM" SG_ 294 Plock_PosSensor_P 0;
BA_ "GenSigTimeoutTime_AGSM" SG_ 294 Plock_MotorPosSts_P 0;
BA_ "GenSigTimeoutTime_ECM" SG_ 294 Plock_MotorPosSts_P 0;
BA_ "GenSigTimeoutTime_MCPA" SG_ 294 Plock_MotorPosSts_P 0;
BA_ "GenSigTimeoutTime_MCPB" SG_ 294 Plock_MotorPosSts_P 0;
BA_ "GenSigTimeoutTime_SGCP" SG_ 294 Plock_MotorPosSts_P 0;
BA_ "GenSigTimeoutTime_TCM" SG_ 294 Plock_MotorPosSts_P 0;
BA_ "GenSigTimeoutTime_AGSM" SG_ 294 Plock_fdbk_sts_P 0;
BA_ "GenSigTimeoutTime_ECM" SG_ 294 Plock_fdbk_sts_P 0;
BA_ "GenSigTimeoutTime_MCPA" SG_ 294 Plock_fdbk_sts_P 0;
BA_ "GenSigTimeoutTime_MCPB" SG_ 294 Plock_fdbk_sts_P 0;
BA_ "GenSigTimeoutTime_SGCP" SG_ 294 Plock_fdbk_sts_P 0;
BA_ "GenSigTimeoutTime_TCM" SG_ 294 Plock_fdbk_sts_P 0;
BA_ "GenSigTimeoutTime_AGSM" SG_ 294 MPR_PosSensor_P 0;
BA_ "GenSigTimeoutTime_ECM" SG_ 294 MPR_PosSensor_P 0;
BA_ "GenSigTimeoutTime_MCPA" SG_ 294 MPR_PosSensor_P 0;
BA_ "GenSigTimeoutTime_MCPB" SG_ 294 MPR_PosSensor_P 0;
BA_ "GenSigTimeoutTime_SGCP" SG_ 294 MPR_PosSensor_P 0;
BA_ "GenSigTimeoutTime_TCM" SG_ 294 MPR_PosSensor_P 0;
BA_ "GenSigTimeoutTime_AGSM" SG_ 294 MCPB_Torque_Achieved_V_P 0;
BA_ "GenSigTimeoutTime_ECM" SG_ 294 MCPB_Torque_Achieved_V_P 0;
BA_ "GenSigTimeoutTime_MCPA" SG_ 294 MCPB_Torque_Achieved_V_P 0;
BA_ "GenSigTimeoutTime_MCPB" SG_ 294 MCPB_Torque_Achieved_V_P 0;
BA_ "GenSigTimeoutTime_SGCP" SG_ 294 MCPB_Torque_Achieved_V_P 0;
BA_ "GenSigTimeoutTime_TCM" SG_ 294 MCPB_Torque_Achieved_V_P 0;
BA_ "GenSigTimeoutTime_TCM" SG_ 294 MCPB_Torque_Achieved_P 0;
BA_ "GenSigStartValue" SG_ 294 MCPB_Torque_Achieved_P 8184;
BA_ "GenSigTimeoutTime_AGSM" SG_ 294 MCPB_Torque_Achieved_P 0;
BA_ "GenSigTimeoutTime_ECM" SG_ 294 MCPB_Torque_Achieved_P 0;
BA_ "GenSigTimeoutTime_MCPA" SG_ 294 MCPB_Torque_Achieved_P 0;
BA_ "GenSigTimeoutTime_MCPB" SG_ 294 MCPB_Torque_Achieved_P 0;
BA_ "GenSigTimeoutTime_SGCP" SG_ 294 MCPB_Torque_Achieved_P 0;
BA_ "GenSigTimeoutTime_TCM" SG_ 294 MCPB_TorqAchieved_AEMD_V_P 0;
BA_ "GenSigTimeoutTime_AGSM" SG_ 294 MCPB_TorqAchieved_AEMD_V_P 0;
BA_ "GenSigTimeoutTime_ECM" SG_ 294 MCPB_TorqAchieved_AEMD_V_P 0;
BA_ "GenSigTimeoutTime_MCPA" SG_ 294 MCPB_TorqAchieved_AEMD_V_P 0;
BA_ "GenSigTimeoutTime_MCPB" SG_ 294 MCPB_TorqAchieved_AEMD_V_P 0;
BA_ "GenSigTimeoutTime_SGCP" SG_ 294 MCPB_TorqAchieved_AEMD_V_P 0;
BA_ "GenSigTimeoutTime_TCM" SG_ 294 MCPB_TorqAchieved_AEMD_P 0;
BA_ "GenSigStartValue" SG_ 294 MCPB_TorqAchieved_AEMD_P 8184;
BA_ "GenSigTimeoutTime_AGSM" SG_ 294 MCPB_TorqAchieved_AEMD_P 0;
BA_ "GenSigTimeoutTime_ECM" SG_ 294 MCPB_TorqAchieved_AEMD_P 0;
BA_ "GenSigTimeoutTime_MCPA" SG_ 294 MCPB_TorqAchieved_AEMD_P 0;
BA_ "GenSigTimeoutTime_MCPB" SG_ 294 MCPB_TorqAchieved_AEMD_P 0;
BA_ "GenSigTimeoutTime_SGCP" SG_ 294 MCPB_TorqAchieved_AEMD_P 0;
BA_ "GenSigTimeoutTime_TCM" SG_ 294 MCPB_SPT_Stat_P 0;
BA_ "GenSigTimeoutTime_MCPA" SG_ 294 MCPB_SPT_Stat_P 0;
BA_ "GenSigTimeoutTime_MCPB" SG_ 294 MCPB_SPT_Stat_P 0;
BA_ "GenSigTimeoutTime_SGCP" SG_ 294 MCPB_SPT_Stat_P 0;
BA_ "GenSigTimeoutTime_AGSM" SG_ 294 MCPB_SPT_Stat_P 0;
BA_ "GenSigTimeoutTime_ECM" SG_ 294 MCPB_SPT_Stat_P 0;
BA_ "GenSigTimeoutTime_TCM" SG_ 294 MCPB_Spd_Lim_P 0;
BA_ "GenSigTimeoutTime_AGSM" SG_ 294 MCPB_Spd_Lim_P 0;
BA_ "GenSigTimeoutTime_ECM" SG_ 294 MCPB_Spd_Lim_P 0;
BA_ "GenSigTimeoutTime_MCPA" SG_ 294 MCPB_Spd_Lim_P 0;
BA_ "GenSigTimeoutTime_MCPB" SG_ 294 MCPB_Spd_Lim_P 0;
BA_ "GenSigTimeoutTime_SGCP" SG_ 294 MCPB_Spd_Lim_P 0;
BA_ "GenSigTimeoutTime_TCM" SG_ 294 MCPB_RPM_V_P 0;
BA_ "GenSigTimeoutTime_AGSM" SG_ 294 MCPB_RPM_V_P 0;
BA_ "GenSigTimeoutTime_ECM" SG_ 294 MCPB_RPM_V_P 0;
BA_ "GenSigTimeoutTime_MCPA" SG_ 294 MCPB_RPM_V_P 0;
BA_ "GenSigTimeoutTime_MCPB" SG_ 294 MCPB_RPM_V_P 0;
BA_ "GenSigTimeoutTime_SGCP" SG_ 294 MCPB_RPM_V_P 0;
BA_ "GenSigTimeoutTime_TCM" SG_ 294 MCPB_RPM_P 0;
BA_ "GenSigStartValue" SG_ 294 MCPB_RPM_P 32768;
BA_ "GenSigTimeoutTime_AGSM" SG_ 294 MCPB_RPM_P 0;
BA_ "GenSigTimeoutTime_ECM" SG_ 294 MCPB_RPM_P 0;
BA_ "GenSigTimeoutTime_MCPA" SG_ 294 MCPB_RPM_P 0;
BA_ "GenSigTimeoutTime_MCPB" SG_ 294 MCPB_RPM_P 0;
BA_ "GenSigTimeoutTime_SGCP" SG_ 294 MCPB_RPM_P 0;
BA_ "GenSigTimeoutTime_TCM" SG_ 294 MCPB_MtrMinCpbltyTrq_P 0;
BA_ "GenSigStartValue" SG_ 294 MCPB_MtrMinCpbltyTrq_P 8184;
BA_ "GenSigTimeoutTime_AGSM" SG_ 294 MCPB_MtrMinCpbltyTrq_P 0;
BA_ "GenSigTimeoutTime_ECM" SG_ 294 MCPB_MtrMinCpbltyTrq_P 0;
BA_ "GenSigTimeoutTime_MCPA" SG_ 294 MCPB_MtrMinCpbltyTrq_P 0;
BA_ "GenSigTimeoutTime_MCPB" SG_ 294 MCPB_MtrMinCpbltyTrq_P 0;
BA_ "GenSigTimeoutTime_SGCP" SG_ 294 MCPB_MtrMinCpbltyTrq_P 0;
BA_ "GenSigTimeoutTime_TCM" SG_ 294 MCPB_MtrMaxCpbltyTrq_P 0;
BA_ "GenSigStartValue" SG_ 294 MCPB_MtrMaxCpbltyTrq_P 8184;
BA_ "GenSigTimeoutTime_AGSM" SG_ 294 MCPB_MtrMaxCpbltyTrq_P 0;
BA_ "GenSigTimeoutTime_ECM" SG_ 294 MCPB_MtrMaxCpbltyTrq_P 0;
BA_ "GenSigTimeoutTime_MCPA" SG_ 294 MCPB_MtrMaxCpbltyTrq_P 0;
BA_ "GenSigTimeoutTime_MCPB" SG_ 294 MCPB_MtrMaxCpbltyTrq_P 0;
BA_ "GenSigTimeoutTime_SGCP" SG_ 294 MCPB_MtrMaxCpbltyTrq_P 0;
BA_ "GenSigTimeoutTime_TCM" SG_ 294 MCPB_MtrIndex_P 0;
BA_ "GenSigTimeoutTime_AGSM" SG_ 294 MCPB_MtrIndex_P 0;
BA_ "GenSigTimeoutTime_ECM" SG_ 294 MCPB_MtrIndex_P 0;
BA_ "GenSigTimeoutTime_MCPA" SG_ 294 MCPB_MtrIndex_P 0;
BA_ "GenSigTimeoutTime_MCPB" SG_ 294 MCPB_MtrIndex_P 0;
BA_ "GenSigTimeoutTime_SGCP" SG_ 294 MCPB_MtrIndex_P 0;
BA_ "GenSigTimeoutTime_TCM" SG_ 294 MCPB_MinTorq_P 0;
BA_ "GenSigStartValue" SG_ 294 MCPB_MinTorq_P 8184;
BA_ "GenSigTimeoutTime_AGSM" SG_ 294 MCPB_MinTorq_P 0;
BA_ "GenSigTimeoutTime_ECM" SG_ 294 MCPB_MinTorq_P 0;
BA_ "GenSigTimeoutTime_MCPA" SG_ 294 MCPB_MinTorq_P 0;
BA_ "GenSigTimeoutTime_MCPB" SG_ 294 MCPB_MinTorq_P 0;
BA_ "GenSigTimeoutTime_SGCP" SG_ 294 MCPB_MinTorq_P 0;
BA_ "GenSigTimeoutTime_TCM" SG_ 294 MCPB_MaxTorq_P 0;
BA_ "GenSigStartValue" SG_ 294 MCPB_MaxTorq_P 8184;
BA_ "GenSigTimeoutTime_AGSM" SG_ 294 MCPB_MaxTorq_P 0;
BA_ "GenSigTimeoutTime_ECM" SG_ 294 MCPB_MaxTorq_P 0;
BA_ "GenSigTimeoutTime_MCPA" SG_ 294 MCPB_MaxTorq_P 0;
BA_ "GenSigTimeoutTime_MCPB" SG_ 294 MCPB_MaxTorq_P 0;
BA_ "GenSigTimeoutTime_SGCP" SG_ 294 MCPB_MaxTorq_P 0;
BA_ "GenSigTimeoutTime_AGSM" SG_ 294 MCPB_Invrtr_State_P 0;
BA_ "GenSigTimeoutTime_ECM" SG_ 294 MCPB_Invrtr_State_P 0;
BA_ "GenSigTimeoutTime_MCPA" SG_ 294 MCPB_Invrtr_State_P 0;
BA_ "GenSigTimeoutTime_MCPB" SG_ 294 MCPB_Invrtr_State_P 0;
BA_ "GenSigTimeoutTime_SGCP" SG_ 294 MCPB_Invrtr_State_P 0;
BA_ "GenSigTimeoutTime_TCM" SG_ 294 MCPB_Invrtr_State_P 0;
BA_ "GenSigTimeoutTime_AGSM" SG_ 294 MCPB_InterlockSts_P 0;
BA_ "GenSigTimeoutTime_ECM" SG_ 294 MCPB_InterlockSts_P 0;
BA_ "GenSigTimeoutTime_MCPA" SG_ 294 MCPB_InterlockSts_P 0;
BA_ "GenSigTimeoutTime_MCPB" SG_ 294 MCPB_InterlockSts_P 0;
BA_ "GenSigTimeoutTime_SGCP" SG_ 294 MCPB_InterlockSts_P 0;
BA_ "GenSigTimeoutTime_TCM" SG_ 294 MCPB_InterlockSts_P 0;
BA_ "GenSigTimeoutTime_AGSM" SG_ 294 MCPB_HV_CnctrOpn_Req_P 0;
BA_ "GenSigTimeoutTime_ECM" SG_ 294 MCPB_HV_CnctrOpn_Req_P 0;
BA_ "GenSigTimeoutTime_MCPA" SG_ 294 MCPB_HV_CnctrOpn_Req_P 0;
BA_ "GenSigTimeoutTime_MCPB" SG_ 294 MCPB_HV_CnctrOpn_Req_P 0;
BA_ "GenSigTimeoutTime_SGCP" SG_ 294 MCPB_HV_CnctrOpn_Req_P 0;
BA_ "GenSigTimeoutTime_TCM" SG_ 294 MCPB_HV_CnctrOpn_Req_P 0;
BA_ "GenSigTimeoutTime_AGSM" SG_ 294 MCPB_Dschrge_Status_P 0;
BA_ "GenSigTimeoutTime_ECM" SG_ 294 MCPB_Dschrge_Status_P 0;
BA_ "GenSigTimeoutTime_MCPA" SG_ 294 MCPB_Dschrge_Status_P 0;
BA_ "GenSigTimeoutTime_MCPB" SG_ 294 MCPB_Dschrge_Status_P 0;
BA_ "GenSigTimeoutTime_SGCP" SG_ 294 MCPB_Dschrge_Status_P 0;
BA_ "GenSigTimeoutTime_TCM" SG_ 294 MCPB_Dschrge_Status_P 0;
BA_ "GenSigTimeoutTime_AGSM" SG_ 294 MCPB_DeratingFactor_P 0;
BA_ "GenSigTimeoutTime_ECM" SG_ 294 MCPB_DeratingFactor_P 0;
BA_ "GenSigTimeoutTime_MCPA" SG_ 294 MCPB_DeratingFactor_P 0;
BA_ "GenSigTimeoutTime_MCPB" SG_ 294 MCPB_DeratingFactor_P 0;
BA_ "GenSigTimeoutTime_SGCP" SG_ 294 MCPB_DeratingFactor_P 0;
BA_ "GenSigTimeoutTime_TCM" SG_ 294 MCPB_DeratingFactor_P 0;
BA_ "GenSigTimeoutTime_AGSM" SG_ 294 MCPB_CpbltySpdDivVolt_P 0;
BA_ "GenSigTimeoutTime_ECM" SG_ 294 MCPB_CpbltySpdDivVolt_P 0;
BA_ "GenSigTimeoutTime_MCPA" SG_ 294 MCPB_CpbltySpdDivVolt_P 0;
BA_ "GenSigTimeoutTime_MCPB" SG_ 294 MCPB_CpbltySpdDivVolt_P 0;
BA_ "GenSigTimeoutTime_SGCP" SG_ 294 MCPB_CpbltySpdDivVolt_P 0;
BA_ "GenSigTimeoutTime_TCM" SG_ 294 MCPB_CpbltySpdDivVolt_P 0;
BA_ "GenSigTimeoutTime_AGSM" SG_ 294 MCPB_AccelRawV_P 0;
BA_ "GenSigTimeoutTime_ECM" SG_ 294 MCPB_AccelRawV_P 0;
BA_ "GenSigTimeoutTime_MCPA" SG_ 294 MCPB_AccelRawV_P 0;
BA_ "GenSigTimeoutTime_MCPB" SG_ 294 MCPB_AccelRawV_P 0;
BA_ "GenSigTimeoutTime_SGCP" SG_ 294 MCPB_AccelRawV_P 0;
BA_ "GenSigTimeoutTime_TCM" SG_ 294 MCPB_AccelRawV_P 0;
BA_ "GenSigTimeoutTime_AGSM" SG_ 294 MCPB_AccelRaw_P 0;
BA_ "GenSigTimeoutTime_ECM" SG_ 294 MCPB_AccelRaw_P 0;
BA_ "GenSigTimeoutTime_MCPA" SG_ 294 MCPB_AccelRaw_P 0;
BA_ "GenSigTimeoutTime_MCPB" SG_ 294 MCPB_AccelRaw_P 0;
BA_ "GenSigTimeoutTime_SGCP" SG_ 294 MCPB_AccelRaw_P 0;
BA_ "GenSigTimeoutTime_TCM" SG_ 294 MCPB_AccelRaw_P 0;
BA_ "GenSigTimeoutTime_AGSM" SG_ 294 MCPB_6SO_Status_P 0;
BA_ "GenSigTimeoutTime_ECM" SG_ 294 MCPB_6SO_Status_P 0;
BA_ "GenSigTimeoutTime_MCPA" SG_ 294 MCPB_6SO_Status_P 0;
BA_ "GenSigTimeoutTime_MCPB" SG_ 294 MCPB_6SO_Status_P 0;
BA_ "GenSigTimeoutTime_SGCP" SG_ 294 MCPB_6SO_Status_P 0;
BA_ "GenSigTimeoutTime_TCM" SG_ 294 MCPB_6SO_Status_P 0;
BA_ "GenSigTimeoutTime_AGSM" SG_ 294 MCPB_3PS_Pos_P 0;
BA_ "GenSigTimeoutTime_ECM" SG_ 294 MCPB_3PS_Pos_P 0;
BA_ "GenSigTimeoutTime_MCPA" SG_ 294 MCPB_3PS_Pos_P 0;
BA_ "GenSigTimeoutTime_MCPB" SG_ 294 MCPB_3PS_Pos_P 0;
BA_ "GenSigTimeoutTime_SGCP" SG_ 294 MCPB_3PS_Pos_P 0;
BA_ "GenSigTimeoutTime_TCM" SG_ 294 MCPB_3PS_Pos_P 0;
BA_ "GenSigTimeoutTime_AGSM" SG_ 294 MC_MCPB_PROPULSION 0;
BA_ "GenSigTimeoutTime_ECM" SG_ 294 MC_MCPB_PROPULSION 0;
BA_ "GenSigTimeoutTime_MCPA" SG_ 294 MC_MCPB_PROPULSION 0;
BA_ "GenSigTimeoutTime_MCPB" SG_ 294 MC_MCPB_PROPULSION 0;
BA_ "GenSigTimeoutTime_SGCP" SG_ 294 MC_MCPB_PROPULSION 0;
BA_ "GenSigTimeoutTime_TCM" SG_ 294 MC_MCPB_PROPULSION 0;
BA_ "GenSigTimeoutTime_AGSM" SG_ 294 CRC_MCPB_PROPULSION 0;
BA_ "GenSigTimeoutTime_ECM" SG_ 294 CRC_MCPB_PROPULSION 0;
BA_ "GenSigTimeoutTime_MCPA" SG_ 294 CRC_MCPB_PROPULSION 0;
BA_ "GenSigTimeoutTime_MCPB" SG_ 294 CRC_MCPB_PROPULSION 0;
BA_ "GenSigTimeoutTime_SGCP" SG_ 294 CRC_MCPB_PROPULSION 0;
BA_ "GenSigTimeoutTime_TCM" SG_ 294 CRC_MCPB_PROPULSION 0;
BA_ "GenSigTimeoutTime_TCM" SG_ 503 MCPA_DerateReason_P 0;
BA_ "GenSigTimeoutTime_AGSM" SG_ 503 MCPA_DerateReason_P 0;
BA_ "GenSigTimeoutTime_ECM" SG_ 503 MCPA_DerateReason_P 0;
BA_ "GenSigTimeoutTime_MCPA" SG_ 503 MCPA_DerateReason_P 0;
BA_ "GenSigTimeoutTime_MCPB" SG_ 503 MCPA_DerateReason_P 0;
BA_ "GenSigTimeoutTime_SGCP" SG_ 503 MCPA_DerateReason_P 0;
BA_ "GenSigTimeoutTime_TCM" SG_ 503 MCPA_DC_Voltage_P 0;
BA_ "GenSigTimeoutTime_SGCP" SG_ 503 MCPA_DC_Voltage_P 0;
BA_ "GenSigTimeoutTime_AGSM" SG_ 503 MCPA_DC_Voltage_P 0;
BA_ "GenSigTimeoutTime_ECM" SG_ 503 MCPA_DC_Voltage_P 0;
BA_ "GenSigTimeoutTime_MCPA" SG_ 503 MCPA_DC_Voltage_P 0;
BA_ "GenSigTimeoutTime_MCPB" SG_ 503 MCPA_DC_Voltage_P 0;
BA_ "GenSigTimeoutTime_TCM" SG_ 503 MCPA_DC_Volt_V_P 0;
BA_ "GenSigTimeoutTime_AGSM" SG_ 503 MCPA_DC_Volt_V_P 0;
BA_ "GenSigTimeoutTime_ECM" SG_ 503 MCPA_DC_Volt_V_P 0;
BA_ "GenSigTimeoutTime_MCPA" SG_ 503 MCPA_DC_Volt_V_P 0;
BA_ "GenSigTimeoutTime_MCPB" SG_ 503 MCPA_DC_Volt_V_P 0;
BA_ "GenSigTimeoutTime_SGCP" SG_ 503 MCPA_DC_Volt_V_P 0;
BA_ "GenSigTimeoutTime_TCM" SG_ 503 MCPA_DC_Current_V_P 0;
BA_ "GenSigTimeoutTime_AGSM" SG_ 503 MCPA_DC_Current_V_P 0;
BA_ "GenSigTimeoutTime_ECM" SG_ 503 MCPA_DC_Current_V_P 0;
BA_ "GenSigTimeoutTime_MCPA" SG_ 503 MCPA_DC_Current_V_P 0;
BA_ "GenSigTimeoutTime_MCPB" SG_ 503 MCPA_DC_Current_V_P 0;
BA_ "GenSigTimeoutTime_SGCP" SG_ 503 MCPA_DC_Current_V_P 0;
BA_ "GenSigTimeoutTime_TCM" SG_ 503 MCPA_DC_Current_P 0;
BA_ "GenSigStartValue" SG_ 503 MCPA_DC_Current_P 16384;
BA_ "GenSigTimeoutTime_AGSM" SG_ 503 MCPA_DC_Current_P 0;
BA_ "GenSigTimeoutTime_ECM" SG_ 503 MCPA_DC_Current_P 0;
BA_ "GenSigTimeoutTime_MCPA" SG_ 503 MCPA_DC_Current_P 0;
BA_ "GenSigTimeoutTime_MCPB" SG_ 503 MCPA_DC_Current_P 0;
BA_ "GenSigTimeoutTime_SGCP" SG_ 503 MCPA_DC_Current_P 0;
BA_ "GenSigTimeoutTime_TCM" SG_ 503 MCPA_CoolantTemp_P 0;
BA_ "GenSigTimeoutTime_AGSM" SG_ 503 MCPA_CoolantTemp_P 0;
BA_ "GenSigTimeoutTime_ECM" SG_ 503 MCPA_CoolantTemp_P 0;
BA_ "GenSigTimeoutTime_MCPA" SG_ 503 MCPA_CoolantTemp_P 0;
BA_ "GenSigTimeoutTime_MCPB" SG_ 503 MCPA_CoolantTemp_P 0;
BA_ "GenSigTimeoutTime_SGCP" SG_ 503 MCPA_CoolantTemp_P 0;
BA_ "GenSigTimeoutTime_TCM" SG_ 503 MC_MCPA_STATUS 0;
BA_ "GenSigTimeoutTime_AGSM" SG_ 503 MC_MCPA_STATUS 0;
BA_ "GenSigTimeoutTime_ECM" SG_ 503 MC_MCPA_STATUS 0;
BA_ "GenSigTimeoutTime_MCPA" SG_ 503 MC_MCPA_STATUS 0;
BA_ "GenSigTimeoutTime_MCPB" SG_ 503 MC_MCPA_STATUS 0;
BA_ "GenSigTimeoutTime_SGCP" SG_ 503 MC_MCPA_STATUS 0;
BA_ "GenSigTimeoutTime_TCM" SG_ 503 CRC_MCPA_STATUS 0;
BA_ "GenSigTimeoutTime_AGSM" SG_ 503 CRC_MCPA_STATUS 0;
BA_ "GenSigTimeoutTime_ECM" SG_ 503 CRC_MCPA_STATUS 0;
BA_ "GenSigTimeoutTime_MCPA" SG_ 503 CRC_MCPA_STATUS 0;
BA_ "GenSigTimeoutTime_MCPB" SG_ 503 CRC_MCPA_STATUS 0;
BA_ "GenSigTimeoutTime_SGCP" SG_ 503 CRC_MCPA_STATUS 0;
BA_ "GenSigTimeoutTime_TCM" SG_ 293 MCPA_Torque_Achieved_V_P 0;
BA_ "GenSigTimeoutTime_AGSM" SG_ 293 MCPA_Torque_Achieved_V_P 0;
BA_ "GenSigTimeoutTime_ECM" SG_ 293 MCPA_Torque_Achieved_V_P 0;
BA_ "GenSigTimeoutTime_MCPA" SG_ 293 MCPA_Torque_Achieved_V_P 0;
BA_ "GenSigTimeoutTime_MCPB" SG_ 293 MCPA_Torque_Achieved_V_P 0;
BA_ "GenSigTimeoutTime_SGCP" SG_ 293 MCPA_Torque_Achieved_V_P 0;
BA_ "GenSigTimeoutTime_TCM" SG_ 293 MCPA_Torque_Achieved_P 0;
BA_ "GenSigStartValue" SG_ 293 MCPA_Torque_Achieved_P 8184;
BA_ "GenSigTimeoutTime_AGSM" SG_ 293 MCPA_Torque_Achieved_P 0;
BA_ "GenSigTimeoutTime_ECM" SG_ 293 MCPA_Torque_Achieved_P 0;
BA_ "GenSigTimeoutTime_MCPA" SG_ 293 MCPA_Torque_Achieved_P 0;
BA_ "GenSigTimeoutTime_MCPB" SG_ 293 MCPA_Torque_Achieved_P 0;
BA_ "GenSigTimeoutTime_SGCP" SG_ 293 MCPA_Torque_Achieved_P 0;
BA_ "GenSigTimeoutTime_TCM" SG_ 293 MCPA_TorqAchieved_AEMD_V_P 0;
BA_ "GenSigTimeoutTime_AGSM" SG_ 293 MCPA_TorqAchieved_AEMD_V_P 0;
BA_ "GenSigTimeoutTime_ECM" SG_ 293 MCPA_TorqAchieved_AEMD_V_P 0;
BA_ "GenSigTimeoutTime_MCPA" SG_ 293 MCPA_TorqAchieved_AEMD_V_P 0;
BA_ "GenSigTimeoutTime_MCPB" SG_ 293 MCPA_TorqAchieved_AEMD_V_P 0;
BA_ "GenSigTimeoutTime_SGCP" SG_ 293 MCPA_TorqAchieved_AEMD_V_P 0;
BA_ "GenSigTimeoutTime_TCM" SG_ 293 MCPA_TorqAchieved_AEMD_P 0;
BA_ "GenSigStartValue" SG_ 293 MCPA_TorqAchieved_AEMD_P 8184;
BA_ "GenSigTimeoutTime_AGSM" SG_ 293 MCPA_TorqAchieved_AEMD_P 0;
BA_ "GenSigTimeoutTime_ECM" SG_ 293 MCPA_TorqAchieved_AEMD_P 0;
BA_ "GenSigTimeoutTime_MCPA" SG_ 293 MCPA_TorqAchieved_AEMD_P 0;
BA_ "GenSigTimeoutTime_MCPB" SG_ 293 MCPA_TorqAchieved_AEMD_P 0;
BA_ "GenSigTimeoutTime_SGCP" SG_ 293 MCPA_TorqAchieved_AEMD_P 0;
BA_ "GenSigTimeoutTime_TCM" SG_ 293 MCPA_SPT_Stat_P 0;
BA_ "GenSigTimeoutTime_AGSM" SG_ 293 MCPA_SPT_Stat_P 0;
BA_ "GenSigTimeoutTime_ECM" SG_ 293 MCPA_SPT_Stat_P 0;
BA_ "GenSigTimeoutTime_MCPA" SG_ 293 MCPA_SPT_Stat_P 0;
BA_ "GenSigTimeoutTime_MCPB" SG_ 293 MCPA_SPT_Stat_P 0;
BA_ "GenSigTimeoutTime_SGCP" SG_ 293 MCPA_SPT_Stat_P 0;
BA_ "GenSigTimeoutTime_TCM" SG_ 293 MCPA_Spd_Lim_P 0;
BA_ "GenSigStartValue" SG_ 293 MCPA_Spd_Lim_P 32767;
BA_ "GenSigTimeoutTime_AGSM" SG_ 293 MCPA_Spd_Lim_P 0;
BA_ "GenSigTimeoutTime_ECM" SG_ 293 MCPA_Spd_Lim_P 0;
BA_ "GenSigTimeoutTime_MCPA" SG_ 293 MCPA_Spd_Lim_P 0;
BA_ "GenSigTimeoutTime_MCPB" SG_ 293 MCPA_Spd_Lim_P 0;
BA_ "GenSigTimeoutTime_SGCP" SG_ 293 MCPA_Spd_Lim_P 0;
BA_ "GenSigTimeoutTime_TCM" SG_ 293 MCPA_RPM_V_P 0;
BA_ "GenSigTimeoutTime_AGSM" SG_ 293 MCPA_RPM_V_P 0;
BA_ "GenSigTimeoutTime_ECM" SG_ 293 MCPA_RPM_V_P 0;
BA_ "GenSigTimeoutTime_MCPA" SG_ 293 MCPA_RPM_V_P 0;
BA_ "GenSigTimeoutTime_MCPB" SG_ 293 MCPA_RPM_V_P 0;
BA_ "GenSigTimeoutTime_SGCP" SG_ 293 MCPA_RPM_V_P 0;
BA_ "GenSigTimeoutTime_TCM" SG_ 293 MCPA_RPM_P 0;
BA_ "GenSigStartValue" SG_ 293 MCPA_RPM_P 32768;
BA_ "GenSigTimeoutTime_AGSM" SG_ 293 MCPA_RPM_P 0;
BA_ "GenSigTimeoutTime_ECM" SG_ 293 MCPA_RPM_P 0;
BA_ "GenSigTimeoutTime_MCPA" SG_ 293 MCPA_RPM_P 0;
BA_ "GenSigTimeoutTime_MCPB" SG_ 293 MCPA_RPM_P 0;
BA_ "GenSigTimeoutTime_SGCP" SG_ 293 MCPA_RPM_P 0;
BA_ "GenSigTimeoutTime_TCM" SG_ 293 MCPA_MtrMinCpbltyTrq_P 0;
BA_ "GenSigStartValue" SG_ 293 MCPA_MtrMinCpbltyTrq_P 8184;
BA_ "GenSigTimeoutTime_AGSM" SG_ 293 MCPA_MtrMinCpbltyTrq_P 0;
BA_ "GenSigTimeoutTime_ECM" SG_ 293 MCPA_MtrMinCpbltyTrq_P 0;
BA_ "GenSigTimeoutTime_MCPA" SG_ 293 MCPA_MtrMinCpbltyTrq_P 0;
BA_ "GenSigTimeoutTime_MCPB" SG_ 293 MCPA_MtrMinCpbltyTrq_P 0;
BA_ "GenSigTimeoutTime_SGCP" SG_ 293 MCPA_MtrMinCpbltyTrq_P 0;
BA_ "GenSigTimeoutTime_TCM" SG_ 293 MCPA_MtrMaxCpbltyTrq_P 0;
BA_ "GenSigStartValue" SG_ 293 MCPA_MtrMaxCpbltyTrq_P 8184;
BA_ "GenSigTimeoutTime_AGSM" SG_ 293 MCPA_MtrMaxCpbltyTrq_P 0;
BA_ "GenSigTimeoutTime_ECM" SG_ 293 MCPA_MtrMaxCpbltyTrq_P 0;
BA_ "GenSigTimeoutTime_MCPA" SG_ 293 MCPA_MtrMaxCpbltyTrq_P 0;
BA_ "GenSigTimeoutTime_MCPB" SG_ 293 MCPA_MtrMaxCpbltyTrq_P 0;
BA_ "GenSigTimeoutTime_SGCP" SG_ 293 MCPA_MtrMaxCpbltyTrq_P 0;
BA_ "GenSigTimeoutTime_TCM" SG_ 293 MCPA_MtrIndex_P 0;
BA_ "GenSigTimeoutTime_AGSM" SG_ 293 MCPA_MtrIndex_P 0;
BA_ "GenSigTimeoutTime_ECM" SG_ 293 MCPA_MtrIndex_P 0;
BA_ "GenSigTimeoutTime_MCPA" SG_ 293 MCPA_MtrIndex_P 0;
BA_ "GenSigTimeoutTime_MCPB" SG_ 293 MCPA_MtrIndex_P 0;
BA_ "GenSigTimeoutTime_SGCP" SG_ 293 MCPA_MtrIndex_P 0;
BA_ "GenSigTimeoutTime_TCM" SG_ 293 MCPA_MinTorq_P 0;
BA_ "GenSigStartValue" SG_ 293 MCPA_MinTorq_P 8184;
BA_ "GenSigTimeoutTime_AGSM" SG_ 293 MCPA_MinTorq_P 0;
BA_ "GenSigTimeoutTime_ECM" SG_ 293 MCPA_MinTorq_P 0;
BA_ "GenSigTimeoutTime_MCPA" SG_ 293 MCPA_MinTorq_P 0;
BA_ "GenSigTimeoutTime_MCPB" SG_ 293 MCPA_MinTorq_P 0;
BA_ "GenSigTimeoutTime_SGCP" SG_ 293 MCPA_MinTorq_P 0;
BA_ "GenSigTimeoutTime_TCM" SG_ 293 MCPA_MaxTorq_P 0;
BA_ "GenSigStartValue" SG_ 293 MCPA_MaxTorq_P 8184;
BA_ "GenSigTimeoutTime_AGSM" SG_ 293 MCPA_MaxTorq_P 0;
BA_ "GenSigTimeoutTime_ECM" SG_ 293 MCPA_MaxTorq_P 0;
BA_ "GenSigTimeoutTime_MCPA" SG_ 293 MCPA_MaxTorq_P 0;
BA_ "GenSigTimeoutTime_MCPB" SG_ 293 MCPA_MaxTorq_P 0;
BA_ "GenSigTimeoutTime_SGCP" SG_ 293 MCPA_MaxTorq_P 0;
BA_ "GenSigTimeoutTime_TCM" SG_ 293 MCPA_Invrtr_State_P 0;
BA_ "GenSigTimeoutTime_AGSM" SG_ 293 MCPA_Invrtr_State_P 0;
BA_ "GenSigTimeoutTime_ECM" SG_ 293 MCPA_Invrtr_State_P 0;
BA_ "GenSigTimeoutTime_MCPA" SG_ 293 MCPA_Invrtr_State_P 0;
BA_ "GenSigTimeoutTime_MCPB" SG_ 293 MCPA_Invrtr_State_P 0;
BA_ "GenSigTimeoutTime_SGCP" SG_ 293 MCPA_Invrtr_State_P 0;
BA_ "GenSigTimeoutTime_TCM" SG_ 293 MCPA_InterlockSts_P 0;
BA_ "GenSigTimeoutTime_AGSM" SG_ 293 MCPA_InterlockSts_P 0;
BA_ "GenSigTimeoutTime_ECM" SG_ 293 MCPA_InterlockSts_P 0;
BA_ "GenSigTimeoutTime_MCPA" SG_ 293 MCPA_InterlockSts_P 0;
BA_ "GenSigTimeoutTime_MCPB" SG_ 293 MCPA_InterlockSts_P 0;
BA_ "GenSigTimeoutTime_SGCP" SG_ 293 MCPA_InterlockSts_P 0;
BA_ "GenSigTimeoutTime_TCM" SG_ 293 MCPA_HV_CnctrOpn_Req_P 0;
BA_ "GenSigTimeoutTime_AGSM" SG_ 293 MCPA_HV_CnctrOpn_Req_P 0;
BA_ "GenSigTimeoutTime_ECM" SG_ 293 MCPA_HV_CnctrOpn_Req_P 0;
BA_ "GenSigTimeoutTime_MCPA" SG_ 293 MCPA_HV_CnctrOpn_Req_P 0;
BA_ "GenSigTimeoutTime_MCPB" SG_ 293 MCPA_HV_CnctrOpn_Req_P 0;
BA_ "GenSigTimeoutTime_SGCP" SG_ 293 MCPA_HV_CnctrOpn_Req_P 0;
BA_ "GenSigTimeoutTime_TCM" SG_ 293 MCPA_Dschrge_Status_P 0;
BA_ "GenSigTimeoutTime_AGSM" SG_ 293 MCPA_Dschrge_Status_P 0;
BA_ "GenSigTimeoutTime_ECM" SG_ 293 MCPA_Dschrge_Status_P 0;
BA_ "GenSigTimeoutTime_MCPA" SG_ 293 MCPA_Dschrge_Status_P 0;
BA_ "GenSigTimeoutTime_MCPB" SG_ 293 MCPA_Dschrge_Status_P 0;
BA_ "GenSigTimeoutTime_SGCP" SG_ 293 MCPA_Dschrge_Status_P 0;
BA_ "GenSigTimeoutTime_TCM" SG_ 293 MCPA_DeratingFactor_P 0;
BA_ "GenSigTimeoutTime_AGSM" SG_ 293 MCPA_DeratingFactor_P 0;
BA_ "GenSigTimeoutTime_ECM" SG_ 293 MCPA_DeratingFactor_P 0;
BA_ "GenSigTimeoutTime_MCPA" SG_ 293 MCPA_DeratingFactor_P 0;
BA_ "GenSigTimeoutTime_MCPB" SG_ 293 MCPA_DeratingFactor_P 0;
BA_ "GenSigTimeoutTime_SGCP" SG_ 293 MCPA_DeratingFactor_P 0;
BA_ "GenSigTimeoutTime_TCM" SG_ 293 MCPA_CpbltySpdDivVolt_P 0;
BA_ "GenSigTimeoutTime_AGSM" SG_ 293 MCPA_CpbltySpdDivVolt_P 0;
BA_ "GenSigTimeoutTime_ECM" SG_ 293 MCPA_CpbltySpdDivVolt_P 0;
BA_ "GenSigTimeoutTime_MCPA" SG_ 293 MCPA_CpbltySpdDivVolt_P 0;
BA_ "GenSigTimeoutTime_MCPB" SG_ 293 MCPA_CpbltySpdDivVolt_P 0;
BA_ "GenSigTimeoutTime_SGCP" SG_ 293 MCPA_CpbltySpdDivVolt_P 0;
BA_ "GenSigTimeoutTime_TCM" SG_ 293 MCPA_AccelRawV_P 0;
BA_ "GenSigTimeoutTime_AGSM" SG_ 293 MCPA_AccelRawV_P 0;
BA_ "GenSigTimeoutTime_ECM" SG_ 293 MCPA_AccelRawV_P 0;
BA_ "GenSigTimeoutTime_MCPA" SG_ 293 MCPA_AccelRawV_P 0;
BA_ "GenSigTimeoutTime_MCPB" SG_ 293 MCPA_AccelRawV_P 0;
BA_ "GenSigTimeoutTime_SGCP" SG_ 293 MCPA_AccelRawV_P 0;
BA_ "GenSigTimeoutTime_TCM" SG_ 293 MCPA_AccelRaw_P 0;
BA_ "GenSigTimeoutTime_AGSM" SG_ 293 MCPA_AccelRaw_P 0;
BA_ "GenSigTimeoutTime_ECM" SG_ 293 MCPA_AccelRaw_P 0;
BA_ "GenSigTimeoutTime_MCPA" SG_ 293 MCPA_AccelRaw_P 0;
BA_ "GenSigTimeoutTime_MCPB" SG_ 293 MCPA_AccelRaw_P 0;
BA_ "GenSigTimeoutTime_SGCP" SG_ 293 MCPA_AccelRaw_P 0;
BA_ "GenSigTimeoutTime_TCM" SG_ 293 MCPA_6SO_Status_P 0;
BA_ "GenSigTimeoutTime_AGSM" SG_ 293 MCPA_6SO_Status_P 0;
BA_ "GenSigTimeoutTime_ECM" SG_ 293 MCPA_6SO_Status_P 0;
BA_ "GenSigTimeoutTime_MCPA" SG_ 293 MCPA_6SO_Status_P 0;
BA_ "GenSigTimeoutTime_MCPB" SG_ 293 MCPA_6SO_Status_P 0;
BA_ "GenSigTimeoutTime_SGCP" SG_ 293 MCPA_6SO_Status_P 0;
BA_ "GenSigTimeoutTime_TCM" SG_ 293 MCPA_3PS_Pos_P 0;
BA_ "GenSigTimeoutTime_AGSM" SG_ 293 MCPA_3PS_Pos_P 0;
BA_ "GenSigTimeoutTime_ECM" SG_ 293 MCPA_3PS_Pos_P 0;
BA_ "GenSigTimeoutTime_MCPA" SG_ 293 MCPA_3PS_Pos_P 0;
BA_ "GenSigTimeoutTime_MCPB" SG_ 293 MCPA_3PS_Pos_P 0;
BA_ "GenSigTimeoutTime_SGCP" SG_ 293 MCPA_3PS_Pos_P 0;
BA_ "GenSigTimeoutTime_TCM" SG_ 293 MC_MCPA_PROPULSION 0;
BA_ "GenSigTimeoutTime_AGSM" SG_ 293 MC_MCPA_PROPULSION 0;
BA_ "GenSigTimeoutTime_ECM" SG_ 293 MC_MCPA_PROPULSION 0;
BA_ "GenSigTimeoutTime_MCPA" SG_ 293 MC_MCPA_PROPULSION 0;
BA_ "GenSigTimeoutTime_MCPB" SG_ 293 MC_MCPA_PROPULSION 0;
BA_ "GenSigTimeoutTime_SGCP" SG_ 293 MC_MCPA_PROPULSION 0;
BA_ "GenSigTimeoutTime_TCM" SG_ 293 CRC_MCPA_PROPULSION 0;
BA_ "GenSigTimeoutTime_AGSM" SG_ 293 CRC_MCPA_PROPULSION 0;
BA_ "GenSigTimeoutTime_ECM" SG_ 293 CRC_MCPA_PROPULSION 0;
BA_ "GenSigTimeoutTime_MCPA" SG_ 293 CRC_MCPA_PROPULSION 0;
BA_ "GenSigTimeoutTime_MCPB" SG_ 293 CRC_MCPA_PROPULSION 0;
BA_ "GenSigTimeoutTime_SGCP" SG_ 293 CRC_MCPA_PROPULSION 0;
BA_ "GenSigTimeoutTime_AGSM" SG_ 297 UDCMin_Unlim_SGCP_P 0;
BA_ "GenSigTimeoutTime_ECM" SG_ 297 UDCMin_Unlim_SGCP_P 0;
BA_ "GenSigTimeoutTime_EVCU2" SG_ 297 UDCMin_Unlim_SGCP_P 0;
BA_ "GenSigTimeoutTime_MCPA" SG_ 297 UDCMin_Unlim_SGCP_P 0;
BA_ "GenSigTimeoutTime_MCPB" SG_ 297 UDCMin_Unlim_SGCP_P 0;
BA_ "GenSigTimeoutTime_TCM" SG_ 297 UDCMin_Unlim_MCPB_P 0;
BA_ "GenSigTimeoutTime_AGSM" SG_ 297 UDCMin_Unlim_MCPB_P 0;
BA_ "GenSigTimeoutTime_ECM" SG_ 297 UDCMin_Unlim_MCPB_P 0;
BA_ "GenSigTimeoutTime_EVCU2" SG_ 297 UDCMin_Unlim_MCPB_P 0;
BA_ "GenSigTimeoutTime_MCPA" SG_ 297 UDCMin_Unlim_MCPB_P 0;
BA_ "GenSigTimeoutTime_SGCP" SG_ 297 UDCMin_Unlim_MCPB_P 0;
BA_ "GenSigTimeoutTime_TCM" SG_ 297 UDCMin_Unlim_MCPA_P 0;
BA_ "GenSigTimeoutTime_AGSM" SG_ 297 UDCMin_Unlim_MCPA_P 0;
BA_ "GenSigTimeoutTime_ECM" SG_ 297 UDCMin_Unlim_MCPA_P 0;
BA_ "GenSigTimeoutTime_EVCU2" SG_ 297 UDCMin_Unlim_MCPA_P 0;
BA_ "GenSigTimeoutTime_MCPB" SG_ 297 UDCMin_Unlim_MCPA_P 0;
BA_ "GenSigTimeoutTime_SGCP" SG_ 297 UDCMin_Unlim_MCPA_P 0;
BA_ "GenSigTimeoutTime_AGSM" SG_ 297 UDCMax_Unlim_SGCP_P 0;
BA_ "GenSigTimeoutTime_ECM" SG_ 297 UDCMax_Unlim_SGCP_P 0;
BA_ "GenSigTimeoutTime_EVCU2" SG_ 297 UDCMax_Unlim_SGCP_P 0;
BA_ "GenSigTimeoutTime_MCPA" SG_ 297 UDCMax_Unlim_SGCP_P 0;
BA_ "GenSigTimeoutTime_MCPB" SG_ 297 UDCMax_Unlim_SGCP_P 0;
BA_ "GenSigTimeoutTime_TCM" SG_ 297 UDCMax_Unlim_MCPB_P 0;
BA_ "GenSigTimeoutTime_AGSM" SG_ 297 UDCMax_Unlim_MCPB_P 0;
BA_ "GenSigTimeoutTime_ECM" SG_ 297 UDCMax_Unlim_MCPB_P 0;
BA_ "GenSigTimeoutTime_EVCU2" SG_ 297 UDCMax_Unlim_MCPB_P 0;
BA_ "GenSigTimeoutTime_MCPA" SG_ 297 UDCMax_Unlim_MCPB_P 0;
BA_ "GenSigTimeoutTime_SGCP" SG_ 297 UDCMax_Unlim_MCPB_P 0;
BA_ "GenSigTimeoutTime_TCM" SG_ 297 UDCMax_Unlim_MCPA_P 0;
BA_ "GenSigTimeoutTime_AGSM" SG_ 297 UDCMax_Unlim_MCPA_P 0;
BA_ "GenSigTimeoutTime_ECM" SG_ 297 UDCMax_Unlim_MCPA_P 0;
BA_ "GenSigTimeoutTime_EVCU2" SG_ 297 UDCMax_Unlim_MCPA_P 0;
BA_ "GenSigTimeoutTime_MCPB" SG_ 297 UDCMax_Unlim_MCPA_P 0;
BA_ "GenSigTimeoutTime_SGCP" SG_ 297 UDCMax_Unlim_MCPA_P 0;
BA_ "GenSigTimeoutTime_AGSM" SG_ 297 TqGrdtLim_SGCP_P 0;
BA_ "GenSigTimeoutTime_ECM" SG_ 297 TqGrdtLim_SGCP_P 0;
BA_ "GenSigTimeoutTime_EVCU2" SG_ 297 TqGrdtLim_SGCP_P 0;
BA_ "GenSigTimeoutTime_MCPA" SG_ 297 TqGrdtLim_SGCP_P 0;
BA_ "GenSigTimeoutTime_MCPB" SG_ 297 TqGrdtLim_SGCP_P 0;
BA_ "GenSigTimeoutTime_TCM" SG_ 297 TqGrdtLim_MCPB_P 0;
BA_ "GenSigTimeoutTime_AGSM" SG_ 297 TqGrdtLim_MCPB_P 0;
BA_ "GenSigTimeoutTime_ECM" SG_ 297 TqGrdtLim_MCPB_P 0;
BA_ "GenSigTimeoutTime_EVCU2" SG_ 297 TqGrdtLim_MCPB_P 0;
BA_ "GenSigTimeoutTime_MCPA" SG_ 297 TqGrdtLim_MCPB_P 0;
BA_ "GenSigTimeoutTime_SGCP" SG_ 297 TqGrdtLim_MCPB_P 0;
BA_ "GenSigTimeoutTime_TCM" SG_ 297 TqGrdtLim_MCPA_P 0;
BA_ "GenSigTimeoutTime_AGSM" SG_ 297 TqGrdtLim_MCPA_P 0;
BA_ "GenSigTimeoutTime_ECM" SG_ 297 TqGrdtLim_MCPA_P 0;
BA_ "GenSigTimeoutTime_EVCU2" SG_ 297 TqGrdtLim_MCPA_P 0;
BA_ "GenSigTimeoutTime_MCPB" SG_ 297 TqGrdtLim_MCPA_P 0;
BA_ "GenSigTimeoutTime_SGCP" SG_ 297 TqGrdtLim_MCPA_P 0;
BA_ "GenSigTimeoutTime_AGSM" SG_ 297 SpdGrdtLim_SGCP_P 0;
BA_ "GenSigTimeoutTime_ECM" SG_ 297 SpdGrdtLim_SGCP_P 0;
BA_ "GenSigTimeoutTime_EVCU2" SG_ 297 SpdGrdtLim_SGCP_P 0;
BA_ "GenSigTimeoutTime_MCPA" SG_ 297 SpdGrdtLim_SGCP_P 0;
BA_ "GenSigTimeoutTime_MCPB" SG_ 297 SpdGrdtLim_SGCP_P 0;
BA_ "GenSigTimeoutTime_TCM" SG_ 297 SpdGrdtLim_MCPB_P 0;
BA_ "GenSigTimeoutTime_AGSM" SG_ 297 SpdGrdtLim_MCPB_P 0;
BA_ "GenSigTimeoutTime_ECM" SG_ 297 SpdGrdtLim_MCPB_P 0;
BA_ "GenSigTimeoutTime_EVCU2" SG_ 297 SpdGrdtLim_MCPB_P 0;
BA_ "GenSigTimeoutTime_MCPA" SG_ 297 SpdGrdtLim_MCPB_P 0;
BA_ "GenSigTimeoutTime_SGCP" SG_ 297 SpdGrdtLim_MCPB_P 0;
BA_ "GenSigTimeoutTime_TCM" SG_ 297 SpdGrdtLim_MCPA_P 0;
BA_ "GenSigTimeoutTime_AGSM" SG_ 297 SpdGrdtLim_MCPA_P 0;
BA_ "GenSigTimeoutTime_ECM" SG_ 297 SpdGrdtLim_MCPA_P 0;
BA_ "GenSigTimeoutTime_EVCU2" SG_ 297 SpdGrdtLim_MCPA_P 0;
BA_ "GenSigTimeoutTime_MCPB" SG_ 297 SpdGrdtLim_MCPA_P 0;
BA_ "GenSigTimeoutTime_SGCP" SG_ 297 SpdGrdtLim_MCPA_P 0;
BA_ "GenSigTimeoutTime_AGSM" SG_ 297 Pwr_Electr_Loop_FlwRate_SGCP_P 0;
BA_ "GenSigTimeoutTime_ECM" SG_ 297 Pwr_Electr_Loop_FlwRate_SGCP_P 0;
BA_ "GenSigTimeoutTime_EVCU2" SG_ 297 Pwr_Electr_Loop_FlwRate_SGCP_P 0;
BA_ "GenSigTimeoutTime_MCPA" SG_ 297 Pwr_Electr_Loop_FlwRate_SGCP_P 0;
BA_ "GenSigTimeoutTime_MCPB" SG_ 297 Pwr_Electr_Loop_FlwRate_SGCP_P 0;
BA_ "GenSigTimeoutTime_TCM" SG_ 297 Pwr_Electr_Loop_FlwRate_MCPB_P 0;
BA_ "GenSigTimeoutTime_AGSM" SG_ 297 Pwr_Electr_Loop_FlwRate_MCPB_P 0;
BA_ "GenSigTimeoutTime_ECM" SG_ 297 Pwr_Electr_Loop_FlwRate_MCPB_P 0;
BA_ "GenSigTimeoutTime_EVCU2" SG_ 297 Pwr_Electr_Loop_FlwRate_MCPB_P 0;
BA_ "GenSigTimeoutTime_MCPA" SG_ 297 Pwr_Electr_Loop_FlwRate_MCPB_P 0;
BA_ "GenSigTimeoutTime_SGCP" SG_ 297 Pwr_Electr_Loop_FlwRate_MCPB_P 0;
BA_ "GenSigTimeoutTime_TCM" SG_ 297 Pwr_Electr_Loop_FlwRate_MCPA_P 0;
BA_ "GenSigTimeoutTime_AGSM" SG_ 297 Pwr_Electr_Loop_FlwRate_MCPA_P 0;
BA_ "GenSigTimeoutTime_ECM" SG_ 297 Pwr_Electr_Loop_FlwRate_MCPA_P 0;
BA_ "GenSigTimeoutTime_EVCU2" SG_ 297 Pwr_Electr_Loop_FlwRate_MCPA_P 0;
BA_ "GenSigTimeoutTime_MCPB" SG_ 297 Pwr_Electr_Loop_FlwRate_MCPA_P 0;
BA_ "GenSigTimeoutTime_SGCP" SG_ 297 Pwr_Electr_Loop_FlwRate_MCPA_P 0;
BA_ "GenSigTimeoutTime_TCM" SG_ 297 MC_INVTARGET_PROPULSION2 0;
BA_ "GenSigTimeoutTime_AGSM" SG_ 297 MC_INVTARGET_PROPULSION2 0;
BA_ "GenSigTimeoutTime_ECM" SG_ 297 MC_INVTARGET_PROPULSION2 0;
BA_ "GenSigTimeoutTime_EVCU2" SG_ 297 MC_INVTARGET_PROPULSION2 0;
BA_ "GenSigStartValue" SG_ 297 EVCU_MotorC_Speed 32768;
BA_ "GenSigTimeoutTime_AGSM" SG_ 297 EVCU_MotorC_Speed 0;
BA_ "GenSigTimeoutTime_ECM" SG_ 297 EVCU_MotorC_Speed 0;
BA_ "GenSigTimeoutTime_EVCU2" SG_ 297 EVCU_MotorC_Speed 0;
BA_ "GenSigTimeoutTime_MCPA" SG_ 297 EVCU_MotorC_Speed 0;
BA_ "GenSigTimeoutTime_MCPB" SG_ 297 EVCU_MotorC_Speed 0;
BA_ "GenSigTimeoutTime_TCM" SG_ 297 EVCU_MotorB_Speed 0;
BA_ "GenSigStartValue" SG_ 297 EVCU_MotorB_Speed 32768;
BA_ "GenSigTimeoutTime_AGSM" SG_ 297 EVCU_MotorB_Speed 0;
BA_ "GenSigTimeoutTime_ECM" SG_ 297 EVCU_MotorB_Speed 0;
BA_ "GenSigTimeoutTime_EVCU2" SG_ 297 EVCU_MotorB_Speed 0;
BA_ "GenSigTimeoutTime_MCPA" SG_ 297 EVCU_MotorB_Speed 0;
BA_ "GenSigTimeoutTime_SGCP" SG_ 297 EVCU_MotorB_Speed 0;
BA_ "GenSigTimeoutTime_TCM" SG_ 297 EVCU_MotorA_Speed 0;
BA_ "GenSigStartValue" SG_ 297 EVCU_MotorA_Speed 32768;
BA_ "GenSigTimeoutTime_AGSM" SG_ 297 EVCU_MotorA_Speed 0;
BA_ "GenSigTimeoutTime_ECM" SG_ 297 EVCU_MotorA_Speed 0;
BA_ "GenSigTimeoutTime_EVCU2" SG_ 297 EVCU_MotorA_Speed 0;
BA_ "GenSigTimeoutTime_MCPB" SG_ 297 EVCU_MotorA_Speed 0;
BA_ "GenSigTimeoutTime_SGCP" SG_ 297 EVCU_MotorA_Speed 0;
BA_ "GenSigTimeoutTime_TCM" SG_ 297 CRC_INVTARGET_PROPULSION2 0;
BA_ "GenSigTimeoutTime_AGSM" SG_ 297 CRC_INVTARGET_PROPULSION2 0;
BA_ "GenSigTimeoutTime_ECM" SG_ 297 CRC_INVTARGET_PROPULSION2 0;
BA_ "GenSigTimeoutTime_EVCU2" SG_ 297 CRC_INVTARGET_PROPULSION2 0;
BA_ "GenSigTimeoutTime_TCM" SG_ 296 VehicleSpeedVSOSig_P 0;
BA_ "GenSigTimeoutTime_AGSM" SG_ 296 VehicleSpeedVSOSig_P 0;
BA_ "GenSigTimeoutTime_ECM" SG_ 296 VehicleSpeedVSOSig_P 0;
BA_ "GenSigTimeoutTime_EVCU2" SG_ 296 VehicleSpeedVSOSig_P 0;
BA_ "GenSigStartValue" SG_ 296 TorqueCommand_SGCP_P 8184;
BA_ "GenSigTimeoutTime_AGSM" SG_ 296 TorqueCommand_SGCP_P 0;
BA_ "GenSigTimeoutTime_ECM" SG_ 296 TorqueCommand_SGCP_P 0;
BA_ "GenSigTimeoutTime_EVCU2" SG_ 296 TorqueCommand_SGCP_P 0;
BA_ "GenSigTimeoutTime_MCPA" SG_ 296 TorqueCommand_SGCP_P 0;
BA_ "GenSigTimeoutTime_MCPB" SG_ 296 TorqueCommand_SGCP_P 0;
BA_ "GenSigTimeoutTime_TCM" SG_ 296 TorqueCommand_MCPB_P 0;
BA_ "GenSigStartValue" SG_ 296 TorqueCommand_MCPB_P 8184;
BA_ "GenSigTimeoutTime_AGSM" SG_ 296 TorqueCommand_MCPB_P 0;
BA_ "GenSigTimeoutTime_ECM" SG_ 296 TorqueCommand_MCPB_P 0;
BA_ "GenSigTimeoutTime_EVCU2" SG_ 296 TorqueCommand_MCPB_P 0;
BA_ "GenSigTimeoutTime_MCPA" SG_ 296 TorqueCommand_MCPB_P 0;
BA_ "GenSigTimeoutTime_SGCP" SG_ 296 TorqueCommand_MCPB_P 0;
BA_ "GenSigTimeoutTime_TCM" SG_ 296 TorqueCommand_MCPA_P 0;
BA_ "GenSigStartValue" SG_ 296 TorqueCommand_MCPA_P 8184;
BA_ "GenSigTimeoutTime_AGSM" SG_ 296 TorqueCommand_MCPA_P 0;
BA_ "GenSigTimeoutTime_ECM" SG_ 296 TorqueCommand_MCPA_P 0;
BA_ "GenSigTimeoutTime_EVCU2" SG_ 296 TorqueCommand_MCPA_P 0;
BA_ "GenSigTimeoutTime_MCPB" SG_ 296 TorqueCommand_MCPA_P 0;
BA_ "GenSigTimeoutTime_SGCP" SG_ 296 TorqueCommand_MCPA_P 0;
BA_ "GenSigStartValue" SG_ 296 TargetMotorRPM_SGCP_P 32768;
BA_ "GenSigTimeoutTime_AGSM" SG_ 296 TargetMotorRPM_SGCP_P 0;
BA_ "GenSigTimeoutTime_ECM" SG_ 296 TargetMotorRPM_SGCP_P 0;
BA_ "GenSigTimeoutTime_EVCU2" SG_ 296 TargetMotorRPM_SGCP_P 0;
BA_ "GenSigTimeoutTime_MCPA" SG_ 296 TargetMotorRPM_SGCP_P 0;
BA_ "GenSigTimeoutTime_MCPB" SG_ 296 TargetMotorRPM_SGCP_P 0;
BA_ "GenSigTimeoutTime_TCM" SG_ 296 TargetMotorRPM_MCPB_P 0;
BA_ "GenSigStartValue" SG_ 296 TargetMotorRPM_MCPB_P 32768;
BA_ "GenSigTimeoutTime_AGSM" SG_ 296 TargetMotorRPM_MCPB_P 0;
BA_ "GenSigTimeoutTime_ECM" SG_ 296 TargetMotorRPM_MCPB_P 0;
BA_ "GenSigTimeoutTime_EVCU2" SG_ 296 TargetMotorRPM_MCPB_P 0;
BA_ "GenSigTimeoutTime_MCPA" SG_ 296 TargetMotorRPM_MCPB_P 0;
BA_ "GenSigTimeoutTime_SGCP" SG_ 296 TargetMotorRPM_MCPB_P 0;
BA_ "GenSigTimeoutTime_TCM" SG_ 296 TargetMotorRPM_MCPA_P 0;
BA_ "GenSigStartValue" SG_ 296 TargetMotorRPM_MCPA_P 32768;
BA_ "GenSigTimeoutTime_AGSM" SG_ 296 TargetMotorRPM_MCPA_P 0;
BA_ "GenSigTimeoutTime_ECM" SG_ 296 TargetMotorRPM_MCPA_P 0;
BA_ "GenSigTimeoutTime_EVCU2" SG_ 296 TargetMotorRPM_MCPA_P 0;
BA_ "GenSigTimeoutTime_MCPB" SG_ 296 TargetMotorRPM_MCPA_P 0;
BA_ "GenSigTimeoutTime_SGCP" SG_ 296 TargetMotorRPM_MCPA_P 0;
BA_ "GenSigTimeoutTime_TCM" SG_ 296 ShiftLeverPosition_P 0;
BA_ "GenSigTimeoutTime_AGSM" SG_ 296 ShiftLeverPosition_P 0;
BA_ "GenSigTimeoutTime_ECM" SG_ 296 ShiftLeverPosition_P 0;
BA_ "GenSigTimeoutTime_EVCU2" SG_ 296 ShiftLeverPosition_P 0;
BA_ "GenSigTimeoutTime_MCPA" SG_ 296 ShiftLeverPosition_P 0;
BA_ "GenSigTimeoutTime_SGCP" SG_ 296 ShiftLeverPosition_P 0;
BA_ "GenSigTimeoutTime_TCM" SG_ 296 ParkCmd_PT_P 0;
BA_ "GenSigTimeoutTime_AGSM" SG_ 296 ParkCmd_PT_P 0;
BA_ "GenSigTimeoutTime_ECM" SG_ 296 ParkCmd_PT_P 0;
BA_ "GenSigTimeoutTime_EVCU2" SG_ 296 ParkCmd_PT_P 0;
BA_ "GenSigTimeoutTime_MCPA" SG_ 296 ParkCmd_PT_P 0;
BA_ "GenSigTimeoutTime_SGCP" SG_ 296 ParkCmd_PT_P 0;
BA_ "GenSigTimeoutTime_AGSM" SG_ 296 Mtr_6SO_Request_SGCP_P 0;
BA_ "GenSigTimeoutTime_ECM" SG_ 296 Mtr_6SO_Request_SGCP_P 0;
BA_ "GenSigTimeoutTime_EVCU2" SG_ 296 Mtr_6SO_Request_SGCP_P 0;
BA_ "GenSigTimeoutTime_MCPA" SG_ 296 Mtr_6SO_Request_SGCP_P 0;
BA_ "GenSigTimeoutTime_MCPB" SG_ 296 Mtr_6SO_Request_SGCP_P 0;
BA_ "GenSigTimeoutTime_TCM" SG_ 296 Mtr_6SO_Request_MCPB_P 0;
BA_ "GenSigTimeoutTime_AGSM" SG_ 296 Mtr_6SO_Request_MCPB_P 0;
BA_ "GenSigTimeoutTime_ECM" SG_ 296 Mtr_6SO_Request_MCPB_P 0;
BA_ "GenSigTimeoutTime_EVCU2" SG_ 296 Mtr_6SO_Request_MCPB_P 0;
BA_ "GenSigTimeoutTime_MCPA" SG_ 296 Mtr_6SO_Request_MCPB_P 0;
BA_ "GenSigTimeoutTime_SGCP" SG_ 296 Mtr_6SO_Request_MCPB_P 0;
BA_ "GenSigTimeoutTime_TCM" SG_ 296 Mtr_6SO_Request_MCPA_P 0;
BA_ "GenSigTimeoutTime_AGSM" SG_ 296 Mtr_6SO_Request_MCPA_P 0;
BA_ "GenSigTimeoutTime_ECM" SG_ 296 Mtr_6SO_Request_MCPA_P 0;
BA_ "GenSigTimeoutTime_EVCU2" SG_ 296 Mtr_6SO_Request_MCPA_P 0;
BA_ "GenSigTimeoutTime_MCPB" SG_ 296 Mtr_6SO_Request_MCPA_P 0;
BA_ "GenSigTimeoutTime_SGCP" SG_ 296 Mtr_6SO_Request_MCPA_P 0;
BA_ "GenSigTimeoutTime_AGSM" SG_ 296 ModeCommand_SGCP_P 0;
BA_ "GenSigTimeoutTime_ECM" SG_ 296 ModeCommand_SGCP_P 0;
BA_ "GenSigTimeoutTime_EVCU2" SG_ 296 ModeCommand_SGCP_P 0;
BA_ "GenSigTimeoutTime_MCPA" SG_ 296 ModeCommand_SGCP_P 0;
BA_ "GenSigTimeoutTime_MCPB" SG_ 296 ModeCommand_SGCP_P 0;
BA_ "GenSigTimeoutTime_TCM" SG_ 296 ModeCommand_MCPB_P 0;
BA_ "GenSigTimeoutTime_AGSM" SG_ 296 ModeCommand_MCPB_P 0;
BA_ "GenSigTimeoutTime_ECM" SG_ 296 ModeCommand_MCPB_P 0;
BA_ "GenSigTimeoutTime_EVCU2" SG_ 296 ModeCommand_MCPB_P 0;
BA_ "GenSigTimeoutTime_MCPA" SG_ 296 ModeCommand_MCPB_P 0;
BA_ "GenSigTimeoutTime_SGCP" SG_ 296 ModeCommand_MCPB_P 0;
BA_ "GenSigTimeoutTime_TCM" SG_ 296 ModeCommand_MCPA_P 0;
BA_ "GenSigTimeoutTime_AGSM" SG_ 296 ModeCommand_MCPA_P 0;
BA_ "GenSigTimeoutTime_ECM" SG_ 296 ModeCommand_MCPA_P 0;
BA_ "GenSigTimeoutTime_EVCU2" SG_ 296 ModeCommand_MCPA_P 0;
BA_ "GenSigTimeoutTime_MCPB" SG_ 296 ModeCommand_MCPA_P 0;
BA_ "GenSigTimeoutTime_SGCP" SG_ 296 ModeCommand_MCPA_P 0;
BA_ "GenSigTimeoutTime_TCM" SG_ 296 MC_INVTARGET_PROPULSION1 0;
BA_ "GenSigTimeoutTime_AGSM" SG_ 296 MC_INVTARGET_PROPULSION1 0;
BA_ "GenSigTimeoutTime_ECM" SG_ 296 MC_INVTARGET_PROPULSION1 0;
BA_ "GenSigTimeoutTime_EVCU2" SG_ 296 MC_INVTARGET_PROPULSION1 0;
BA_ "GenSigTimeoutTime_TCM" SG_ 296 CRC_INVTARGET_PROPULSION1 0;
BA_ "GenSigTimeoutTime_AGSM" SG_ 296 CRC_INVTARGET_PROPULSION1 0;
BA_ "GenSigTimeoutTime_ECM" SG_ 296 CRC_INVTARGET_PROPULSION1 0;
BA_ "GenSigTimeoutTime_EVCU2" SG_ 296 CRC_INVTARGET_PROPULSION1 0;
BA_ "GenSigTimeoutTime_TCM" SG_ 296 CmdIgnSts_P 0;
BA_ "GenSigTimeoutTime_AGSM" SG_ 296 CmdIgnSts_P 0;
BA_ "GenSigTimeoutTime_ECM" SG_ 296 CmdIgnSts_P 0;
BA_ "GenSigTimeoutTime_EVCU2" SG_ 296 CmdIgnSts_P 0;
BA_ "GenSigTimeoutTime_TCM" SG_ 296 BPCM_HV_TractionBusVoltage_P 0;
BA_ "GenSigTimeoutTime_AGSM" SG_ 296 BPCM_HV_TractionBusVoltage_P 0;
BA_ "GenSigTimeoutTime_ECM" SG_ 296 BPCM_HV_TractionBusVoltage_P 0;
BA_ "GenSigTimeoutTime_EVCU2" SG_ 296 BPCM_HV_TractionBusVoltage_P 0;
BA_ "GenSigTimeoutTime_TCM" SG_ 296 BPCM_HV_Trac_Main_Contac_Sts_P 0;
BA_ "GenSigTimeoutTime_AGSM" SG_ 296 BPCM_HV_Trac_Main_Contac_Sts_P 0;
BA_ "GenSigTimeoutTime_ECM" SG_ 296 BPCM_HV_Trac_Main_Contac_Sts_P 0;
BA_ "GenSigTimeoutTime_EVCU2" SG_ 296 BPCM_HV_Trac_Main_Contac_Sts_P 0;
BA_ "GenSigTimeoutTime_AGSM" SG_ 296 AEMD_Sclr_Gn_SGCP_P 0;
BA_ "GenSigTimeoutTime_ECM" SG_ 296 AEMD_Sclr_Gn_SGCP_P 0;
BA_ "GenSigTimeoutTime_EVCU2" SG_ 296 AEMD_Sclr_Gn_SGCP_P 0;
BA_ "GenSigTimeoutTime_MCPA" SG_ 296 AEMD_Sclr_Gn_SGCP_P 0;
BA_ "GenSigTimeoutTime_MCPB" SG_ 296 AEMD_Sclr_Gn_SGCP_P 0;
BA_ "GenSigTimeoutTime_TCM" SG_ 296 AEMD_Sclr_Gn_MCPB_P 0;
BA_ "GenSigTimeoutTime_AGSM" SG_ 296 AEMD_Sclr_Gn_MCPB_P 0;
BA_ "GenSigTimeoutTime_ECM" SG_ 296 AEMD_Sclr_Gn_MCPB_P 0;
BA_ "GenSigTimeoutTime_EVCU2" SG_ 296 AEMD_Sclr_Gn_MCPB_P 0;
BA_ "GenSigTimeoutTime_MCPA" SG_ 296 AEMD_Sclr_Gn_MCPB_P 0;
BA_ "GenSigTimeoutTime_SGCP" SG_ 296 AEMD_Sclr_Gn_MCPB_P 0;
BA_ "GenSigTimeoutTime_TCM" SG_ 296 AEMD_Sclr_Gn_MCPA_P 0;
BA_ "GenSigTimeoutTime_AGSM" SG_ 296 AEMD_Sclr_Gn_MCPA_P 0;
BA_ "GenSigTimeoutTime_ECM" SG_ 296 AEMD_Sclr_Gn_MCPA_P 0;
BA_ "GenSigTimeoutTime_EVCU2" SG_ 296 AEMD_Sclr_Gn_MCPA_P 0;
BA_ "GenSigTimeoutTime_MCPB" SG_ 296 AEMD_Sclr_Gn_MCPA_P 0;
BA_ "GenSigTimeoutTime_SGCP" SG_ 296 AEMD_Sclr_Gn_MCPA_P 0;
BA_ "GenSigStartValue" SG_ 296 AEMD_MinOffset_SGCP_P 8184;
BA_ "GenSigTimeoutTime_AGSM" SG_ 296 AEMD_MinOffset_SGCP_P 0;
BA_ "GenSigTimeoutTime_ECM" SG_ 296 AEMD_MinOffset_SGCP_P 0;
BA_ "GenSigTimeoutTime_EVCU2" SG_ 296 AEMD_MinOffset_SGCP_P 0;
BA_ "GenSigTimeoutTime_MCPA" SG_ 296 AEMD_MinOffset_SGCP_P 0;
BA_ "GenSigTimeoutTime_MCPB" SG_ 296 AEMD_MinOffset_SGCP_P 0;
BA_ "GenSigTimeoutTime_TCM" SG_ 296 AEMD_MinOffset_MCPB_P 0;
BA_ "GenSigStartValue" SG_ 296 AEMD_MinOffset_MCPB_P 8184;
BA_ "GenSigTimeoutTime_AGSM" SG_ 296 AEMD_MinOffset_MCPB_P 0;
BA_ "GenSigTimeoutTime_ECM" SG_ 296 AEMD_MinOffset_MCPB_P 0;
BA_ "GenSigTimeoutTime_EVCU2" SG_ 296 AEMD_MinOffset_MCPB_P 0;
BA_ "GenSigTimeoutTime_MCPA" SG_ 296 AEMD_MinOffset_MCPB_P 0;
BA_ "GenSigTimeoutTime_SGCP" SG_ 296 AEMD_MinOffset_MCPB_P 0;
BA_ "GenSigTimeoutTime_TCM" SG_ 296 AEMD_MinOffset_MCPA_P 0;
BA_ "GenSigStartValue" SG_ 296 AEMD_MinOffset_MCPA_P 8184;
BA_ "GenSigTimeoutTime_AGSM" SG_ 296 AEMD_MinOffset_MCPA_P 0;
BA_ "GenSigTimeoutTime_ECM" SG_ 296 AEMD_MinOffset_MCPA_P 0;
BA_ "GenSigTimeoutTime_EVCU2" SG_ 296 AEMD_MinOffset_MCPA_P 0;
BA_ "GenSigTimeoutTime_MCPB" SG_ 296 AEMD_MinOffset_MCPA_P 0;
BA_ "GenSigTimeoutTime_SGCP" SG_ 296 AEMD_MinOffset_MCPA_P 0;
BA_ "GenSigStartValue" SG_ 296 AEMD_MaxOffset_SGCP_P 8184;
BA_ "GenSigTimeoutTime_AGSM" SG_ 296 AEMD_MaxOffset_SGCP_P 0;
BA_ "GenSigTimeoutTime_ECM" SG_ 296 AEMD_MaxOffset_SGCP_P 0;
BA_ "GenSigTimeoutTime_EVCU2" SG_ 296 AEMD_MaxOffset_SGCP_P 0;
BA_ "GenSigTimeoutTime_MCPA" SG_ 296 AEMD_MaxOffset_SGCP_P 0;
BA_ "GenSigTimeoutTime_MCPB" SG_ 296 AEMD_MaxOffset_SGCP_P 0;
BA_ "GenSigTimeoutTime_TCM" SG_ 296 AEMD_MaxOffset_MCPB_P 0;
BA_ "GenSigStartValue" SG_ 296 AEMD_MaxOffset_MCPB_P 8184;
BA_ "GenSigTimeoutTime_AGSM" SG_ 296 AEMD_MaxOffset_MCPB_P 0;
BA_ "GenSigTimeoutTime_ECM" SG_ 296 AEMD_MaxOffset_MCPB_P 0;
BA_ "GenSigTimeoutTime_EVCU2" SG_ 296 AEMD_MaxOffset_MCPB_P 0;
BA_ "GenSigTimeoutTime_MCPA" SG_ 296 AEMD_MaxOffset_MCPB_P 0;
BA_ "GenSigTimeoutTime_SGCP" SG_ 296 AEMD_MaxOffset_MCPB_P 0;
BA_ "GenSigTimeoutTime_TCM" SG_ 296 AEMD_MaxOffset_MCPA_P 0;
BA_ "GenSigStartValue" SG_ 296 AEMD_MaxOffset_MCPA_P 8184;
BA_ "GenSigTimeoutTime_AGSM" SG_ 296 AEMD_MaxOffset_MCPA_P 0;
BA_ "GenSigTimeoutTime_ECM" SG_ 296 AEMD_MaxOffset_MCPA_P 0;
BA_ "GenSigTimeoutTime_EVCU2" SG_ 296 AEMD_MaxOffset_MCPA_P 0;
BA_ "GenSigTimeoutTime_MCPB" SG_ 296 AEMD_MaxOffset_MCPA_P 0;
BA_ "GenSigTimeoutTime_SGCP" SG_ 296 AEMD_MaxOffset_MCPA_P 0;
BA_ "GenSigTimeoutTime_AGSM" SG_ 296 AEMD_Cutoff_FreqLow_SGCP_P 0;
BA_ "GenSigTimeoutTime_ECM" SG_ 296 AEMD_Cutoff_FreqLow_SGCP_P 0;
BA_ "GenSigTimeoutTime_EVCU2" SG_ 296 AEMD_Cutoff_FreqLow_SGCP_P 0;
BA_ "GenSigTimeoutTime_MCPA" SG_ 296 AEMD_Cutoff_FreqLow_SGCP_P 0;
BA_ "GenSigTimeoutTime_MCPB" SG_ 296 AEMD_Cutoff_FreqLow_SGCP_P 0;
BA_ "GenSigTimeoutTime_TCM" SG_ 296 AEMD_Cutoff_FreqLow_MCPB_P 0;
BA_ "GenSigTimeoutTime_AGSM" SG_ 296 AEMD_Cutoff_FreqLow_MCPB_P 0;
BA_ "GenSigTimeoutTime_ECM" SG_ 296 AEMD_Cutoff_FreqLow_MCPB_P 0;
BA_ "GenSigTimeoutTime_EVCU2" SG_ 296 AEMD_Cutoff_FreqLow_MCPB_P 0;
BA_ "GenSigTimeoutTime_MCPA" SG_ 296 AEMD_Cutoff_FreqLow_MCPB_P 0;
BA_ "GenSigTimeoutTime_SGCP" SG_ 296 AEMD_Cutoff_FreqLow_MCPB_P 0;
BA_ "GenSigTimeoutTime_TCM" SG_ 296 AEMD_Cutoff_FreqLow_MCPA_P 0;
BA_ "GenSigTimeoutTime_AGSM" SG_ 296 AEMD_Cutoff_FreqLow_MCPA_P 0;
BA_ "GenSigTimeoutTime_ECM" SG_ 296 AEMD_Cutoff_FreqLow_MCPA_P 0;
BA_ "GenSigTimeoutTime_EVCU2" SG_ 296 AEMD_Cutoff_FreqLow_MCPA_P 0;
BA_ "GenSigTimeoutTime_MCPB" SG_ 296 AEMD_Cutoff_FreqLow_MCPA_P 0;
BA_ "GenSigTimeoutTime_SGCP" SG_ 296 AEMD_Cutoff_FreqLow_MCPA_P 0;
BA_ "GenSigTimeoutTime_AGSM" SG_ 296 AEMD_Cutoff_FreqHigh_SGCP_P 0;
BA_ "GenSigTimeoutTime_ECM" SG_ 296 AEMD_Cutoff_FreqHigh_SGCP_P 0;
BA_ "GenSigTimeoutTime_EVCU2" SG_ 296 AEMD_Cutoff_FreqHigh_SGCP_P 0;
BA_ "GenSigTimeoutTime_MCPA" SG_ 296 AEMD_Cutoff_FreqHigh_SGCP_P 0;
BA_ "GenSigTimeoutTime_MCPB" SG_ 296 AEMD_Cutoff_FreqHigh_SGCP_P 0;
BA_ "GenSigTimeoutTime_TCM" SG_ 296 AEMD_Cutoff_FreqHigh_MCPB_P 0;
BA_ "GenSigTimeoutTime_AGSM" SG_ 296 AEMD_Cutoff_FreqHigh_MCPB_P 0;
BA_ "GenSigTimeoutTime_ECM" SG_ 296 AEMD_Cutoff_FreqHigh_MCPB_P 0;
BA_ "GenSigTimeoutTime_EVCU2" SG_ 296 AEMD_Cutoff_FreqHigh_MCPB_P 0;
BA_ "GenSigTimeoutTime_MCPA" SG_ 296 AEMD_Cutoff_FreqHigh_MCPB_P 0;
BA_ "GenSigTimeoutTime_SGCP" SG_ 296 AEMD_Cutoff_FreqHigh_MCPB_P 0;
BA_ "GenSigTimeoutTime_TCM" SG_ 296 AEMD_Cutoff_FreqHigh_MCPA_P 0;
BA_ "GenSigTimeoutTime_AGSM" SG_ 296 AEMD_Cutoff_FreqHigh_MCPA_P 0;
BA_ "GenSigTimeoutTime_ECM" SG_ 296 AEMD_Cutoff_FreqHigh_MCPA_P 0;
BA_ "GenSigTimeoutTime_EVCU2" SG_ 296 AEMD_Cutoff_FreqHigh_MCPA_P 0;
BA_ "GenSigTimeoutTime_MCPB" SG_ 296 AEMD_Cutoff_FreqHigh_MCPA_P 0;
BA_ "GenSigTimeoutTime_SGCP" SG_ 296 AEMD_Cutoff_FreqHigh_MCPA_P 0;
VAL_ 1064 SGCP_Temp 255 "SNA" ;
VAL_ 1064 SGCP_Rotor_Temperature 255 "SNA" ;
VAL_ 1064 SGCP_Inverter_Temp 255 "SNA" ;
VAL_ 1064 SGCP_Control_Board_Temperature 255 "SNA" ;
VAL_ 1064 CLrDiagInfo_SGCP 0 "False" 1 "True" ;
VAL_ 1064 Genrtr_PIM_DC_Side_Busbar_Temp 255 "SNA" ;
VAL_ 1064 Genrtr_PIM_AC_Side_Busbar_Temp 255 "SNA" ;
VAL_ 263 OptimdStrtReqdActr 0 "No_Action" 1 "P1f" 2 "P1r" 3 "Starter_12V" 4 "P2" 7 "SNA" ;
VAL_ 263 OptimdEngStrtStpType 0 "No_Action" 1 "Hybrid_Torque_Start" 2 "Engine_Torque_Start" 3 "Low_Power_Start" 4 "Generic_Torque_Start" 5 "Smooth_AutoStart" 6 "Normal_AutoStart" 7 "Aggressive_Autostart" 8 "Generic_Autostart" 9 "Compression_Test" 10 "Green_Engine_Start" 11 "Controlled_Stop" 12 "Immediate_Stop" 13 "Reverse_Autostart" 14 "Clutch_Autostart" 15 "Imp_Autostart" 16 "EM_Autostart" 17 "EM_LowPower" 31 "SNA" ;
VAL_ 263 OptimdEngOnOffCmd 0 "Off_Command" 1 "On_Command" ;
VAL_ 263 Hyb_ProducingTorque 0 "Not_Producing_Torque" 1 "Producing_Torque" ;
VAL_ 263 HCPFuelDisable 0 "Do_Not_Disable_Fuel" 1 "Disable_Fuel" ;
VAL_ 263 PowertrainPrplsnActv_PT 0 "Not_Active" 1 "Active" ;
VAL_ 263 GearEngagedForDisplay_PT 0 "Initialize" 1 "Gear_1st" 2 "Gear_2nd" 3 "Gear_3rd" 4 "Gear_4th" 5 "Gear_5th" 6 "Gear_6th" 7 "Gear_7th" 8 "Gear_8th" 9 "Gear_9th" 12 "Park" 13 "Neutral" 14 "Reverse" 15 "Drive" 16 "Low" 17 "Manual" 18 "Sport_Mode" 31 "SNA" ;
VAL_ 263 GearEngaged_PT 0 "Neutral" 1 "ForwardGear_1" 2 "ForwardGear_2" 3 "ForwardGear_3" 4 "ForwardGear_4" 5 "ForwardGear_5" 6 "ForwardGear_6" 7 "ForwardGear_7" 8 "ForwardGear_8" 9 "ForwardGear_9" 13 "Parking" 14 "ReverseGear" 15 "SNA" ;
VAL_ 263 ParkCmd_PT 0 "No_Request" 1 "Disengage" 2 "Engage" 3 "SNA" ;
VAL_ 263 TransmissionFailSts_PT 0 "Fail_not_present" 1 "Fail_present" ;
VAL_ 263 TerrainModeStat_PT 0 "Auto" 1 "Auto_Fault" 2 "Rock" 3 "Track" 4 "Snow" 5 "Offroad" 6 "Eco" 7 "Corsa" 8 "Sport" 9 "Mud_Sand" 10 "Mud" 11 "Sand" 12 "Valet" 13 "Custom" 14 "Tow" 15 "DRAG" 16 "BAJA" 18 "Drift" 19 "Donut" 31 "SNA" ;
VAL_ 263 ShiftLeverPosition_PT 0 "No_Selection_Active_Or_Available" 1 "Park" 2 "Reverse" 3 "Neutral" 4 "Drive" 5 "Low" 6 "TIP_Autostick" 7 "Plus" 8 "Minus" 9 "Sport" 15 "SNA" ;
VAL_ 263 ShiftLeverLockReq_PT 0 "Not_Active" 1 "Active" ;
VAL_ 263 GearIndicationSts_PT 0 "Normal" 1 "Blocking" ;
VAL_ 263 GasPedalPositionFailSts_PT 0 "Fail_not_present" 1 "Fail_present" ;
VAL_ 263 GasPedalPosition_PT 255 "SNA" ;
VAL_ 263 APCM_Rq_PT 0 "OFF" 1 "ON" 2 "Pending" 3 "SNA" ;
VAL_ 2654486729 CBV_bit0_RepeatMessageReque_0001 0 "Repeat_Message_State_not_requested" 1 "Repeat_Message_State_requested" ;
VAL_ 2654486729 CBV_bit3_NMCoordinatorBit_1_0001 0 "Start_of_synchronized_shutdown_is_not_requested_by_main_coordinator" 1 "Start_of_synchronized_shutdown_is_requested_by_main_coordinator" ;
VAL_ 2654486729 CBV_bit4_ActiveWakeupBit_1E3840C 0 "PassiveWakeup" 1 "ActiveWakeup" ;
VAL_ 2654486729 CBV_bit6_PartialNtwInfBit_1_0001 0 "NM_PDU_contains_no_Partial_Network_request_information" 1 "NM_PDU_contains_Partial_Network_request_information" ;
VAL_ 237 UDCMin_Unlim_SGCP 65535 "SNA" ;
VAL_ 237 UDCMax_Unlim_SGCP 65535 "SNA" ;
VAL_ 237 TqGrdtLim_SGCP 65535 "SNA" ;
VAL_ 237 TorqueCommand_SGCP 8191 "SNA" ;
VAL_ 237 SpdGrdtLim_SGCP 2047 "SNA" ;
VAL_ 237 Mtr_6SO_Request_SGCP 0 "False" 1 "True" ;
VAL_ 237 ModeCommand_SGCP 0 "Inverter_Disabled" 1 "Torque_Control" 2 "Speed_Control" 3 "Active_Discharge" 4 "Disable_Immediate" 5 "Voltage_Control" 6 "Rapid_Shutdown" 7 "Shutdown_Initiated" 8 "ROL_Routine" 9 "Active_Short_Circuit" 15 "SNA" ;
VAL_ 237 Pwr_Electronic_Loop_FlwRate_SGCP 255 "SNA" ;
VAL_ 2654486592 CBV_bit4_ActiveWakeupBit_1E38404 0 "PassiveWakeup" 1 "ActiveWakeup" ;
VAL_ 1811 Real_Time_Validity 0 "Valid" 1 "Not_Valid" ;
VAL_ 1811 Real_Time_Clock -2147483648 "SNA" ;
VAL_ 1070 SGCP_DTC_Stat2 0 "Not_Supported" 1 "Critically_disabled" 2 "No_status_to_report" 3 "Diagnostic_passed" 4 "Diagnostic_failed" 5 "Reset_DTC_status" 7 "SNA" ;
VAL_ 1070 SGCP_DTC_Stat1 0 "Not_Supported" 1 "Critically_disabled" 2 "No_status_to_report" 3 "Diagnostic_passed" 4 "Diagnostic_failed" 5 "Reset_DTC_status" 7 "SNA" ;
VAL_ 1070 SGCP_DTC_Idx2 31 "SNA" ;
VAL_ 1070 SGCP_DTC_Idx1 31 "SNA" ;
VAL_ 1070 SGCP_CalChar 255 "SNA" ;
VAL_ 1070 SGCP_Cal_ID_Idx 63 "SNA" ;
VAL_ 1065 MCPB_DTC_Stat2 0 "Not_Supported" 1 "Critically_disabled" 2 "No_status_to_report" 3 "Diagnostic_passed" 4 "Diagnostic_failed" 5 "Reset_DTC_status" 7 "SNA" ;
VAL_ 1065 MCPB_DTC_Stat1 0 "Not_Supported" 1 "Critically_disabled" 2 "No_status_to_report" 3 "Diagnostic_passed" 4 "Diagnostic_failed" 5 "Reset_DTC_status" 7 "SNA" ;
VAL_ 1065 MCPB_DTC_Idx2 31 "SNA" ;
VAL_ 1065 MCPB_DTC_Idx1 31 "SNA" ;
VAL_ 1065 MCPB_CalChar 255 "SNA" ;
VAL_ 1065 MCPB_Cal_ID_Idx 63 "SNA" ;
VAL_ 1057 MCPA_DTC_Stat2 0 "Not_Supported" 1 "Critically_disabled" 2 "No_status_to_report" 3 "Diagnostic_passed" 4 "Diagnostic_failed" 5 "Reset_DTC_status" 7 "SNA" ;
VAL_ 1057 MCPA_DTC_Stat1 0 "Not_Supported" 1 "Critically_disabled" 2 "No_status_to_report" 3 "Diagnostic_passed" 4 "Diagnostic_failed" 5 "Reset_DTC_status" 7 "SNA" ;
VAL_ 1057 MCPA_DTC_Idx2 31 "SNA" ;
VAL_ 1057 MCPA_DTC_Idx1 31 "SNA" ;
VAL_ 1057 MCPA_CalChar 255 "SNA" ;
VAL_ 1057 MCPA_Cal_ID_Idx 63 "SNA" ;
VAL_ 505 SGCP_DerateReason_P 0 "Reason1" 1 "Reason2" 2 "Reason3" 3 "Reason4" 4 "Reason5" 5 "Reason6" 6 "Reason7" 7 "Reason8" 8 "Reason9" 9 "Reason10" 10 "Reason11" 11 "Reason12" 12 "Reason13" 13 "Reason14" 14 "Reason15" 15 "Reason16" ;
VAL_ 505 SGCP_DC_Voltage_P 1023 "SNA" ;
VAL_ 505 SGCP_DC_Volt_V_P 0 "Valid" 1 "Invalid" ;
VAL_ 505 SGCP_DC_Current_V_P 0 "Valid" 1 "Invalid" ;
VAL_ 505 SGCP_CoolantTemp_P 2047 "SNA" ;
VAL_ 295 SGCP_Torque_Achieved_V_P 0 "Valid" 1 "Invalid" ;
VAL_ 295 SGCP_Torque_Achieved_P 16383 "SNA" ;
VAL_ 295 SGCP_TorqAchieved_AEMD_V_P 0 "Valid" 1 "Invalid" ;
VAL_ 295 SGCP_TorqAchieved_AEMD_P 16383 "SNA" ;
VAL_ 295 SGCP_SPT_Stat_P 0 "Undetermined" 1 "Passed" 2 "Failed" ;
VAL_ 295 SGCP_RPM_V_P 0 "Valid" 1 "Invalid" ;
VAL_ 295 SGCP_RPM_P 65535 "SNA" ;
VAL_ 295 SGCP_MtrMinCpbltyTrq_P 16383 "SNA" ;
VAL_ 295 SGCP_MtrMaxCpbltyTrq_P 16383 "SNA" ;
VAL_ 295 SGCP_MtrIndex_P 31 "SNA" ;
VAL_ 295 SGCP_MinTorq_P 16383 "SNA" ;
VAL_ 295 SGCP_MaxTorq_P 16383 "SNA" ;
VAL_ 295 SGCP_Invrtr_State_P 0 "NORMAL_POWER_STAGE_OFF " 1 "NORMAL_POWER_STAGE_ON " 2 "NORMAL_POWER_STAGE_OVERRIDE" 3 "ACTIVE_DISCHARGE " 4 "INVERTER_FAULTED " 5 "NORMAL_POWER_STAGE_OFF_HV_RQD" 6 "NORMAL_VC_PRIMING" 7 "NORMAL_VC_ON" ;
VAL_ 295 SGCP_InterlockSts_P 0 "Not_Performed" 1 "OK" 2 "Fail" 3 "Invalid" ;
VAL_ 295 SGCP_HV_CnctrOpn_Req_P 0 "False" 1 "True" ;
VAL_ 295 SGCP_Dschrge_Status_P 0 "AD_INDETERMINATE" 1 "AD_INPROGRESSFail" 2 "AD_COMPLETE" 3 "AD_FAILED" ;
VAL_ 295 SGCP_DeratingFactor_P 63 "SNA" ;
VAL_ 295 SGCP_CpbltySpdDivVolt_P 65535 "SNA" ;
VAL_ 295 SGCP_AccelRawV_P 0 "Valid" 1 "Invalid" ;
VAL_ 295 SGCP_6SO_Status_P 0 "3PS" 1 "6SO" 2 "Switching" 3 "SNA" ;
VAL_ 295 SGCP_3PS_Pos_P 0 "False" 1 "True" ;
VAL_ 504 MCPB_DerateReason_P 0 "Reason1" 1 "Reason2" 2 "Reason3" 3 "Reason4" 4 "Reason5" 5 "Reason6" 6 "Reason7" 7 "Reason8" 8 "Reason9" 9 "Reason10" 10 "Reason11" 11 "Reason12" 12 "Reason13" 13 "Reason14" 14 "Reason15" 15 "Reason16" ;
VAL_ 504 MCPB_DC_Voltage_P 1023 "SNA" ;
VAL_ 504 MCPB_DC_Volt_V_P 0 "Valid" 1 "Invalid" ;
VAL_ 504 MCPB_DC_Current_V_P 0 "Valid" 1 "Invalid" ;
VAL_ 504 MCPB_CoolantTemp_P 2047 "SNA" ;
VAL_ 294 PlockFailSts_P 0 "Fault_Not_Present" 1 "Derating" 2 "Retrying" 3 "Non recoverable critical fault" 7 "SNA" ;
VAL_ 294 Plock_PosSensor_P 0 "Init" 1 "Unknown" 2 "Engaged" 3 "Between Engaged and Disengaged" 4 "Tooth to Tooth" 5 "Disengaged" 7 "SNA" ;
VAL_ 294 Plock_MotorPosSts_P 0 "Init" 1 "Unknown" 2 "Engaged Endstop" 3 "Engaged" 4 "Between Engaged and Disengaged" 5 "Disengaged" 6 "Disengaged Endstop" 7 "SNA" ;
VAL_ 294 Plock_fdbk_sts_P 0 "Init" 1 "Engaging" 2 "Engaged" 3 "Disengaging" 4 "Disengaged" 5 "Fault" 7 "SNA" ;
VAL_ 294 MPR_PosSensor_P 0 "Init" 1 "Unknown" 2 "Engaged" 3 "Disengaged" 7 "SNA" ;
VAL_ 294 MCPB_Torque_Achieved_V_P 0 "Valid" 1 "Invalid" ;
VAL_ 294 MCPB_Torque_Achieved_P 16383 "SNA" ;
VAL_ 294 MCPB_TorqAchieved_AEMD_V_P 0 "Valid" 1 "Invalid" ;
VAL_ 294 MCPB_TorqAchieved_AEMD_P 16383 "SNA" ;
VAL_ 294 MCPB_SPT_Stat_P 0 "Undetermined " 1 "Passed" 2 "Failed" ;
VAL_ 294 MCPB_RPM_V_P 0 "Valid" 1 "Invalid" ;
VAL_ 294 MCPB_RPM_P 65535 "SNA" ;
VAL_ 294 MCPB_MtrMinCpbltyTrq_P 16383 "SNA" ;
VAL_ 294 MCPB_MtrMaxCpbltyTrq_P 16383 "SNA" ;
VAL_ 294 MCPB_MtrIndex_P 31 "SNA" ;
VAL_ 294 MCPB_MinTorq_P 16383 "SNA" ;
VAL_ 294 MCPB_MaxTorq_P 16383 "SNA" ;
VAL_ 294 MCPB_Invrtr_State_P 0 "NORMAL_POWER_STAGE_OFF " 1 "NORMAL_POWER_STAGE_ON " 2 "NORMAL_POWER_STAGE_OVERRIDE" 3 "ACTIVE_DISCHARGE " 4 "INVERTER_FAULTED " 5 "NORMAL_POWER_STAGE_OFF_HV_RQD" 6 "NORMAL_VC_PRIMING" 7 "NORMAL_VC_ON" ;
VAL_ 294 MCPB_InterlockSts_P 0 "Not_Performed" 1 "OK" 2 "Fail" 3 "Invalid" ;
VAL_ 294 MCPB_HV_CnctrOpn_Req_P 0 "False" 1 "True" ;
VAL_ 294 MCPB_Dschrge_Status_P 0 "AD_INDETERMINATE" 1 "AD_INPROGRESS" 2 "AD_COMPLETE" 3 "AD_FAILED" ;
VAL_ 294 MCPB_DeratingFactor_P 63 "SNA" ;
VAL_ 294 MCPB_CpbltySpdDivVolt_P 65535 "SNA" ;
VAL_ 294 MCPB_AccelRawV_P 0 "Valid" 1 "Invalid" ;
VAL_ 294 MCPB_6SO_Status_P 0 "ThreePS" 1 "SixSO" 2 "Switching" 3 "SNA" ;
VAL_ 294 MCPB_3PS_Pos_P 0 "False" 1 "True" ;
VAL_ 503 MCPA_DerateReason_P 0 "Reason1" 1 "Reason2" 2 "Reason3" 3 "Reason4" 4 "Reason5" 5 "Reason6" 6 "Reason7" 7 "Reason8" 8 "Reason9" 9 "Reason10" 10 "Reason11" 11 "Reason12" 12 "Reason13" 13 "Reason14" 14 "Reason15" 15 "Reason16" ;
VAL_ 503 MCPA_DC_Voltage_P 1023 "SNA" ;
VAL_ 503 MCPA_DC_Volt_V_P 0 "Valid" 1 "Invalid" ;
VAL_ 503 MCPA_DC_Current_V_P 0 "Valid" 1 "Invalid" ;
VAL_ 503 MCPA_CoolantTemp_P 2047 "SNA" ;
VAL_ 293 MCPA_Torque_Achieved_V_P 0 "Valid" 1 "Invalid" ;
VAL_ 293 MCPA_Torque_Achieved_P 16383 "SNA" ;
VAL_ 293 MCPA_TorqAchieved_AEMD_V_P 0 "Valid" 1 "Invalid" ;
VAL_ 293 MCPA_TorqAchieved_AEMD_P 16383 "SNA" ;
VAL_ 293 MCPA_SPT_Stat_P 0 "Undetermined" 1 "Passed" 2 "Failed" ;
VAL_ 293 MCPA_RPM_V_P 0 "Valid" 1 "Invalid" ;
VAL_ 293 MCPA_RPM_P 65535 "SNA" ;
VAL_ 293 MCPA_MtrMinCpbltyTrq_P 16383 "SNA" ;
VAL_ 293 MCPA_MtrMaxCpbltyTrq_P 16383 "SNA" ;
VAL_ 293 MCPA_MtrIndex_P 31 "SNA" ;
VAL_ 293 MCPA_MinTorq_P 16383 "SNA" ;
VAL_ 293 MCPA_MaxTorq_P 16383 "SNA" ;
VAL_ 293 MCPA_Invrtr_State_P 0 "NORMAL_POWER_STAGE_OFF" 1 "NORMAL_POWER_STAGE_ON" 2 "NORMAL_POWER_STAGE_OVERRIDE" 3 "ACTIVE_DISCHARGE" 4 "INVERTER_FAULTED" 5 "NORMAL_POWER_STAGE_OFF_HV_RQD" 6 "NORMAL_VC_PRIMING" 7 "NORMAL_VC_ON" ;
VAL_ 293 MCPA_InterlockSts_P 0 "Not_Performed" 1 "OK" 2 "Fail" 3 "Invalid" ;
VAL_ 293 MCPA_HV_CnctrOpn_Req_P 0 "False" 1 "True" ;
VAL_ 293 MCPA_Dschrge_Status_P 0 "AD_INDETERMINATE" 1 "AD_INPROGRESS" 2 "AD_COMPLETE" 3 "AD_FAILED" ;
VAL_ 293 MCPA_DeratingFactor_P 63 "SNA" ;
VAL_ 293 MCPA_CpbltySpdDivVolt_P 65535 "SNA" ;
VAL_ 293 MCPA_AccelRawV_P 0 "Valid" 1 "Invalid" ;
VAL_ 293 MCPA_6SO_Status_P 0 "ThreePS" 1 "SixSO" 2 "Switching" 3 "SNA" ;
VAL_ 293 MCPA_3PS_Pos_P 0 "False" 1 "True" ;
VAL_ 297 EVCU_MotorC_Speed 65535 "SNA" ;
VAL_ 297 EVCU_MotorB_Speed 65535 "SNA" ;
VAL_ 297 EVCU_MotorA_Speed 65535 "SNA" ;
VAL_ 296 VehicleSpeedVSOSig_P 8191 "SNA" ;
VAL_ 296 TorqueCommand_SGCP_P 16383 "SNA" ;
VAL_ 296 TorqueCommand_MCPB_P 16383 "SNA" ;
VAL_ 296 TorqueCommand_MCPA_P 16383 "SNA" ;
VAL_ 296 ShiftLeverPosition_P 0 "No_Selection_Active_Or_Available" 1 "Park" 2 "Reverse" 3 "Neutral" 4 "Drive" 5 "Low" 6 "TIP_Autostick" 7 "Plus" 8 "Minus" 9 "Sport" 15 "SNA" ;
VAL_ 296 ParkCmd_PT_P 0 "No_Request" 1 "Disengage" 2 "Engage" 3 "SNA" ;
VAL_ 296 Mtr_6SO_Request_SGCP_P 0 "False" 1 "True" ;
VAL_ 296 Mtr_6SO_Request_MCPB_P 0 "False" 1 "True" ;
VAL_ 296 Mtr_6SO_Request_MCPA_P 0 "False" 1 "True" ;
VAL_ 296 ModeCommand_SGCP_P 0 "Inverter_Disabled" 1 "Torque_Control" 2 "Speed_Control" 3 "Active_Discharge" 4 "Disable_Immediate" 5 "Voltage_Control" 6 "0x6 Rapid_Shutdown" 7 "Shutdown_Initiated" 8 "ROL_Routine" 9 "Active_Short_Circuit" 15 "SNA" ;
VAL_ 296 ModeCommand_MCPB_P 0 "Inverter_Disabled" 1 "Torque_Control" 2 "Speed_Control" 3 "Active_Discharge" 4 "Disable_Immediate" 5 "Voltage_Control" 6 "0x6 Rapid_Shutdown" 7 "Shutdown_Initiated" 8 "ROL_Routine" 9 "Active_Short_Circuit" 15 "SNA" ;
VAL_ 296 ModeCommand_MCPA_P 0 "Inverter_Disabled" 1 "Torque_Control" 2 "Speed_Control" 3 "Active_Discharge" 4 "Disable_Immediate" 5 "Voltage_Control" 6 "0x6 Rapid_Shutdown" 7 "Shutdown_Initiated" 8 "ROL_Routine" 9 "Active_Short_Circuit" 15 "SNA" ;
VAL_ 296 CmdIgnSts_P 0 "Initialization" 1 "IGN_LK" 3 "ACC" 4 "RUN" 5 "START" 7 "SNA" ;
VAL_ 296 BPCM_HV_TractionBusVoltage_P 2047 "SNA" ;
VAL_ 296 BPCM_HV_Trac_Main_Contac_Sts_P 0 "Open" 1 "Closed" 3 "Error_Stuck_Open" 4 "Error_Stuck_Closed" 7 "SNA" ;
VAL_ 296 AEMD_Sclr_Gn_MCPB_P 511 "SNA" ;
VAL_ 296 AEMD_Sclr_Gn_MCPA_P 511 "SNA" ;
VAL_ 296 AEMD_MinOffset_SGCP_P 16383 "SNA" ;
VAL_ 296 AEMD_MinOffset_MCPB_P 16383 "SNA" ;
VAL_ 296 AEMD_MinOffset_MCPA_P 16383 "SNA" ;
VAL_ 296 AEMD_MaxOffset_SGCP_P 16383 "SNA" ;
VAL_ 296 AEMD_MaxOffset_MCPB_P 16383 "SNA" ;
VAL_ 296 AEMD_MaxOffset_MCPA_P 16383 "SNA" ;
SIG_GROUP_ 1064 SGCP_DATA2_Pkt 1 : SGCP_Temp SGCP_Rotor_Temperature SGCP_Inverter_Temp SGCP_Control_Board_Temperature MessageCounter_SGCP_DATA2 CRC_SGCP_DATA2 CLrDiagInfo_SGCP SGCP_Service_Lamp_Request Genrtr_PIM_DC_Side_Busbar_Temp Genrtr_PIM_AC_Side_Busbar_Temp;
SIG_GROUP_ 263 PT_SYSTEM_FD_1_Pkt 1 : OptimdStrtReqdActr OptimdEngStrtStpType OptimdEngOnOffCmd Hyb_ProducingTorque HCPFuelDisable PowertrainPrplsnActv_PT GearEngagedForDisplay_PT GearEngaged_PT ParkCmd_PT TransmissionFailSts_PT TerrainModeStat_PT ShiftLeverPosition_PT ShiftLeverLockReq_PT MessageCounter_PT_SYSTEM_FD_1 GearIndicationSts_PT GasPedalPositionFailSts_PT GasPedalPosition_PT CRC_PT_SYSTEM_FD_1 APCM_Rq_PT;
SIG_GROUP_ 237 INVTARGET2_Pkt 1 : UDCMin_Unlim_SGCP UDCMax_Unlim_SGCP TqGrdtLim_SGCP TorqueCommand_SGCP TargetMotorRPM_SGCP SpdGrdtLim_SGCP Mtr_6SO_Request_SGCP ModeCommand_SGCP MessageCounter_INVTARGET2 CRC_INVTARGET2 AEMD_Sclr_Gn_SGCP AEMD_MinOffset_SGCP AEMD_MaxOffset_SGCP Pwr_Electronic_Loop_FlwRate_SGCP AEMD_Cutoff_FreqLow_SGCP AEMD_Cutoff_FreqHigh_SGCP;
SIG_GROUP_ 216 PT_ENERGY_FD_1_Pkt 1 : BatteryVoltage_Raw_PT;
SIG_GROUP_ 295 SGCP_PROPULSION_Pkt 1 : SGCP_Torque_Achieved_V_P SGCP_Torque_Achieved_P SGCP_TorqAchieved_AEMD_V_P SGCP_TorqAchieved_AEMD_P SGCP_SPT_Stat_P SGCP_Spd_Lim_P SGCP_RPM_V_P SGCP_RPM_P SGCP_MtrMinCpbltyTrq_P SGCP_MtrMaxCpbltyTrq_P SGCP_MtrIndex_P SGCP_MinTorq_P SGCP_MaxTorq_P SGCP_Invrtr_State_P SGCP_InterlockSts_P SGCP_HV_CnctrOpn_Req_P SGCP_Dschrge_Status_P SGCP_DeratingFactor_P SGCP_CpbltySpdDivVolt_P SGCP_AccelRawV_P SGCP_AccelRaw_P SGCP_6SO_Status_P SGCP_3PS_Pos_P MC_SGCP_PROPULSION CRC_SGCP_PROPULSION;
SIG_GROUP_ 294 MCPB_PROPULSION_Pkt 1 : PlockFailSts_P Plock_PosSensor_P Plock_MotorPosSts_P Plock_fdbk_sts_P MPR_PosSensor_P MCPB_Torque_Achieved_V_P MCPB_Torque_Achieved_P MCPB_TorqAchieved_AEMD_V_P MCPB_TorqAchieved_AEMD_P MCPB_SPT_Stat_P MCPB_Spd_Lim_P MCPB_RPM_V_P MCPB_RPM_P MCPB_MtrMinCpbltyTrq_P MCPB_MtrMaxCpbltyTrq_P MCPB_MtrIndex_P MCPB_MinTorq_P MCPB_MaxTorq_P MCPB_Invrtr_State_P MCPB_InterlockSts_P MCPB_HV_CnctrOpn_Req_P MCPB_Dschrge_Status_P MCPB_DeratingFactor_P MCPB_CpbltySpdDivVolt_P MCPB_AccelRawV_P MCPB_AccelRaw_P MCPB_6SO_Status_P MCPB_3PS_Pos_P MC_MCPB_PROPULSION CRC_MCPB_PROPULSION;
SIG_GROUP_ 293 MCPA_PROPULSION_Pkt 1 : MCPA_Torque_Achieved_V_P MCPA_Torque_Achieved_P MCPA_TorqAchieved_AEMD_V_P MCPA_TorqAchieved_AEMD_P MCPA_SPT_Stat_P MCPA_Spd_Lim_P MCPA_RPM_V_P MCPA_RPM_P MCPA_MtrMinCpbltyTrq_P MCPA_MtrMaxCpbltyTrq_P MCPA_MtrIndex_P MCPA_MinTorq_P MCPA_MaxTorq_P MCPA_Invrtr_State_P MCPA_InterlockSts_P MCPA_HV_CnctrOpn_Req_P MCPA_Dschrge_Status_P MCPA_DeratingFactor_P MCPA_CpbltySpdDivVolt_P MCPA_AccelRawV_P MCPA_AccelRaw_P MCPA_6SO_Status_P MCPA_3PS_Pos_P MC_MCPA_PROPULSION CRC_MCPA_PROPULSION;
SIG_GROUP_ 297 INVTARGET_PROPULSION2_Pkt 1 : UDCMin_Unlim_SGCP_P UDCMin_Unlim_MCPB_P UDCMin_Unlim_MCPA_P UDCMax_Unlim_SGCP_P UDCMax_Unlim_MCPB_P UDCMax_Unlim_MCPA_P TqGrdtLim_SGCP_P TqGrdtLim_MCPB_P TqGrdtLim_MCPA_P SpdGrdtLim_SGCP_P SpdGrdtLim_MCPB_P SpdGrdtLim_MCPA_P Pwr_Electr_Loop_FlwRate_SGCP_P Pwr_Electr_Loop_FlwRate_MCPB_P Pwr_Electr_Loop_FlwRate_MCPA_P MC_INVTARGET_PROPULSION2 EVCU_MotorC_Speed EVCU_MotorB_Speed EVCU_MotorA_Speed CRC_INVTARGET_PROPULSION2;
SIG_GROUP_ 296 INVTARGET_PROPULSION1_Pkt 1 : VehicleSpeedVSOSig_P TorqueCommand_SGCP_P TorqueCommand_MCPB_P TorqueCommand_MCPA_P TargetMotorRPM_SGCP_P TargetMotorRPM_MCPB_P TargetMotorRPM_MCPA_P ShiftLeverPosition_P ParkCmd_PT_P Mtr_6SO_Request_SGCP_P Mtr_6SO_Request_MCPB_P Mtr_6SO_Request_MCPA_P ModeCommand_SGCP_P ModeCommand_MCPB_P ModeCommand_MCPA_P MC_INVTARGET_PROPULSION1 CRC_INVTARGET_PROPULSION1 CmdIgnSts_P BPCM_HV_TractionBusVoltage_P BPCM_HV_Trac_Main_Contac_Sts_P AEMD_Sclr_Gn_SGCP_P AEMD_Sclr_Gn_MCPB_P AEMD_Sclr_Gn_MCPA_P AEMD_MinOffset_SGCP_P AEMD_MinOffset_MCPB_P AEMD_MinOffset_MCPA_P AEMD_MaxOffset_SGCP_P AEMD_MaxOffset_MCPB_P AEMD_MaxOffset_MCPA_P AEMD_Cutoff_FreqLow_SGCP_P AEMD_Cutoff_FreqLow_MCPB_P AEMD_Cutoff_FreqLow_MCPA_P AEMD_Cutoff_FreqHigh_SGCP_P AEMD_Cutoff_FreqHigh_MCPB_P AEMD_Cutoff_FreqHigh_MCPA_P;
